VERSION ""

NS_ :

BS_:

BU_: Receiver ChassisBus VehicleBus PartyBus

BO_ 12 ID00CUI_status: 8 VehicleBus
 SG_ UI_audioActive : 1|1@1+ (1,0) [0|1] ""  Receiver
 SG_ UI_autopilotTrial : 12|2@1+ (1,0) [0|3] ""  Receiver
 SG_ UI_bluetoothActive : 2|1@1+ (1,0) [0|1] ""  Receiver
 SG_ UI_cameraActive : 41|1@1+ (1,0) [0|1] ""  Receiver
 SG_ UI_cellActive : 3|1@1+ (1,0) [0|1] ""  Receiver
 SG_ UI_cellConnected : 10|1@1+ (1,0) [0|1] ""  Receiver
 SG_ UI_cellNetworkTechnology : 19|4@1+ (1,0) [0|15] ""  Receiver
 SG_ UI_cellReceiverPower : 24|8@1+ (1,-128) [-128|127] "dB"  Receiver
 SG_ UI_cellSignalBars : 42|3@1+ (1,0) [0|7] ""  Receiver
 SG_ UI_cpuTemperature : 56|8@1- (1,40) [-20|100] "C"  Receiver
 SG_ UI_developmentCar : 40|1@1+ (1,0) [0|1] ""  Receiver
 SG_ UI_displayOn : 5|1@1+ (1,0) [0|1] ""  Receiver
 SG_ UI_displayReady : 4|1@1+ (1,0) [0|1] ""  Receiver
 SG_ UI_factoryReset : 14|2@1+ (1,0) [0|3] ""  Receiver
 SG_ UI_falseTouchCounter : 32|8@1+ (1,0) [0|255] "1"  Receiver
 SG_ UI_gpsActive : 16|1@1+ (1,0) [0|1] ""  Receiver
 SG_ UI_pcbTemperature : 48|8@1- (1,40) [-20|100] "C"  Receiver
 SG_ UI_radioActive : 18|1@1+ (1,0) [0|1] ""  Receiver
 SG_ UI_readyForDrive : 9|1@1+ (1,0) [0|1] ""  Receiver
 SG_ UI_screenshotActive : 17|1@1+ (1,0) [0|1] ""  Receiver
 SG_ UI_systemActive : 8|1@1+ (1,0) [0|1] ""  Receiver
 SG_ UI_touchActive : 0|1@1+ (1,0) [0|1] ""  Receiver
 SG_ UI_vpnActive : 11|1@1+ (1,0) [0|1] ""  Receiver
 SG_ UI_wifiActive : 6|1@1+ (1,0) [0|1] ""  Receiver
 SG_ UI_wifiConnected : 7|1@1+ (1,0) [0|1] ""  Receiver

BO_ 851 ID353UI_status: 8 VehicleBus
 SG_ UI_audioActive : 1|1@1+ (1,0) [0|1] ""  Receiver
 SG_ UI_autopilotTrial : 12|2@1+ (1,0) [0|3] ""  Receiver
 SG_ UI_bluetoothActive : 2|1@1+ (1,0) [0|1] ""  Receiver
 SG_ UI_cameraActive : 41|1@1+ (1,0) [0|1] ""  Receiver
 SG_ UI_cellActive : 3|1@1+ (1,0) [0|1] ""  Receiver
 SG_ UI_cellConnected : 10|1@1+ (1,0) [0|1] ""  Receiver
 SG_ UI_cellNetworkTechnology : 19|4@1+ (1,0) [0|15] ""  Receiver
 SG_ UI_cellReceiverPower : 24|8@1+ (1,-128) [-128|127] "dB"  Receiver
 SG_ UI_cellSignalBars : 42|3@1+ (1,0) [0|7] ""  Receiver
 SG_ UI_cpuTemperature : 56|8@1- (1,40) [-20|100] "C"  Receiver
 SG_ UI_developmentCar : 40|1@1+ (1,0) [0|1] ""  Receiver
 SG_ UI_displayOn : 5|1@1+ (1,0) [0|1] ""  Receiver
 SG_ UI_displayReady : 4|1@1+ (1,0) [0|1] ""  Receiver
 SG_ UI_factoryReset : 14|2@1+ (1,0) [0|3] ""  Receiver
 SG_ UI_falseTouchCounter : 32|8@1+ (1,0) [0|255] "1"  Receiver
 SG_ UI_gpsActive : 16|1@1+ (1,0) [0|1] ""  Receiver
 SG_ UI_pcbTemperature : 48|8@1- (1,40) [-20|100] "C"  Receiver
 SG_ UI_radioActive : 18|1@1+ (1,0) [0|1] ""  Receiver
 SG_ UI_readyForDrive : 9|1@1+ (1,0) [0|1] ""  Receiver
 SG_ UI_screenshotActive : 17|1@1+ (1,0) [0|1] ""  Receiver
 SG_ UI_systemActive : 8|1@1+ (1,0) [0|1] ""  Receiver
 SG_ UI_touchActive : 0|1@1+ (1,0) [0|1] ""  Receiver
 SG_ UI_vpnActive : 11|1@1+ (1,0) [0|1] ""  Receiver
 SG_ UI_wifiActive : 6|1@1+ (1,0) [0|1] ""  Receiver
 SG_ UI_wifiConnected : 7|1@1+ (1,0) [0|1] ""  Receiver

BO_ 22 ID016DI_bmsRequest: 1 VehicleBus
 SG_ DI_bmsOpenContactorsRequest : 4|1@1+ (1,0) [0|1] ""  Receiver
 SG_ DI_bmsRequestInterfaceVersion : 0|4@1+ (1,0) [0|15] ""  Receiver

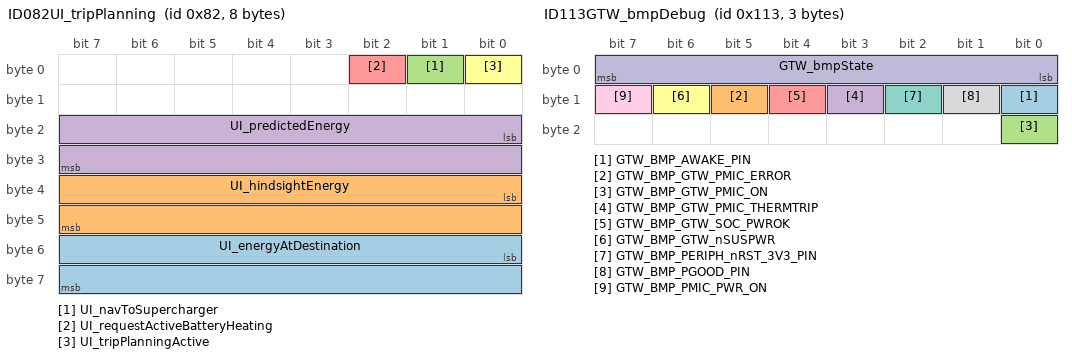
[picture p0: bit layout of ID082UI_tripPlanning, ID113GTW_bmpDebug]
BO_ 130 ID082UI_tripPlanning: 8 VehicleBus
 SG_ UI_energyAtDestination : 48|16@1- (0.01,0) [-327.67|327.67] "kWh"  Receiver
 SG_ UI_hindsightEnergy : 32|16@1- (0.01,0) [-327.67|327.67] "kWh"  Receiver
 SG_ UI_navToSupercharger : 1|1@1+ (1,0) [0|1] ""  Receiver
 SG_ UI_predictedEnergy : 16|16@1- (0.01,0) [-327.67|327.67] "kWh"  Receiver
 SG_ UI_requestActiveBatteryHeating : 2|1@1+ (1,0) [0|1] ""  Receiver
 SG_ UI_tripPlanningActive : 0|1@1+ (1,0) [0|1] ""  Receiver

BO_ 258 ID102VCLEFT_doorStatus: 8 VehicleBus
 SG_ VCLEFT_frontHandlePWM : 16|7@1+ (1,0) [0|100] "%"  Receiver
 SG_ VCLEFT_frontHandlePulled : 10|1@1+ (1,0) [0|1] ""  Receiver
 SG_ VCLEFT_frontHandlePulledPersist : 62|1@1+ (1,0) [0|1] ""  Receiver
 SG_ VCLEFT_frontIntSwitchPressed : 31|1@1+ (1,0) [0|1] ""  Receiver
 SG_ VCLEFT_frontLatchStatus : 0|4@1+ (1,0) [0|8] ""  Receiver
 SG_ VCLEFT_frontLatchSwitch : 8|1@1+ (1,0) [0|1] ""  Receiver
 SG_ VCLEFT_frontRelActuatorSwitch : 12|1@1+ (1,0) [0|1] ""  Receiver
 SG_ VCLEFT_mirrorDipped : 61|1@1+ (1,0) [0|1] ""  Receiver
 SG_ VCLEFT_mirrorFoldState : 52|3@1+ (1,0) [0|4] ""  Receiver
 SG_ VCLEFT_mirrorHeatState : 58|3@1+ (1,0) [0|4] ""  Receiver
 SG_ VCLEFT_mirrorRecallState : 55|3@1+ (1,0) [0|5] ""  Receiver
 SG_ VCLEFT_mirrorState : 49|3@1+ (1,0) [0|4] ""  Receiver
 SG_ VCLEFT_mirrorTiltXPosition : 33|8@1+ (0.02,0) [0|5] "V"  Receiver
 SG_ VCLEFT_mirrorTiltYPosition : 41|8@1+ (0.02,0) [0|5] "V"  Receiver
 SG_ VCLEFT_rearHandlePWM : 24|7@1+ (1,0) [0|100] "%"  Receiver
 SG_ VCLEFT_rearHandlePulled : 11|1@1+ (1,0) [0|1] ""  Receiver
 SG_ VCLEFT_rearIntSwitchPressed : 32|1@1+ (1,0) [0|1] ""  Receiver
 SG_ VCLEFT_rearLatchStatus : 4|4@1+ (1,0) [0|8] ""  Receiver
 SG_ VCLEFT_rearLatchSwitch : 9|1@1+ (1,0) [0|1] ""  Receiver
 SG_ VCLEFT_rearRelActuatorSwitch : 13|1@1+ (1,0) [0|1] ""  Receiver

BO_ 259 ID103VCRIGHT_doorStatus: 8 VehicleBus
 SG_ VCRIGHT_frontHandlePWM : 14|7@1+ (1,0) [0|100] "%"  Receiver
 SG_ VCRIGHT_frontHandlePulled : 10|1@1+ (1,0) [0|1] ""  Receiver
 SG_ VCRIGHT_frontHandlePulledPersist : 30|1@1+ (1,0) [0|1] ""  Receiver
 SG_ VCRIGHT_frontIntSwitchPressed : 31|1@1+ (1,0) [0|1] ""  Receiver
 SG_ VCRIGHT_frontLatchStatus : 0|4@1+ (1,0) [0|8] ""  Receiver
 SG_ VCRIGHT_frontLatchSwitch : 8|1@1+ (1,0) [0|1] ""  Receiver
 SG_ VCRIGHT_frontRelActuatorSwitch : 12|1@1+ (1,0) [0|1] ""  Receiver
 SG_ VCRIGHT_mirrorDipped : 63|1@1+ (1,0) [0|1] ""  Receiver
 SG_ VCRIGHT_mirrorFoldState : 52|3@1+ (1,0) [0|4] ""  Receiver
 SG_ VCRIGHT_mirrorRecallState : 60|3@1+ (1,0) [0|5] ""  Receiver
 SG_ VCRIGHT_mirrorState : 49|3@1+ (1,0) [0|4] ""  Receiver
 SG_ VCRIGHT_mirrorTiltXPosition : 33|8@1+ (0.02,0) [0|5] "V"  Receiver
 SG_ VCRIGHT_mirrorTiltYPosition : 41|8@1+ (0.02,0) [0|5] "V"  Receiver
 SG_ VCRIGHT_rearHandlePWM : 21|7@1+ (1,0) [0|100] "%"  Receiver
 SG_ VCRIGHT_rearHandlePulled : 11|1@1+ (1,0) [0|1] ""  Receiver
 SG_ VCRIGHT_rearIntSwitchPressed : 32|1@1+ (1,0) [0|1] ""  Receiver
 SG_ VCRIGHT_rearLatchStatus : 4|4@1+ (1,0) [0|8] ""  Receiver
 SG_ VCRIGHT_rearLatchSwitch : 9|1@1+ (1,0) [0|1] ""  Receiver
 SG_ VCRIGHT_rearRelActuatorSwitch : 13|1@1+ (1,0) [0|1] ""  Receiver
 SG_ VCRIGHT_reservedForBackCompat : 28|2@1+ (1,0) [0|3] ""  Receiver
 SG_ VCRIGHT_trunkLatchStatus : 56|4@1+ (1,0) [0|8] ""  Receiver

BO_ 275 ID113GTW_bmpDebug: 3 VehicleBus
 SG_ GTW_BMP_AWAKE_PIN : 8|1@1+ (1,0) [0|1] ""  Receiver
 SG_ GTW_BMP_GTW_PMIC_ERROR : 13|1@1+ (1,0) [0|1] ""  Receiver
 SG_ GTW_BMP_GTW_PMIC_ON : 16|1@1+ (1,0) [0|1] ""  Receiver
 SG_ GTW_BMP_GTW_PMIC_THERMTRIP : 11|1@1+ (1,0) [0|1] ""  Receiver
 SG_ GTW_BMP_GTW_SOC_PWROK : 12|1@1+ (1,0) [0|1] ""  Receiver
 SG_ GTW_BMP_GTW_nSUSPWR : 14|1@1+ (1,0) [0|1] ""  Receiver
 SG_ GTW_BMP_PERIPH_nRST_3V3_PIN : 10|1@1+ (1,0) [0|1] ""  Receiver
 SG_ GTW_BMP_PGOOD_PIN : 9|1@1+ (1,0) [0|1] ""  Receiver
 SG_ GTW_BMP_PMIC_PWR_ON : 15|1@1+ (1,0) [0|1] ""  Receiver
 SG_ GTW_bmpState : 7|8@0+ (1,0) [0|255] ""  Receiver

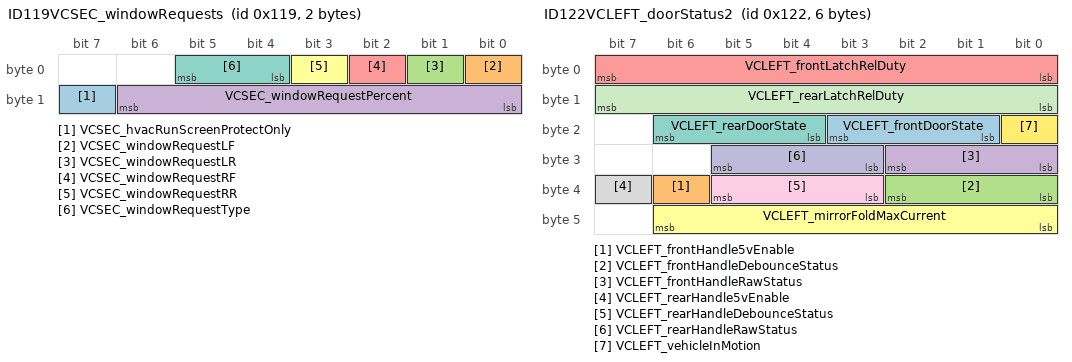
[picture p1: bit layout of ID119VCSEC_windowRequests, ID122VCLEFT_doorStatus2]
BO_ 281 ID119VCSEC_windowRequests: 2 VehicleBus
 SG_ VCSEC_hvacRunScreenProtectOnly : 15|1@1+ (1,0) [0|1] ""  Receiver
 SG_ VCSEC_windowRequestLF : 0|1@1+ (1,0) [0|1] ""  Receiver
 SG_ VCSEC_windowRequestLR : 1|1@1+ (1,0) [0|1] ""  Receiver
 SG_ VCSEC_windowRequestPercent : 8|7@1+ (1,0) [0|127] ""  Receiver
 SG_ VCSEC_windowRequestRF : 2|1@1+ (1,0) [0|1] ""  Receiver
 SG_ VCSEC_windowRequestRR : 3|1@1+ (1,0) [0|1] ""  Receiver
 SG_ VCSEC_windowRequestType : 4|2@1+ (1,0) [0|3] ""  Receiver

BO_ 290 ID122VCLEFT_doorStatus2: 6 VehicleBus
 SG_ VCLEFT_frontDoorState : 17|3@1+ (1,0) [0|4] ""  Receiver
 SG_ VCLEFT_frontHandle5vEnable : 38|1@1+ (1,0) [0|1] ""  Receiver
 SG_ VCLEFT_frontHandleDebounceStatus : 32|3@1+ (1,0) [0|5] ""  Receiver
 SG_ VCLEFT_frontHandleRawStatus : 24|3@1+ (1,0) [0|5] ""  Receiver
 SG_ VCLEFT_frontLatchRelDuty : 0|8@1+ (1,0) [0|255] "%"  Receiver
 SG_ VCLEFT_mirrorFoldMaxCurrent : 40|7@1- (0.046,0) [-2.944|2.898] "A"  Receiver
 SG_ VCLEFT_rearDoorState : 20|3@1+ (1,0) [0|4] ""  Receiver
 SG_ VCLEFT_rearHandle5vEnable : 39|1@1+ (1,0) [0|1] ""  Receiver
 SG_ VCLEFT_rearHandleDebounceStatus : 35|3@1+ (1,0) [0|5] ""  Receiver
 SG_ VCLEFT_rearHandleRawStatus : 27|3@1+ (1,0) [0|5] ""  Receiver
 SG_ VCLEFT_rearLatchRelDuty : 8|8@1+ (1,0) [0|255] "%"  Receiver
 SG_ VCLEFT_vehicleInMotion : 16|1@1+ (1,0) [0|1] ""  Receiver

BO_ 291 ID123UI_alertMatrix1: 8 VehicleBus
 SG_ UI_a001_DriverDoorOpen : 0|1@1+ (1,0) [0|1] ""  Receiver
 SG_ UI_a002_DoorOpen : 1|1@1+ (1,0) [0|1] ""  Receiver
 SG_ UI_a003_TrunkOpen : 2|1@1+ (1,0) [0|1] ""  Receiver
 SG_ UI_a004_FrunkOpen : 3|1@1+ (1,0) [0|1] ""  Receiver
 SG_ UI_a005_HeadlightsOnDoorOpen : 4|1@1+ (1,0) [0|1] ""  Receiver
 SG_ UI_a006_RemoteServiceAlert : 5|1@1+ (1,0) [0|1] ""  Receiver
 SG_ UI_a007_SoftPackConfigMismatch : 6|1@1+ (1,0) [0|1] ""  Receiver
 SG_ UI_a008_TouchScreenError : 7|1@1+ (1,0) [0|1] ""  Receiver
 SG_ UI_a009_SquashfsError : 8|1@1+ (1,0) [0|1] ""  Receiver
 SG_ UI_a010_MapsMissing : 9|1@1+ (1,0) [0|1] ""  Receiver
 SG_ UI_a011_IncorrectMap : 10|1@1+ (1,0) [0|1] ""  Receiver
 SG_ UI_a012_NotOnPrivateProperty : 11|1@1+ (1,0) [0|1] ""  Receiver
 SG_ UI_a013_TPMSHardWarning : 12|1@1+ (1,0) [0|1] ""  Receiver
 SG_ UI_a014_TPMSSoftWarning : 13|1@1+ (1,0) [0|1] ""  Receiver
 SG_ UI_a015_TPMSOverPressureWarning : 14|1@1+ (1,0) [0|1] ""  Receiver
 SG_ UI_a016_TPMSTemperatureWarning : 15|1@1+ (1,0) [0|1] ""  Receiver
 SG_ UI_a017_TPMSSystemFault : 16|1@1+ (1,0) [0|1] ""  Receiver
 SG_ UI_a018_SlipStartOn : 17|1@1+ (1,0) [0|1] ""  Receiver
 SG_ UI_a019_ParkBrakeFault : 18|1@1+ (1,0) [0|1] ""  Receiver
 SG_ UI_a020_SteeringReduced : 19|1@1+ (1,0) [0|1] ""  Receiver
 SG_ UI_a021_RearSeatbeltUnbuckled : 20|1@1+ (1,0) [0|1] ""  Receiver
 SG_ UI_a022_ApeFusesEtc : 21|1@1+ (1,0) [0|1] ""  Receiver
 SG_ UI_a023_CellInternetCheckFailed : 22|1@1+ (1,0) [0|1] ""  Receiver
 SG_ UI_a024_WifiInternetCheckFailed : 23|1@1+ (1,0) [0|1] ""  Receiver
 SG_ UI_a025_WifiOnlineCheckFailed : 24|1@1+ (1,0) [0|1] ""  Receiver
 SG_ UI_a026_ModemResetLoopDetected : 25|1@1+ (1,0) [0|1] ""  Receiver
 SG_ UI_a027_AutoSteerMIA : 26|1@1+ (1,0) [0|1] ""  Receiver
 SG_ UI_a028_FrontTrunkPopupClosed : 27|1@1+ (1,0) [0|1] ""  Receiver
 SG_ UI_a029_ModemMIA : 28|1@1+ (1,0) [0|1] ""  Receiver
 SG_ UI_a030_ModemVMCrash : 29|1@1+ (1,0) [0|1] ""  Receiver
 SG_ UI_a031_BrakeFluidLow : 30|1@1+ (1,0) [0|1] ""  Receiver
 SG_ UI_a032_CellModemRecoveryResets : 31|1@1+ (1,0) [0|1] ""  Receiver
 SG_ UI_a033_ApTrialExpired : 32|1@1+ (1,0) [0|1] ""  Receiver
 SG_ UI_a034_WakeupProblem : 33|1@1+ (1,0) [0|1] ""  Receiver
 SG_ UI_a035_AudioWatchdogKernelError : 34|1@1+ (1,0) [0|1] ""  Receiver
 SG_ UI_a036_AudioWatchdogHfpError : 35|1@1+ (1,0) [0|1] ""  Receiver
 SG_ UI_a037_AudioWatchdogXrunStormEr : 36|1@1+ (1,0) [0|1] ""  Receiver
 SG_ UI_a038_AudioWatchdogA2bI2cLocku : 37|1@1+ (1,0) [0|1] ""  Receiver
 SG_ UI_a039_AudioA2bNeedRediscovery : 38|1@1+ (1,0) [0|1] ""  Receiver
 SG_ UI_a040_HomelinkTransmit : 39|1@1+ (1,0) [0|1] ""  Receiver
 SG_ UI_a041_AudioDmesgXrun : 40|1@1+ (1,0) [0|1] ""  Receiver
 SG_ UI_a042_AudioDmesgRtThrottling : 41|1@1+ (1,0) [0|1] ""  Receiver
 SG_ UI_a043_InvalidMapDataOverride : 42|1@1+ (1,0) [0|1] ""  Receiver
 SG_ UI_a044_AudioDmesgDspException : 43|1@1+ (1,0) [0|1] ""  Receiver
 SG_ UI_a045_ECallNeedsService : 44|1@1+ (1,0) [0|1] ""  Receiver
 SG_ UI_a046_BackupCameraStreamError : 45|1@1+ (1,0) [0|1] ""  Receiver
 SG_ UI_a047_CellRoamingDisallowed : 46|1@1+ (1,0) [0|1] ""  Receiver
 SG_ UI_a048_AudioPremiumAmpCheckFail : 47|1@1+ (1,0) [0|1] ""  Receiver
 SG_ UI_a049_BrakeShiftRequired : 48|1@1+ (1,0) [0|1] ""  Receiver
 SG_ UI_a050_BackupCameraIPUTimeout : 49|1@1+ (1,0) [0|1] ""  Receiver
 SG_ UI_a051_BackupCameraFrameTimeout : 50|1@1+ (1,0) [0|1] ""  Receiver
 SG_ UI_a052_KernelPanicReported : 51|1@1+ (1,0) [0|1] ""  Receiver
 SG_ UI_a053_QtCarExitError : 52|1@1+ (1,0) [0|1] ""  Receiver
 SG_ UI_a054_AudioBoostPowerBad : 53|1@1+ (1,0) [0|1] ""  Receiver
 SG_ UI_a055_ManualECallDisabled : 54|1@1+ (1,0) [0|1] ""  Receiver
 SG_ UI_a056_ManualECallButtonDisconn : 55|1@1+ (1,0) [0|1] ""  Receiver
 SG_ UI_a057_CellAntennaDisconnected : 56|1@1+ (1,0) [0|1] ""  Receiver
 SG_ UI_a058_GPSAntennaDisconnected : 57|1@1+ (1,0) [0|1] ""  Receiver
 SG_ UI_a059_ECallSpeakerDisconnected : 58|1@1+ (1,0) [0|1] ""  Receiver
 SG_ UI_a060_ECallMicDisconnected : 59|1@1+ (1,0) [0|1] ""  Receiver
 SG_ UI_a061_SIMTestFailed : 60|1@1+ (1,0) [0|1] ""  Receiver
 SG_ UI_a062_ENSTestFailed : 61|1@1+ (1,0) [0|1] ""  Receiver
 SG_ UI_a063_CellularTestFailed : 62|1@1+ (1,0) [0|1] ""  Receiver
 SG_ UI_a064_ModemFirmwareTestFailed : 63|1@1+ (1,0) [0|1] ""  Receiver

BO_ 322 ID142VCLEFT_liftgateStatus: 8 VehicleBus
 SG_ VCLEFT_liftgateStatusIndex M : 0|2@1+ (1,0) [0|2] ""  Receiver
 SG_ VCLEFT_liftgateLatchRequest m0 : 61|3@1+ (1,0) [0|4] ""  Receiver
 SG_ VCLEFT_liftgateMvmntNotAllowedCo m0 : 14|3@1+ (1,0) [0|5] ""  Receiver
 SG_ VCLEFT_liftgatePhysicalChimeRequ m0 : 21|3@1+ (1,0) [0|4] ""  Receiver
 SG_ VCLEFT_liftgatePosition m1 : 21|7@1- (1,46) [-5|95] "deg"  Receiver
 SG_ VCLEFT_liftgatePositionCalibrate m0 : 17|1@1+ (1,0) [0|1] ""  Receiver
 SG_ VCLEFT_liftgateRequestSource m0 : 7|3@1+ (1,0) [0|7] ""  Receiver
 SG_ VCLEFT_liftgateSpeed m1 : 28|10@1- (0.1,0) [-30|30] "deg/s"  Receiver
 SG_ VCLEFT_liftgateState m0 : 3|4@1+ (1,0) [0|12] ""  Receiver
 SG_ VCLEFT_liftgateStoppingCondition m0 : 10|4@1+ (1,0) [0|11] ""  Receiver
 SG_ VCLEFT_liftgateStrutCurrent m1 : 11|10@1- (0.1,0) [-30|30] "A"  Receiver
 SG_ VCLEFT_liftgateStrutDutyCycle m1 : 3|8@1- (1,0) [-100|100] "%"  Receiver
 SG_ VCLEFT_liftgateUIChimeRequest m0 : 18|3@1+ (1,0) [0|4] ""  Receiver

BO_ 470 ID1D6DI_limits: 5 VehicleBus
 SG_ DI_limitBaseSpeed : 15|1@1+ (1,0) [0|1] ""  Receiver
 SG_ DI_limitClutch : 28|1@1+ (1,0) [0|1] ""  Receiver
 SG_ DI_limitDcCapTemp : 17|1@1+ (1,0) [0|1] ""  Receiver
 SG_ DI_limitDeltaFluidTemp : 5|1@1+ (1,0) [0|1] ""  Receiver
 SG_ DI_limitDiff : 22|1@1+ (1,0) [0|1] ""  Receiver
 SG_ DI_limitDischargePower : 6|1@1+ (1,0) [0|1] ""  Receiver
 SG_ DI_limitDriveTorque : 10|1@1+ (1,0) [0|1] ""  Receiver
 SG_ DI_limitGracefulPowerOff : 23|1@1+ (1,0) [0|1] ""  Receiver
 SG_ DI_limitIBat : 16|1@1+ (1,0) [0|1] ""  Receiver
 SG_ DI_limitIGBTJunctTemp : 24|1@1+ (1,0) [0|1] ""  Receiver
 SG_ DI_limitInverterTemp : 1|1@1+ (1,0) [0|1] ""  Receiver
 SG_ DI_limitLimpMode : 4|1@1+ (1,0) [0|1] ""  Receiver
 SG_ DI_limitMotorCurrent : 8|1@1+ (1,0) [0|1] ""  Receiver
 SG_ DI_limitMotorSpeed : 20|1@1+ (1,0) [0|1] ""  Receiver
 SG_ DI_limitMotorVoltage : 9|1@1+ (1,0) [0|1] ""  Receiver
 SG_ DI_limitObstacleDetection : 29|1@1+ (1,0) [0|1] ""  Receiver
 SG_ DI_limitOilPumpFluidTemp : 26|1@1+ (1,0) [0|1] ""  Receiver
 SG_ DI_limitPCBTemp : 0|1@1+ (1,0) [0|1] ""  Receiver
 SG_ DI_limitPoleTemp : 3|1@1+ (1,0) [0|1] ""  Receiver
 SG_ DI_limitRegenPower : 7|1@1+ (1,0) [0|1] ""  Receiver
 SG_ DI_limitRegenTorque : 11|1@1+ (1,0) [0|1] ""  Receiver
 SG_ DI_limitRotorTemp : 36|1@1+ (1,0) [0|1] ""  Receiver
 SG_ DI_limitShift : 14|1@1+ (1,0) [0|1] ""  Receiver
 SG_ DI_limitShockTorque : 25|1@1+ (1,0) [0|1] ""  Receiver
 SG_ DI_limitStatorFrequency : 27|1@1+ (1,0) [0|1] ""  Receiver
 SG_ DI_limitStatorTemp : 2|1@1+ (1,0) [0|1] ""  Receiver
 SG_ DI_limitTCDrive : 12|1@1+ (1,0) [0|1] ""  Receiver
 SG_ DI_limitTCRegen : 13|1@1+ (1,0) [0|1] ""  Receiver
 SG_ DI_limitVBatHigh : 19|1@1+ (1,0) [0|1] ""  Receiver
 SG_ DI_limitVBatLow : 18|1@1+ (1,0) [0|1] ""  Receiver
 SG_ DI_limitVehicleSpeed : 21|1@1+ (1,0) [0|1] ""  Receiver
 SG_ DI_limitdcLinkCapTemp : 33|1@1+ (1,0) [0|1] ""  Receiver
 SG_ DI_limithvDcCableTemp : 37|1@1+ (1,0) [0|1] ""  Receiver
 SG_ DI_limitnegDcBusbarTemp : 34|1@1+ (1,0) [0|1] ""  Receiver
 SG_ DI_limitphaseOutBusBarWeldTemp : 31|1@1+ (1,0) [0|1] ""  Receiver
 SG_ DI_limitphaseOutBusbarTemp : 30|1@1+ (1,0) [0|1] ""  Receiver
 SG_ DI_limitphaseOutLugTemp : 32|1@1+ (1,0) [0|1] ""  Receiver
 SG_ DI_limitposDcBusbarTemp : 35|1@1+ (1,0) [0|1] ""  Receiver

BO_ 522 ID20AHVP_contactorState: 6 VehicleBus
 SG_ HVP_dcLinkAllowedToEnergize : 36|1@1+ (1,0) [0|1] ""  Receiver
 SG_ HVP_fcContNegativeAuxOpen : 7|1@1+ (1,0) [0|1] ""  Receiver
 SG_ HVP_fcContNegativeState : 12|3@1+ (1,0) [0|7] ""  Receiver
 SG_ HVP_fcContPositiveAuxOpen : 6|1@1+ (1,0) [0|1] ""  Receiver
 SG_ HVP_fcContPositiveState : 16|3@1+ (1,0) [0|7] ""  Receiver
 SG_ HVP_fcContactorSetState : 19|4@1+ (1,0) [0|9] ""  Receiver
 SG_ HVP_fcCtrsClosingAllowed : 29|1@1+ (1,0) [0|1] ""  Receiver
 SG_ HVP_fcCtrsOpenNowRequested : 27|1@1+ (1,0) [0|1] ""  Receiver
 SG_ HVP_fcCtrsOpenRequested : 28|1@1+ (1,0) [0|1] ""  Receiver
 SG_ HVP_fcCtrsRequestStatus : 24|2@1+ (1,0) [0|2] ""  Receiver
 SG_ HVP_fcCtrsResetRequestRequired : 26|1@1+ (1,0) [0|1] ""  Receiver
 SG_ HVP_fcLinkAllowedToEnergize : 44|2@1+ (1,0) [0|2] ""  Receiver
 SG_ HVP_hvilStatus : 40|4@1+ (1,0) [0|9] ""  Receiver
 SG_ HVP_packContNegativeState : 0|3@1+ (1,0) [0|7] ""  Receiver
 SG_ HVP_packContPositiveState : 3|3@1+ (1,0) [0|7] ""  Receiver
 SG_ HVP_packContactorSetState : 8|4@1+ (1,0) [0|9] ""  Receiver
 SG_ HVP_packCtrsClosingAllowed : 35|1@1+ (1,0) [0|1] ""  Receiver
 SG_ HVP_packCtrsOpenNowRequested : 33|1@1+ (1,0) [0|1] ""  Receiver
 SG_ HVP_packCtrsOpenRequested : 34|1@1+ (1,0) [0|1] ""  Receiver
 SG_ HVP_packCtrsRequestStatus : 30|2@1+ (1,0) [0|2] ""  Receiver
 SG_ HVP_packCtrsResetRequestRequired : 32|1@1+ (1,0) [0|1] ""  Receiver
 SG_ HVP_pyroTestInProgress : 37|1@1+ (1,0) [0|1] ""  Receiver

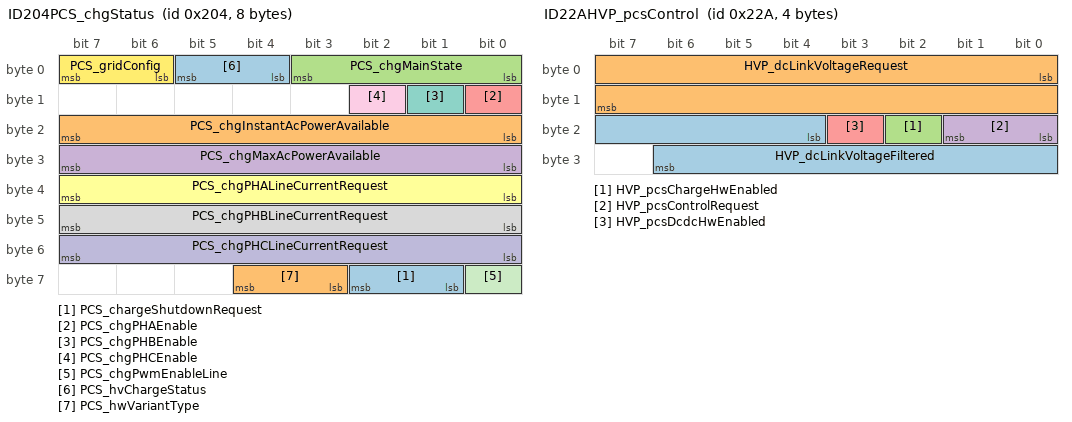
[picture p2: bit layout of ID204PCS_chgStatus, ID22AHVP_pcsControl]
BO_ 516 ID204PCS_chgStatus: 8 VehicleBus
 SG_ PCS_chargeShutdownRequest : 57|2@1+ (1,0) [0|2] ""  Receiver
 SG_ PCS_chgInstantAcPowerAvailable : 16|8@1+ (0.1,0) [0|20] "kW"  Receiver
 SG_ PCS_chgMainState : 0|4@1+ (1,0) [0|9] ""  Receiver
 SG_ PCS_chgMaxAcPowerAvailable : 24|8@1+ (0.1,0) [0|20] "kW"  Receiver
 SG_ PCS_chgPHAEnable : 8|1@1+ (1,0) [0|1] ""  Receiver
 SG_ PCS_chgPHALineCurrentRequest : 32|8@1+ (0.1,0) [0|20] "A"  Receiver
 SG_ PCS_chgPHBEnable : 9|1@1+ (1,0) [0|1] ""  Receiver
 SG_ PCS_chgPHBLineCurrentRequest : 40|8@1+ (0.1,0) [0|20] "A"  Receiver
 SG_ PCS_chgPHCEnable : 10|1@1+ (1,0) [0|1] ""  Receiver
 SG_ PCS_chgPHCLineCurrentRequest : 48|8@1+ (0.1,0) [0|20] "A"  Receiver
 SG_ PCS_chgPwmEnableLine : 56|1@1+ (1,0) [0|1] ""  Receiver
 SG_ PCS_gridConfig : 6|2@1+ (1,0) [0|3] ""  Receiver
 SG_ PCS_hvChargeStatus : 4|2@1+ (1,0) [0|3] ""  Receiver
 SG_ PCS_hwVariantType : 59|2@1+ (1,0) [0|3] ""  Receiver

BO_ 554 ID22AHVP_pcsControl: 4 VehicleBus
 SG_ HVP_dcLinkVoltageFiltered : 20|11@1- (1,0) [-550|550] "V"  Receiver
 SG_ HVP_dcLinkVoltageRequest : 0|16@1- (0.1,0) [-550|550] "V"  Receiver
 SG_ HVP_pcsChargeHwEnabled : 18|1@1+ (1,0) [0|1] ""  Receiver
 SG_ HVP_pcsControlRequest : 16|2@1+ (1,0) [0|3] ""  Receiver
 SG_ HVP_pcsDcdcHwEnabled : 19|1@1+ (1,0) [0|1] ""  Receiver

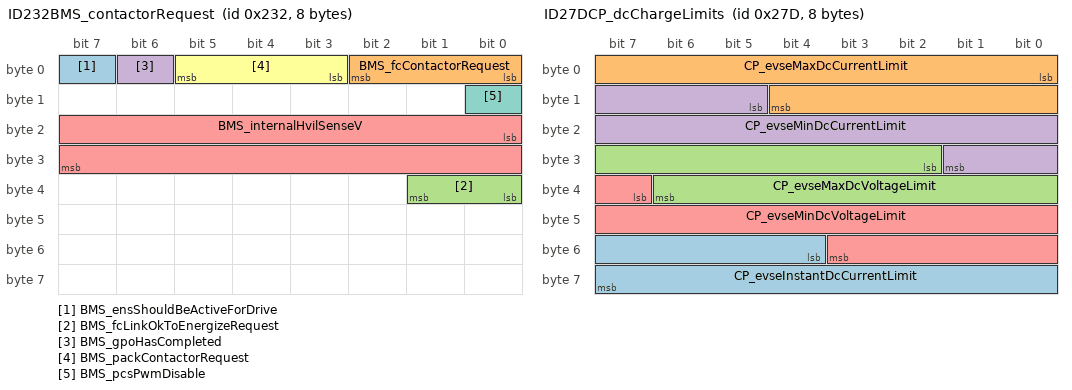
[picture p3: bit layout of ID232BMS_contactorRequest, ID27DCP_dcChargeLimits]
BO_ 562 ID232BMS_contactorRequest: 8 VehicleBus
 SG_ BMS_ensShouldBeActiveForDrive : 7|1@1+ (1,0) [0|1] ""  Receiver
 SG_ BMS_fcContactorRequest : 0|3@1+ (1,0) [0|5] ""  Receiver
 SG_ BMS_fcLinkOkToEnergizeRequest : 32|2@1+ (1,0) [0|2] ""  Receiver
 SG_ BMS_gpoHasCompleted : 6|1@1+ (1,0) [0|1] ""  Receiver
 SG_ BMS_internalHvilSenseV : 16|16@1+ (0.001,0) [0|65.534] "V"  Receiver
 SG_ BMS_packContactorRequest : 3|3@1+ (1,0) [0|5] ""  Receiver
 SG_ BMS_pcsPwmDisable : 8|1@1+ (1,0) [0|1] ""  Receiver

BO_ 627 ID273UI_vehicleControl: 8 VehicleBus
 SG_ UI_accessoryPowerRequest : 0|1@1+ (1,0) [0|1] ""  Receiver
 SG_ UI_alarmEnabled : 20|1@1+ (1,0) [0|1] ""  Receiver
 SG_ UI_ambientLightingEnabled : 40|1@1+ (1,0) [0|1] ""  Receiver
 SG_ UI_autoFoldMirrorsOn : 52|1@1+ (1,0) [0|1] ""  Receiver
 SG_ UI_autoHighBeamEnabled : 41|1@1+ (1,0) [0|1] ""  Receiver
 SG_ UI_childDoorLockOn : 16|1@1+ (1,0) [0|1] ""  Receiver
 SG_ UI_displayBrightnessLevel : 32|8@1+ (0.5,0) [0|127] "%"  Receiver
 SG_ UI_domeLightSwitch : 59|2@1+ (1,0) [0|2] ""  Receiver
 SG_ UI_driveStateRequest : 62|1@1+ (1,0) [0|1] ""  Receiver
 SG_ UI_frontFogSwitch : 3|1@1+ (1,0) [0|1] ""  Receiver
 SG_ UI_frontLeftSeatHeatReq : 42|2@1+ (1,0) [0|3] ""  Receiver
 SG_ UI_frontRightSeatHeatReq : 44|2@1+ (1,0) [0|3] ""  Receiver
 SG_ UI_frunkRequest : 5|1@1+ (1,0) [0|1] ""  Receiver
 SG_ UI_globalUnlockOn : 15|1@1+ (1,0) [0|1] ""  Receiver
 SG_ UI_honkHorn : 61|1@1+ (1,0) [0|1] ""  Receiver
 SG_ UI_intrusionSensorOn : 21|1@1+ (1,0) [0|1] ""  Receiver
 SG_ UI_lockRequest : 17|3@1+ (1,0) [0|7] ""  Receiver
 SG_ UI_mirrorDipOnReverse : 53|1@1+ (1,0) [0|1] ""  Receiver
 SG_ UI_mirrorFoldRequest : 24|2@1+ (1,0) [0|3] ""  Receiver
 SG_ UI_mirrorHeatRequest : 26|1@1+ (1,0) [0|1] ""  Receiver
 SG_ UI_powerOff : 31|1@1+ (1,0) [0|1] ""  Receiver
 SG_ UI_rearCenterSeatHeatReq : 48|2@1+ (1,0) [0|3] ""  Receiver
 SG_ UI_rearFogSwitch : 23|1@1+ (1,0) [0|1] ""  Receiver
 SG_ UI_rearLeftSeatHeatReq : 46|2@1+ (1,0) [0|3] ""  Receiver
 SG_ UI_rearRightSeatHeatReq : 50|2@1+ (1,0) [0|3] ""  Receiver
 SG_ UI_rearWindowLockout : 63|1@1+ (1,0) [0|1] ""  Receiver
 SG_ UI_remoteClosureRequest : 54|2@1+ (1,0) [0|3] ""  Receiver
 SG_ UI_remoteStartRequest : 27|3@1+ (1,0) [0|4] ""  Receiver
 SG_ UI_seeYouHomeLightingOn : 30|1@1+ (1,0) [0|1] ""  Receiver
 SG_ UI_steeringBacklightEnabled : 8|1@1+ (1,0) [0|1] ""  Receiver
 SG_ UI_steeringButtonMode : 9|3@1+ (1,0) [0|5] ""  Receiver
 SG_ UI_stop12vSupport : 22|1@1+ (1,0) [0|1] ""  Receiver
 SG_ UI_summonActive : 4|1@1+ (1,0) [0|1] ""  Receiver
 SG_ UI_unlockOnPark : 14|1@1+ (1,0) [0|1] ""  Receiver
 SG_ UI_walkAwayLock : 13|1@1+ (1,0) [0|1] ""  Receiver
 SG_ UI_walkUpUnlock : 12|1@1+ (1,0) [0|1] ""  Receiver
 SG_ UI_wiperMode : 6|2@1+ (1,0) [0|3] ""  Receiver
 SG_ UI_wiperRequest : 56|3@1+ (1,0) [0|6] ""  Receiver

BO_ 637 ID27DCP_dcChargeLimits: 8 VehicleBus
 SG_ CP_evseInstantDcCurrentLimit : 52|12@1+ (0.146484,0) [0|599.854] "A"  Receiver
 SG_ CP_evseMaxDcCurrentLimit : 0|13@1+ (0.0732422,0) [0|599.927] "A"  Receiver
 SG_ CP_evseMaxDcVoltageLimit : 26|13@1+ (0.0732422,0) [0|599.927] "V"  Receiver
 SG_ CP_evseMinDcCurrentLimit : 13|13@1+ (0.0732422,0) [0|599.927] "A"  Receiver
 SG_ CP_evseMinDcVoltageLimit : 39|13@1+ (0.0732422,0) [0|599.927] "V"  Receiver

BO_ 701 ID2BDCP_dcPowerLimits: 4 VehicleBus
 SG_ CP_evseInstantDcPowerLimit : 0|13@1+ (0.0622559,0) [0|509.938] "kW"  Receiver
 SG_ CP_evseMaxDcPowerLimit : 16|13@1+ (0.0622559,0) [0|509.938] "kW"  Receiver

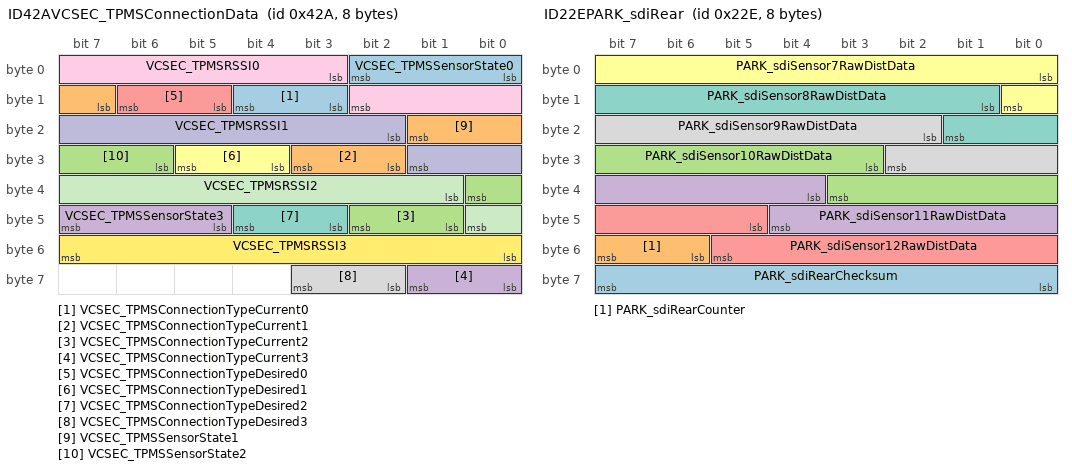
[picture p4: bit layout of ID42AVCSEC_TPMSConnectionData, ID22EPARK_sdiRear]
BO_ 1066 ID42AVCSEC_TPMSConnectionData: 8 VehicleBus
 SG_ VCSEC_TPMSConnectionTypeCurrent0 : 11|2@1+ (1,0) [0|2] ""  Receiver
 SG_ VCSEC_TPMSConnectionTypeCurrent1 : 26|2@1+ (1,0) [0|2] ""  Receiver
 SG_ VCSEC_TPMSConnectionTypeCurrent2 : 41|2@1+ (1,0) [0|2] ""  Receiver
 SG_ VCSEC_TPMSConnectionTypeCurrent3 : 56|2@1+ (1,0) [0|2] ""  Receiver
 SG_ VCSEC_TPMSConnectionTypeDesired0 : 13|2@1+ (1,0) [0|2] ""  Receiver
 SG_ VCSEC_TPMSConnectionTypeDesired1 : 28|2@1+ (1,0) [0|2] ""  Receiver
 SG_ VCSEC_TPMSConnectionTypeDesired2 : 43|2@1+ (1,0) [0|2] ""  Receiver
 SG_ VCSEC_TPMSConnectionTypeDesired3 : 58|2@1+ (1,0) [0|2] ""  Receiver
 SG_ VCSEC_TPMSRSSI0 : 3|8@1- (1,0) [-127|0] "dBm"  Receiver
 SG_ VCSEC_TPMSRSSI1 : 18|8@1- (1,0) [-127|0] "dBm"  Receiver
 SG_ VCSEC_TPMSRSSI2 : 33|8@1- (1,0) [-127|0] "dBm"  Receiver
 SG_ VCSEC_TPMSRSSI3 : 48|8@1- (1,0) [-127|0] "dBm"  Receiver
 SG_ VCSEC_TPMSSensorState0 : 0|3@1+ (1,0) [0|4] ""  Receiver
 SG_ VCSEC_TPMSSensorState1 : 15|3@1+ (1,0) [0|4] ""  Receiver
 SG_ VCSEC_TPMSSensorState2 : 30|3@1+ (1,0) [0|4] ""  Receiver
 SG_ VCSEC_TPMSSensorState3 : 45|3@1+ (1,0) [0|4] ""  Receiver

BO_ 558 ID22EPARK_sdiRear: 8 VehicleBus
 SG_ PARK_sdiRearChecksum : 56|8@1+ (1,0) [0|255] ""  Receiver
 SG_ PARK_sdiRearCounter : 54|2@1+ (1,0) [0|3] ""  Receiver
 SG_ PARK_sdiSensor10RawDistData : 27|9@1+ (1,0) [0|511] "cm"  Receiver
 SG_ PARK_sdiSensor11RawDistData : 36|9@1+ (1,0) [0|511] "cm"  Receiver
 SG_ PARK_sdiSensor12RawDistData : 45|9@1+ (1,0) [0|511] "cm"  Receiver
 SG_ PARK_sdiSensor7RawDistData : 0|9@1+ (1,0) [0|511] "cm"  Receiver
 SG_ PARK_sdiSensor8RawDistData : 9|9@1+ (1,0) [0|511] "cm"  Receiver
 SG_ PARK_sdiSensor9RawDistData : 18|9@1+ (1,0) [0|511] "cm"  Receiver

BO_ 605 ID25DCP_status: 8 VehicleBus
 SG_ CP_UHF_controlState : 38|4@1+ (1,0) [0|10] ""  Receiver
 SG_ CP_UHF_handleFound : 42|1@1+ (1,0) [0|1] ""  Receiver
 SG_ CP_apsVoltage : 24|8@1+ (0.0715686,0) [0|18.249] "V"  Receiver
 SG_ CP_chargeCablePresent : 3|1@1+ (1,0) [0|1] ""  Receiver
 SG_ CP_chargeCableSecured : 4|1@1+ (1,0) [0|1] ""  Receiver
 SG_ CP_chargeCableState : 14|2@1+ (1,0) [0|2] ""  Receiver
 SG_ CP_chargeDoorOpen : 10|1@1+ (1,0) [0|1] ""  Receiver
 SG_ CP_chargeDoorOpenUI : 51|1@1+ (1,0) [0|1] ""  Receiver
 SG_ CP_coldWeatherMode : 60|1@1+ (1,0) [0|1] ""  Receiver
 SG_ CP_coverClosed : 63|1@1+ (1,0) [0|1] ""  Receiver
 SG_ CP_doorButtonPressed : 32|1@1+ (1,0) [0|1] ""  Receiver
 SG_ CP_doorControlState : 11|3@1+ (1,0) [0|6] ""  Receiver
 SG_ CP_doorOpenRequested : 43|1@1+ (1,0) [0|1] ""  Receiver
 SG_ CP_faultLineSensed : 44|1@1+ (1,0) [0|1] ""  Receiver
 SG_ CP_hvInletExposed : 61|1@1+ (1,0) [0|1] ""  Receiver
 SG_ CP_inductiveDoorState : 45|3@1+ (1,0) [0|7] ""  Receiver
 SG_ CP_inductiveSensorState : 48|3@1+ (1,0) [0|7] ""  Receiver
 SG_ CP_insertEnableLine : 2|1@1+ (1,0) [0|1] ""  Receiver
 SG_ CP_latch2ControlState : 19|3@1+ (1,0) [0|5] ""  Receiver
 SG_ CP_latch2State : 8|2@1+ (1,0) [0|3] ""  Receiver
 SG_ CP_latchControlState : 16|3@1+ (1,0) [0|5] ""  Receiver
 SG_ CP_latchEngaged : 62|1@1+ (1,0) [0|1] ""  Receiver
 SG_ CP_latchState : 5|2@1+ (1,0) [0|3] ""  Receiver
 SG_ CP_ledColor : 33|4@1+ (1,0) [0|10] ""  Receiver
 SG_ CP_numAlertsSet : 53|7@1+ (1,0) [0|127] ""  Receiver
 SG_ CP_permanentPowerRequest : 7|1@1+ (1,0) [0|1] ""  Receiver
 SG_ CP_swcanRelayClosed : 37|1@1+ (1,0) [0|1] ""  Receiver
 SG_ CP_type : 0|2@1+ (1,0) [0|3] ""  Receiver
 SG_ CP_vehicleUnlockRequest : 52|1@1+ (1,0) [0|1] ""  Receiver

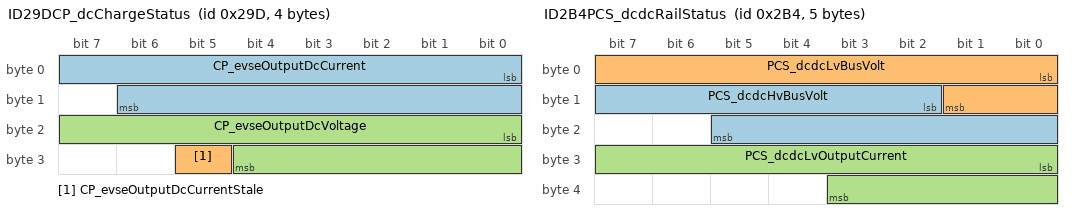
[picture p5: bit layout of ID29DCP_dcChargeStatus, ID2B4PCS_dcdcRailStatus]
BO_ 669 ID29DCP_dcChargeStatus: 4 VehicleBus
 SG_ CP_evseOutputDcCurrent : 0|15@1- (0.0732467,0) [-1200|1200] "A"  Receiver
 SG_ CP_evseOutputDcCurrentStale : 29|1@1+ (1,0) [0|1] ""  Receiver
 SG_ CP_evseOutputDcVoltage : 16|13@1+ (0.0732422,0) [0|599.927] "V"  Receiver

BO_ 692 ID2B4PCS_dcdcRailStatus: 5 VehicleBus
 SG_ PCS_dcdcHvBusVolt : 10|12@1+ (0.146484,0) [0|599.854] "V"  Receiver
 SG_ PCS_dcdcLvBusVolt : 0|10@1+ (0.0390625,0) [0|39.9609] "V"  Receiver
 SG_ PCS_dcdcLvOutputCurrent : 24|12@1+ (0.1,0) [0|400] "A"  Receiver

BO_ 777 ID309DAS_object: 8 VehicleBus
 SG_ DAS_objectId M : 0|3@1+ (1,0) [0|5] ""  Receiver
 SG_ DAS_cutinVehDx m3 : 8|8@1+ (0.5,0) [0|127] "m"  Receiver
 SG_ DAS_cutinVehDy m3 : 20|7@1+ (0.35,-22.05) [-22.05|22.4] "m"  Receiver
 SG_ DAS_cutinVehHeading m5 : 56|8@1+ (0.0245437,-3.14159) [-3.14159|3.09251] "rad"  Receiver
 SG_ DAS_cutinVehId m3 : 27|7@1+ (1,0) [0|127] ""  Receiver
 SG_ DAS_cutinVehRelevantForControl m3 : 7|1@1+ (1,0) [0|1] ""  Receiver
 SG_ DAS_cutinVehType m3 : 3|3@1+ (1,0) [0|5] ""  Receiver
 SG_ DAS_cutinVehVxRel m3 : 16|4@1+ (4,-30) [-30|26] "m/s"  Receiver
 SG_ DAS_leadVeh2Dx m0 : 39|8@1+ (0.5,0) [0|127] "m"  Receiver
 SG_ DAS_leadVeh2Dy m0 : 51|7@1+ (0.35,-22.05) [-22.05|22.4] "m"  Receiver
 SG_ DAS_leadVeh2Heading m5 : 16|8@1+ (0.0245437,-3.14159) [-3.14159|3.09251] "rad"  Receiver
 SG_ DAS_leadVeh2Id m0 : 58|6@1+ (1,0) [0|63] ""  Receiver
 SG_ DAS_leadVeh2RelevantForControl m0 : 38|1@1+ (1,0) [0|1] ""  Receiver
 SG_ DAS_leadVeh2Type m0 : 34|3@1+ (1,0) [0|5] ""  Receiver
 SG_ DAS_leadVeh2VxRel m0 : 47|4@1+ (4,-30) [-30|26] "m/s"  Receiver
 SG_ DAS_leadVehDx m0 : 8|8@1+ (0.5,0) [0|127] "m"  Receiver
 SG_ DAS_leadVehDy m0 : 20|7@1+ (0.35,-22.05) [-22.05|22.4] "m"  Receiver
 SG_ DAS_leadVehHeading m5 : 8|8@1+ (0.0245437,-3.14159) [-3.14159|3.09251] "rad"  Receiver
 SG_ DAS_leadVehId m0 : 27|7@1+ (1,0) [0|127] ""  Receiver
 SG_ DAS_leadVehRelevantForControl m0 : 7|1@1+ (1,0) [0|1] ""  Receiver
 SG_ DAS_leadVehType m0 : 3|3@1+ (1,0) [0|6] ""  Receiver
 SG_ DAS_leadVehVxRel m0 : 16|4@1+ (4,-30) [-30|26] "m/s"  Receiver
 SG_ DAS_leftVeh2Dx m1 : 39|8@1+ (0.5,0) [0|127] "m"  Receiver
 SG_ DAS_leftVeh2Dy m1 : 51|7@1+ (0.35,-22.05) [-22.05|22.4] "m"  Receiver
 SG_ DAS_leftVeh2Heading m5 : 32|8@1+ (0.0245437,-3.14159) [-3.14159|3.09251] "rad"  Receiver
 SG_ DAS_leftVeh2Id m1 : 58|6@1+ (1,0) [0|63] ""  Receiver
 SG_ DAS_leftVeh2RelevantForControl m1 : 38|1@1+ (1,0) [0|1] ""  Receiver
 SG_ DAS_leftVeh2Type m1 : 34|3@1+ (1,0) [0|5] ""  Receiver
 SG_ DAS_leftVeh2VxRel m1 : 47|4@1+ (4,-30) [-30|26] "m/s"  Receiver
 SG_ DAS_leftVehDx m1 : 8|8@1+ (0.5,0) [0|127] "m"  Receiver
 SG_ DAS_leftVehDy m1 : 20|7@1+ (0.35,-22.05) [-22.05|22.4] "m"  Receiver
 SG_ DAS_leftVehHeading m5 : 24|8@1+ (0.0245437,-3.14159) [-3.14159|3.09251] "rad"  Receiver
 SG_ DAS_leftVehId m1 : 27|7@1+ (1,0) [0|127] ""  Receiver
 SG_ DAS_leftVehRelevantForControl m1 : 7|1@1+ (1,0) [0|1] ""  Receiver
 SG_ DAS_leftVehType m1 : 3|3@1+ (1,0) [0|5] ""  Receiver
 SG_ DAS_leftVehVxRel m1 : 16|4@1+ (4,-30) [-30|26] "m/s"  Receiver
 SG_ DAS_rightVeh2Dx m2 : 39|8@1+ (0.5,0) [0|127] "m"  Receiver
 SG_ DAS_rightVeh2Dy m2 : 51|7@1+ (0.35,-22.05) [-22.05|22.4] "m"  Receiver
 SG_ DAS_rightVeh2Heading m5 : 48|8@1+ (0.0245437,-3.14159) [-3.14159|3.09251] "rad"  Receiver
 SG_ DAS_rightVeh2Id m2 : 58|6@1+ (1,0) [0|63] ""  Receiver
 SG_ DAS_rightVeh2RelevantForControl m2 : 38|1@1+ (1,0) [0|1] ""  Receiver
 SG_ DAS_rightVeh2Type m2 : 34|3@1+ (1,0) [0|5] ""  Receiver
 SG_ DAS_rightVeh2VxRel m2 : 47|4@1+ (4,-30) [-30|26] "m/s"  Receiver
 SG_ DAS_rightVehDx m2 : 8|8@1+ (0.5,0) [0|127] "m"  Receiver
 SG_ DAS_rightVehDy m2 : 20|7@1+ (0.35,-22.05) [-22.05|22.4] "m"  Receiver
 SG_ DAS_rightVehHeading m5 : 40|8@1+ (0.0245437,-3.14159) [-3.14159|3.09251] "rad"  Receiver
 SG_ DAS_rightVehId m2 : 27|7@1+ (1,0) [0|127] ""  Receiver
 SG_ DAS_rightVehRelevantForControl m2 : 7|1@1+ (1,0) [0|1] ""  Receiver
 SG_ DAS_rightVehType m2 : 3|3@1+ (1,0) [0|5] ""  Receiver
 SG_ DAS_rightVehVxRel m2 : 16|4@1+ (4,-30) [-30|26] "m/s"  Receiver
 SG_ DAS_roadSignArrow m4 : 27|3@1+ (1,0) [0|4] ""  Receiver
 SG_ DAS_roadSignColor m4 : 3|3@1+ (1,0) [0|4] ""  Receiver
 SG_ DAS_roadSignControlActive m4 : 24|1@1+ (1,0) [0|1] ""  Receiver
 SG_ DAS_roadSignId m4 : 6|8@1+ (1,0) [0|255] ""  Receiver
 SG_ DAS_roadSignOrientation m4 : 30|2@1+ (1,0) [0|2] ""  Receiver
 SG_ DAS_roadSignSource m4 : 25|2@1+ (1,0) [0|2] ""  Receiver
 SG_ DAS_roadSignStopLineDist m4 : 14|10@1+ (0.2,-20) [-20|184.4] "m"  Receiver

BO_ 929 ID3A1VCFRONT_vehicleStatus: 8 VehicleBus
 SG_ VCFRONT_12vStatusForDrive : 14|2@1+ (1,0) [0|2] ""  Receiver
 SG_ VCFRONT_2RowCenterUnbuckled : 38|2@1+ (1,0) [0|2] ""  Receiver
 SG_ VCFRONT_2RowLeftUnbuckled : 36|2@1+ (1,0) [0|2] ""  Receiver
 SG_ VCFRONT_2RowRightUnbuckled : 40|2@1+ (1,0) [0|2] ""  Receiver
 SG_ VCFRONT_APGlassHeaterState : 2|3@1+ (1,0) [0|4] ""  Receiver
 SG_ VCFRONT_accPlusAvailable : 9|1@1+ (1,0) [0|1] ""  Receiver
 SG_ VCFRONT_batterySupportRequest : 27|1@1+ (1,0) [0|1] ""  Receiver
 SG_ VCFRONT_bmsHvChargeEnable : 0|1@1+ (1,0) [0|1] ""  Receiver
 SG_ VCFRONT_diPowerOnState : 10|3@1+ (1,0) [0|4] ""  Receiver
 SG_ VCFRONT_driverBuckleStatus : 30|1@1+ (1,0) [0|1] ""  Receiver
 SG_ VCFRONT_driverDoorStatus : 31|1@1+ (1,0) [0|1] ""  Receiver
 SG_ VCFRONT_driverIsLeaving : 28|1@1+ (1,0) [0|1] ""  Receiver
 SG_ VCFRONT_driverIsLeavingAnySpeed : 13|1@1+ (1,0) [0|1] ""  Receiver
 SG_ VCFRONT_driverPresent : 7|1@1+ (1,0) [0|1] ""  Receiver
 SG_ VCFRONT_driverUnbuckled : 32|2@1+ (1,0) [0|2] ""  Receiver
 SG_ VCFRONT_ota12VSupportRequest : 29|1@1+ (1,0) [0|1] ""  Receiver
 SG_ VCFRONT_passengerPresent : 8|1@1+ (1,0) [0|1] ""  Receiver
 SG_ VCFRONT_passengerUnbuckled : 34|2@1+ (1,0) [0|2] ""  Receiver
 SG_ VCFRONT_pcs12vVoltageTarget : 16|11@1+ (0.01,0) [0|16] "V"  Receiver
 SG_ VCFRONT_pcsEFuseVoltage : 42|10@1+ (0.1,0) [0|102.2] "V"  Receiver
 SG_ VCFRONT_preconditionRequest : 1|1@1+ (1,0) [0|1] ""  Receiver
 SG_ VCFRONT_standbySupplySupported : 6|1@1+ (1,0) [0|1] ""  Receiver
 SG_ VCFRONT_thermalSystemType : 5|1@1+ (1,0) [0|1] ""  Receiver
 SG_ VCFRONT_vehicleStatusChecksum : 56|8@1+ (1,0) [0|255] ""  Receiver
 SG_ VCFRONT_vehicleStatusCounter : 52|4@1+ (1,0) [0|15] ""  Receiver

BO_ 994 ID3E2VCLEFT_lightStatus: 7 VehicleBus
 SG_ VCLEFT_FLMapLightStatus : 6|2@1+ (1,0) [0|3] ""  Receiver
 SG_ VCLEFT_FLMapLightSwitchPressed : 14|1@1+ (1,0) [0|1] ""  Receiver
 SG_ VCLEFT_FRMapLightStatus : 8|2@1+ (1,0) [0|3] ""  Receiver
 SG_ VCLEFT_FRMapLightSwitchPressed : 15|1@1+ (1,0) [0|1] ""  Receiver
 SG_ VCLEFT_RLMapLightStatus : 10|2@1+ (1,0) [0|3] ""  Receiver
 SG_ VCLEFT_RLMapLightSwitchPressed : 16|1@1+ (1,0) [0|1] ""  Receiver
 SG_ VCLEFT_RRMapLightStatus : 12|2@1+ (1,0) [0|3] ""  Receiver
 SG_ VCLEFT_RRMapLightSwitchPressed : 17|1@1+ (1,0) [0|1] ""  Receiver
 SG_ VCLEFT_brakeLightStatus : 0|2@1+ (1,0) [0|3] ""  Receiver
 SG_ VCLEFT_brakeTrailerLightStatus : 22|2@1+ (1,0) [0|3] ""  Receiver
 SG_ VCLEFT_dynamicBrakeLightStatus : 44|2@1+ (1,0) [0|2] ""  Receiver
 SG_ VCLEFT_fogTrailerLightStatus : 26|2@1+ (1,0) [0|3] ""  Receiver
 SG_ VCLEFT_frontRideHeight : 28|8@1- (1,0) [-127|127] "mm"  Receiver
 SG_ VCLEFT_leftTurnTrailerLightStatu : 18|2@1+ (1,0) [0|3] ""  Receiver
 SG_ VCLEFT_rearRideHeight : 36|8@1- (1,0) [-127|127] "mm"  Receiver
 SG_ VCLEFT_reverseTrailerLightStatus : 49|2@1+ (1,0) [0|3] ""  Receiver
 SG_ VCLEFT_rideHeightSensorFault : 48|1@1+ (1,0) [0|1] ""  Receiver
 SG_ VCLEFT_rightTrnTrailerLightStatu : 20|2@1+ (1,0) [0|3] ""  Receiver
 SG_ VCLEFT_tailLightOutageStatus : 51|1@1+ (1,0) [0|1] ""  Receiver
 SG_ VCLEFT_tailLightStatus : 2|2@1+ (1,0) [0|3] ""  Receiver
 SG_ VCLEFT_tailTrailerLightStatus : 24|2@1+ (1,0) [0|3] ""  Receiver
 SG_ VCLEFT_trailerDetected : 46|2@1+ (1,0) [0|3] ""  Receiver
 SG_ VCLEFT_turnSignalStatus : 4|2@1+ (1,0) [0|3] ""  Receiver

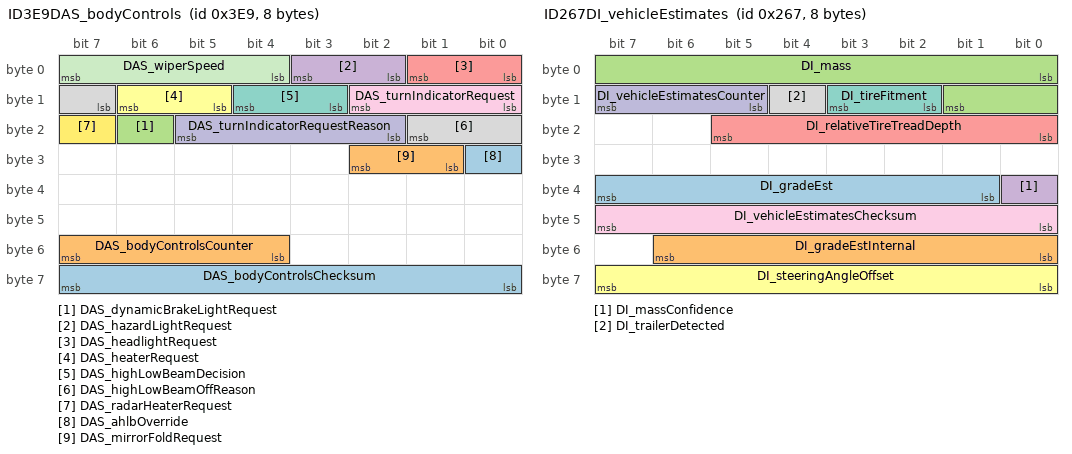
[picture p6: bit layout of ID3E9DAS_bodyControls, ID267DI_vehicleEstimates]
BO_ 1001 ID3E9DAS_bodyControls: 8 VehicleBus
 SG_ DAS_bodyControlsChecksum : 56|8@1+ (1,0) [0|255] ""  Receiver
 SG_ DAS_bodyControlsCounter : 52|4@1+ (1,0) [0|15] ""  Receiver
 SG_ DAS_dynamicBrakeLightRequest : 22|1@1+ (1,0) [0|1] ""  Receiver
 SG_ DAS_hazardLightRequest : 2|2@1+ (1,0) [0|3] ""  Receiver
 SG_ DAS_headlightRequest : 0|2@1+ (1,0) [0|3] ""  Receiver
 SG_ DAS_heaterRequest : 13|2@1+ (1,0) [0|2] ""  Receiver
 SG_ DAS_highLowBeamDecision : 11|2@1+ (1,0) [0|3] ""  Receiver
 SG_ DAS_highLowBeamOffReason : 15|3@1+ (1,0) [0|5] ""  Receiver
 SG_ DAS_turnIndicatorRequest : 8|3@1+ (1,0) [0|4] ""  Receiver
 SG_ DAS_turnIndicatorRequestReason : 18|4@1+ (1,0) [0|12] ""  Receiver
 SG_ DAS_wiperSpeed : 4|4@1+ (1,0) [0|15] ""  Receiver
 SG_ DAS_radarHeaterRequest : 23|1@1+ (1,0) [0|1] ""  Receiver
 SG_ DAS_ahlbOverride : 24|1@1+ (1,0) [0|1] ""  Receiver
 SG_ DAS_mirrorFoldRequest : 25|2@1+ (1,0) [0|0] ""  Receiver

BO_ 1013 ID3F5VCFRONT_lighting: 8 VehicleBus
 SG_ VCFRONT_DRLLeftStatus : 36|2@1+ (1,0) [0|3] ""  Receiver
 SG_ VCFRONT_DRLRightStatus : 38|2@1+ (1,0) [0|3] ""  Receiver
 SG_ VCFRONT_ambientLightingBrightnes : 8|8@1+ (0.5,0) [0|127] "%"  Receiver
 SG_ VCFRONT_approachLightingRequest : 25|1@1+ (1,0) [0|1] ""  Receiver
 SG_ VCFRONT_courtesyLightingRequest : 24|1@1+ (1,0) [0|1] ""  Receiver
 SG_ VCFRONT_fogLeftStatus : 40|2@1+ (1,0) [0|3] ""  Receiver
 SG_ VCFRONT_fogRightStatus : 42|2@1+ (1,0) [0|3] ""  Receiver
 SG_ VCFRONT_hazardLightRequest : 4|4@1+ (1,0) [0|8] ""  Receiver
 SG_ VCFRONT_hazardSwitchBacklight : 27|1@1+ (1,0) [0|1] ""  Receiver
 SG_ VCFRONT_highBeamLeftStatus : 32|2@1+ (1,0) [0|3] ""  Receiver
 SG_ VCFRONT_highBeamRightStatus : 34|2@1+ (1,0) [0|3] ""  Receiver
 SG_ VCFRONT_highBeamSwitchActive : 58|1@1+ (1,0) [0|1] ""  Receiver
 SG_ VCFRONT_indicatorLeftRequest : 0|2@1+ (1,0) [0|2] ""  Receiver
 SG_ VCFRONT_indicatorRightRequest : 2|2@1+ (1,0) [0|2] ""  Receiver
 SG_ VCFRONT_lowBeamLeftStatus : 28|2@1+ (1,0) [0|3] ""  Receiver
 SG_ VCFRONT_lowBeamRightStatus : 30|2@1+ (1,0) [0|3] ""  Receiver
 SG_ VCFRONT_lowBeamsCalibrated : 62|1@1+ (1,0) [0|1] ""  Receiver
 SG_ VCFRONT_lowBeamsOnForDRL : 61|1@1+ (1,0) [0|1] ""  Receiver
 SG_ VCFRONT_parkLeftStatus : 54|2@1+ (1,0) [0|3] ""  Receiver
 SG_ VCFRONT_parkRightStatus : 56|2@1+ (1,0) [0|3] ""  Receiver
 SG_ VCFRONT_seeYouHomeLightingReq : 26|1@1+ (1,0) [0|1] ""  Receiver
 SG_ VCFRONT_sideMarkersStatus : 44|2@1+ (1,0) [0|3] ""  Receiver
 SG_ VCFRONT_sideRepeaterLeftStatus : 46|2@1+ (1,0) [0|3] ""  Receiver
 SG_ VCFRONT_sideRepeaterRightStatus : 48|2@1+ (1,0) [0|3] ""  Receiver
 SG_ VCFRONT_simLatchingStalk : 59|2@1+ (1,0) [0|3] ""  Receiver
 SG_ VCFRONT_switchLightingBrightness : 16|8@1+ (0.5,0) [0|127] "%"  Receiver
 SG_ VCFRONT_turnSignalLeftStatus : 50|2@1+ (1,0) [0|3] ""  Receiver
 SG_ VCFRONT_turnSignalRightStatus : 52|2@1+ (1,0) [0|3] ""  Receiver

BO_ 615 ID267DI_vehicleEstimates: 8 VehicleBus
 SG_ DI_gradeEst : 33|7@1- (1,0) [-40|40] "%"  Receiver
 SG_ DI_gradeEstInternal : 48|7@1- (1,0) [-40|40] "%"  Receiver
 SG_ DI_mass : 0|10@1+ (5,1900) [1900|7010] "kg"  Receiver
 SG_ DI_massConfidence : 32|1@1+ (1,0) [0|1] ""  Receiver
 SG_ DI_relativeTireTreadDepth : 16|6@1- (0.2,0) [-6.2|6.2] "mm"  Receiver
 SG_ DI_steeringAngleOffset : 56|8@1- (0.2,0) [-25.6|25.4] "Deg"  Receiver
 SG_ DI_tireFitment : 10|2@1+ (1,0) [0|3] ""  Receiver
 SG_ DI_trailerDetected : 12|1@1+ (1,0) [0|1] ""  Receiver
 SG_ DI_vehicleEstimatesChecksum : 40|8@1+ (1,0) [0|255] ""  Receiver
 SG_ DI_vehicleEstimatesCounter : 13|3@1+ (1,0) [0|7] ""  Receiver

BO_ 642 ID282VCLEFT_hvacBlowerFeedback: 8 VehicleBus
 SG_ VCLEFT_blowerIndex M : 0|2@1+ (1,0) [0|1] ""  Receiver
 SG_ VCLEFT_hvacBlowerCBCCtrlState m1 : 58|3@1+ (1,0) [0|4] ""  Receiver
 SG_ VCLEFT_hvacBlowerCBCEstState m1 : 54|4@1+ (1,0) [0|14] ""  Receiver
 SG_ VCLEFT_hvacBlowerEnabled m0 : 2|1@1+ (1,0) [0|1] ""  Receiver
 SG_ VCLEFT_hvacBlowerFETTemp m0 : 44|7@1+ (1.5,-40) [-40|149] "C"  Receiver
 SG_ VCLEFT_hvacBlowerFault m0 : 59|1@1+ (1,0) [0|1] ""  Receiver
 SG_ VCLEFT_hvacBlowerIPhase0 m1 : 10|8@1+ (0.2,0) [0|50] "A"  Receiver
 SG_ VCLEFT_hvacBlowerIPhase1 m1 : 18|8@1+ (0.2,0) [0|50] "A"  Receiver
 SG_ VCLEFT_hvacBlowerIPhase2 m1 : 26|8@1+ (0.2,0) [0|50] "A"  Receiver
 SG_ VCLEFT_hvacBlowerITerm m0 : 51|7@1+ (0.05,-1.5) [-1.5|4.5] "Nm"  Receiver
 SG_ VCLEFT_hvacBlowerInitd m0 : 58|1@1+ (1,0) [0|1] ""  Receiver
 SG_ VCLEFT_hvacBlowerLimitFETTemps m0 : 60|1@1+ (1,0) [0|1] ""  Receiver
 SG_ VCLEFT_hvacBlowerOutputDuty m0 : 3|7@1+ (1,0) [0|100] "%"  Receiver
 SG_ VCLEFT_hvacBlowerPowerOn m0 : 61|1@1+ (1,0) [0|1] ""  Receiver
 SG_ VCLEFT_hvacBlowerRPMActual m0 : 20|10@1+ (10,0) [0|10000] "rpm"  Receiver
 SG_ VCLEFT_hvacBlowerRPMTarget m0 : 10|10@1+ (10,0) [0|10000] "rpm"  Receiver
 SG_ VCLEFT_hvacBlowerRs m1 : 2|8@1+ (0.25,0) [0|60] "mOhm"  Receiver
 SG_ VCLEFT_hvacBlowerRsOnlineActive m1 : 61|1@1+ (1,0) [0|1] ""  Receiver
 SG_ VCLEFT_hvacBlowerSpiError m0 : 62|1@1+ (1,0) [0|1] ""  Receiver
 SG_ VCLEFT_hvacBlowerTorque m0 : 34|10@1+ (0.006,-1.5) [-1.5|4.5] "Nm"  Receiver
 SG_ VCLEFT_hvacBlower_IO_CBC_HEAD m1 : 34|4@1+ (1,0) [0|15] ""  Receiver
 SG_ VCLEFT_hvacBlower_IO_CBC_Status m1 : 43|1@1+ (1,0) [0|1] ""  Receiver
 SG_ VCLEFT_hvacBlower_IO_CBC_TAIL m1 : 38|4@1+ (1,0) [0|15] ""  Receiver
 SG_ VCLEFT_hvacBlower_IO_CBC_TAIL_va m1 : 42|1@1+ (1,0) [0|1] ""  Receiver
 SG_ VCLEFT_hvacBlower_IO_CBC_numUart m1 : 46|8@1+ (1,0) [0|255] ""  Receiver

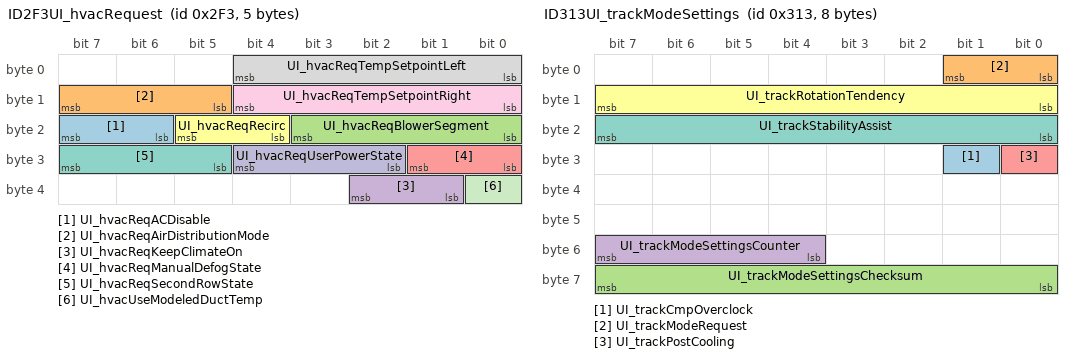
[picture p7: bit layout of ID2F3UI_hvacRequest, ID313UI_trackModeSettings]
BO_ 755 ID2F3UI_hvacRequest: 5 VehicleBus
 SG_ UI_hvacReqACDisable : 22|2@1+ (1,0) [0|2] ""  Receiver
 SG_ UI_hvacReqAirDistributionMode : 13|3@1+ (1,0) [0|7] ""  Receiver
 SG_ UI_hvacReqBlowerSegment : 16|4@1+ (1,0) [0|11] ""  Receiver
 SG_ UI_hvacReqKeepClimateOn : 33|2@1+ (1,0) [0|3] ""  Receiver
 SG_ UI_hvacReqManualDefogState : 24|2@1+ (1,0) [0|2] ""  Receiver
 SG_ UI_hvacReqRecirc : 20|2@1+ (1,0) [0|2] ""  Receiver
 SG_ UI_hvacReqSecondRowState : 29|3@1+ (1,0) [0|4] ""  Receiver
 SG_ UI_hvacReqTempSetpointLeft : 0|5@1+ (0.5,15) [15|28] "C"  Receiver
 SG_ UI_hvacReqTempSetpointRight : 8|5@1+ (0.5,15) [15|28] "C"  Receiver
 SG_ UI_hvacReqUserPowerState : 26|3@1+ (1,0) [0|4] ""  Receiver
 SG_ UI_hvacUseModeledDuctTemp : 32|1@1+ (1,0) [0|1] ""  Receiver

BO_ 787 ID313UI_trackModeSettings: 8 VehicleBus
 SG_ UI_trackCmpOverclock : 25|1@1+ (1,0) [0|1] ""  Receiver
 SG_ UI_trackModeRequest : 0|2@1+ (1,0) [0|2] ""  Receiver
 SG_ UI_trackModeSettingsChecksum : 56|8@1+ (1,0) [0|255] ""  Receiver
 SG_ UI_trackModeSettingsCounter : 52|4@1+ (1,0) [0|15] ""  Receiver
 SG_ UI_trackPostCooling : 24|1@1+ (1,0) [0|1] ""  Receiver
 SG_ UI_trackRotationTendency : 8|8@1+ (0.5,0) [0|100] "%"  Receiver
 SG_ UI_trackStabilityAssist : 16|8@1+ (0.5,0) [0|100] "%"  Receiver

BO_ 821 ID335RearDIinfo: 8 VehicleBus
 SG_ DIR_infoIndex M : 0|8@1+ (1,0) [0|255] ""  Receiver
 SG_ DIR_FPGA_version m16 : 48|8@1+ (1,0) [0|255] ""  Receiver
 SG_ DIR_appGitHash m17 : 8|56@1+ (1,0) [0|7.20576E+016] ""  Receiver
 SG_ DIR_applicationCrc m13 : 32|32@1+ (1,0) [0|4294970000] ""  Receiver
 SG_ DIR_assemblyId m11 : 24|8@1+ (1,0) [0|255] ""  Receiver
 SG_ DIR_bootGitHash m18 : 8|56@1+ (1,0) [0|7.20576E+016] ""  Receiver
 SG_ DIR_bootloaderCrc m20 : 32|32@1+ (1,0) [0|4294970000] ""  Receiver
 SG_ DIR_buildConfigurationId m10 : 16|16@1+ (1,0) [0|65535] ""  Receiver
 SG_ DIR_buildType m10 : 8|3@1+ (1,0) [0|4] ""  Receiver
 SG_ DIR_componentId m10 : 48|16@1+ (1,0) [0|65535] ""  Receiver
 SG_ DIR_hardwareId m10 : 32|8@1+ (1,0) [0|252] ""  Receiver
 SG_ DIR_infoBootLdUdsProtocolVersion m20 : 8|8@1+ (1,0) [0|255] ""  Receiver
 SG_ DIR_oilPumpAppCrc m16 : 16|32@1+ (1,0) [0|4294970000] ""  Receiver
 SG_ DIR_oilPumpBuildType m16 : 8|3@1+ (1,0) [0|4] ""  Receiver
 SG_ DIR_pcbaId m11 : 16|8@1+ (1,0) [0|255] ""  Receiver
 SG_ DIR_platformTyp m19 : 8|8@1+ (1,0) [0|255] ""  Receiver
 SG_ DIR_subUsageId m11 : 48|16@1+ (1,0) [0|65535] ""  Receiver
 SG_ DIR_subcomponentGitHash m31 : 8|56@1+ (1,0) [0|7.20576E+016] ""  Receiver
 SG_ DIR_usageId m11 : 32|16@1+ (1,0) [0|65535] ""  Receiver

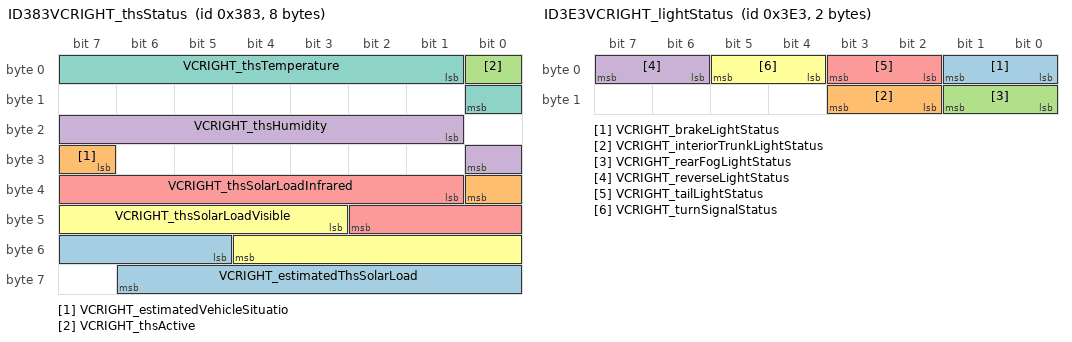
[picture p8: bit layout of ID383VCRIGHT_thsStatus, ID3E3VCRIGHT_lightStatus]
BO_ 899 ID383VCRIGHT_thsStatus: 8 VehicleBus
 SG_ VCRIGHT_estimatedThsSolarLoad : 53|10@1+ (1,0) [0|1022] "W/m2"  Receiver
 SG_ VCRIGHT_estimatedVehicleSituatio : 31|2@1+ (1,0) [0|2] ""  Receiver
 SG_ VCRIGHT_thsActive : 0|1@1+ (1,0) [0|1] ""  Receiver
 SG_ VCRIGHT_thsHumidity : 17|8@1+ (1,0) [0|100] "%"  Receiver
 SG_ VCRIGHT_thsSolarLoadInfrared : 33|10@1+ (1,0) [0|1022] "W/m2"  Receiver
 SG_ VCRIGHT_thsSolarLoadVisible : 43|10@1+ (1,0) [0|1022] "W/m2"  Receiver
 SG_ VCRIGHT_thsTemperature : 1|8@1- (1,-40) [-40|150] "C"  Receiver

BO_ 947 ID3B3UI_vehicleControl2: 4 VehicleBus
 SG_ UI_PINToDriveEnabled : 6|1@1+ (1,0) [0|1] ""  Receiver
 SG_ UI_PINToDrivePassed : 7|1@1+ (1,0) [0|1] ""  Receiver
 SG_ UI_UMCUpdateInhibit : 2|1@1+ (1,0) [0|1] ""  Receiver
 SG_ UI_VCLEFTFeature1 : 15|1@1+ (1,0) [0|1] ""  Receiver
 SG_ UI_VCSECFeature1 : 14|1@1+ (1,0) [0|1] ""  Receiver
 SG_ UI_WCUpdateInhibit : 3|1@1+ (1,0) [0|1] ""  Receiver
 SG_ UI_alarmTriggerRequest : 13|1@1+ (1,0) [0|1] ""  Receiver
 SG_ UI_autoRollWindowsOnLockEnable : 29|1@1+ (1,0) [0|1] ""  Receiver
 SG_ UI_autopilotPowerStateRequest : 25|2@1+ (1,0) [0|2] ""  Receiver
 SG_ UI_batteryPreconditioningRequest : 23|1@1+ (1,0) [0|1] ""  Receiver
 SG_ UI_coastDownMode : 24|1@1+ (1,0) [0|1] ""  Receiver
 SG_ UI_conditionalLoggingEnabledVCSE : 31|1@1+ (1,0) [0|1] ""  Receiver
 SG_ UI_efuseMXResistanceEstArmed : 30|1@1+ (1,0) [0|1] ""  Receiver
 SG_ UI_freeRollModeRequest : 19|1@1+ (1,0) [0|1] ""  Receiver
 SG_ UI_gloveboxRequest : 0|1@1+ (1,0) [0|1] ""  Receiver
 SG_ UI_lightSwitch : 9|3@1+ (1,0) [0|4] ""  Receiver
 SG_ UI_locksPanelActive : 5|1@1+ (1,0) [0|1] ""  Receiver
 SG_ UI_readyToAddKey : 12|1@1+ (1,0) [0|1] ""  Receiver
 SG_ UI_shorted12VCellTestMode : 27|2@1+ (1,0) [0|2] ""  Receiver
 SG_ UI_soundHornOnLock : 4|1@1+ (1,0) [0|1] ""  Receiver
 SG_ UI_summonState : 16|2@1+ (1,0) [0|3] ""  Receiver
 SG_ UI_trunkRequest : 1|1@1+ (1,0) [0|1] ""  Receiver
 SG_ UI_userPresent : 18|1@1+ (1,0) [0|1] ""  Receiver
 SG_ UI_windowRequest : 20|3@1+ (1,0) [0|4] ""  Receiver

BO_ 963 ID3C3VCRIGHT_switchStatus: 7 VehicleBus
 SG_ VCRIGHT_2RowSeatReclineSwitch : 54|1@1+ (1,0) [0|1] ""  Receiver
 SG_ VCRIGHT_btnWindowAutoDownRF : 27|1@1+ (1,0) [0|1] ""  Receiver
 SG_ VCRIGHT_btnWindowAutoDownRR : 31|1@1+ (1,0) [0|1] ""  Receiver
 SG_ VCRIGHT_btnWindowAutoUpRF : 25|1@1+ (1,0) [0|1] ""  Receiver
 SG_ VCRIGHT_btnWindowAutoUpRR : 29|1@1+ (1,0) [0|1] ""  Receiver
 SG_ VCRIGHT_btnWindowDownRF : 26|1@1+ (1,0) [0|1] ""  Receiver
 SG_ VCRIGHT_btnWindowDownRR : 30|1@1+ (1,0) [0|1] ""  Receiver
 SG_ VCRIGHT_btnWindowSwPackAutoDwnLF : 35|1@1+ (1,0) [0|1] ""  Receiver
 SG_ VCRIGHT_btnWindowSwPackAutoDwnLR : 39|1@1+ (1,0) [0|1] ""  Receiver
 SG_ VCRIGHT_btnWindowSwPackAutoDwnRR : 52|1@1+ (1,0) [0|1] ""  Receiver
 SG_ VCRIGHT_btnWindowSwPackAutoUpLF : 33|1@1+ (1,0) [0|1] ""  Receiver
 SG_ VCRIGHT_btnWindowSwPackAutoUpLR : 37|1@1+ (1,0) [0|1] ""  Receiver
 SG_ VCRIGHT_btnWindowSwPackAutoUpRR : 50|1@1+ (1,0) [0|1] ""  Receiver
 SG_ VCRIGHT_btnWindowSwPackDownLF : 34|1@1+ (1,0) [0|1] ""  Receiver
 SG_ VCRIGHT_btnWindowSwPackDownLR : 38|1@1+ (1,0) [0|1] ""  Receiver
 SG_ VCRIGHT_btnWindowSwPackDownRR : 51|1@1+ (1,0) [0|1] ""  Receiver
 SG_ VCRIGHT_btnWindowSwPackUpLF : 32|1@1+ (1,0) [0|1] ""  Receiver
 SG_ VCRIGHT_btnWindowSwPackUpLR : 36|1@1+ (1,0) [0|1] ""  Receiver
 SG_ VCRIGHT_btnWindowSwPackUpRR : 49|1@1+ (1,0) [0|1] ""  Receiver
 SG_ VCRIGHT_btnWindowUpRF : 24|1@1+ (1,0) [0|1] ""  Receiver
 SG_ VCRIGHT_btnWindowUpRR : 28|1@1+ (1,0) [0|1] ""  Receiver
 SG_ VCRIGHT_frontBuckleSwitch : 40|2@1+ (1,0) [0|3] ""  Receiver
 SG_ VCRIGHT_frontOccupancySwitch : 42|2@1+ (1,0) [0|3] ""  Receiver
 SG_ VCRIGHT_frontSeatBackrestBack : 12|2@1+ (1,0) [0|3] ""  Receiver
 SG_ VCRIGHT_frontSeatBackrestForward : 14|2@1+ (1,0) [0|3] ""  Receiver
 SG_ VCRIGHT_frontSeatLiftDown : 8|2@1+ (1,0) [0|3] ""  Receiver
 SG_ VCRIGHT_frontSeatLiftUp : 10|2@1+ (1,0) [0|3] ""  Receiver
 SG_ VCRIGHT_frontSeatLumbarDown : 16|2@1+ (1,0) [0|3] ""  Receiver
 SG_ VCRIGHT_frontSeatLumbarIn : 20|2@1+ (1,0) [0|3] ""  Receiver
 SG_ VCRIGHT_frontSeatLumbarOut : 22|2@1+ (1,0) [0|3] ""  Receiver
 SG_ VCRIGHT_frontSeatLumbarUp : 18|2@1+ (1,0) [0|3] ""  Receiver
 SG_ VCRIGHT_frontSeatTiltDown : 4|2@1+ (1,0) [0|3] ""  Receiver
 SG_ VCRIGHT_frontSeatTiltUp : 6|2@1+ (1,0) [0|3] ""  Receiver
 SG_ VCRIGHT_frontSeatTrackBack : 0|2@1+ (1,0) [0|3] ""  Receiver
 SG_ VCRIGHT_frontSeatTrackForward : 2|2@1+ (1,0) [0|3] ""  Receiver
 SG_ VCRIGHT_liftgateShutfaceSwitchPr : 53|1@1+ (1,0) [0|1] ""  Receiver
 SG_ VCRIGHT_rearCenterBuckleSwitch : 44|2@1+ (1,0) [0|3] ""  Receiver
 SG_ VCRIGHT_rearRightBuckleSwitch : 46|2@1+ (1,0) [0|3] ""  Receiver
 SG_ VCRIGHT_trunkExtReleasePressed : 48|1@1+ (1,0) [0|1] ""  Receiver

BO_ 995 ID3E3VCRIGHT_lightStatus: 2 VehicleBus
 SG_ VCRIGHT_brakeLightStatus : 0|2@1+ (1,0) [0|3] ""  Receiver
 SG_ VCRIGHT_interiorTrunkLightStatus : 10|2@1+ (1,0) [0|3] ""  Receiver
 SG_ VCRIGHT_rearFogLightStatus : 8|2@1+ (1,0) [0|3] ""  Receiver
 SG_ VCRIGHT_reverseLightStatus : 6|2@1+ (1,0) [0|3] ""  Receiver
 SG_ VCRIGHT_tailLightStatus : 2|2@1+ (1,0) [0|3] ""  Receiver
 SG_ VCRIGHT_turnSignalStatus : 4|2@1+ (1,0) [0|3] ""  Receiver

BO_ 1622 ID656FrontDIinfo: 8 VehicleBus
 SG_ DIF_infoIndex M : 0|8@1+ (1,0) [0|255] ""  Receiver
 SG_ DIF_FPGA_version m16 : 48|8@1+ (1,0) [0|255] ""  Receiver
 SG_ DIF_appGitHash m17 : 8|56@1+ (1,0) [0|7.20576E+016] ""  Receiver
 SG_ DIF_applicationCrc m13 : 32|32@1+ (1,0) [0|4294970000] ""  Receiver
 SG_ DIF_assemblyId m11 : 24|8@1+ (1,0) [0|255] ""  Receiver
 SG_ DIF_bootGitHash m18 : 8|56@1+ (1,0) [0|7.20576E+016] ""  Receiver
 SG_ DIF_bootloaderCrc m20 : 32|32@1+ (1,0) [0|4294970000] ""  Receiver
 SG_ DIF_buildConfigurationId m10 : 16|16@1+ (1,0) [0|65535] ""  Receiver
 SG_ DIF_buildType m10 : 8|3@1+ (1,0) [0|4] ""  Receiver
 SG_ DIF_componentId m10 : 48|16@1+ (1,0) [0|65535] ""  Receiver
 SG_ DIF_hardwareId m10 : 32|8@1+ (1,0) [0|252] ""  Receiver
 SG_ DIF_infoBootLdUdsProtocolVersion m20 : 8|8@1+ (1,0) [0|255] ""  Receiver
 SG_ DIF_oilPumpAppCrc m16 : 16|32@1+ (1,0) [0|4294970000] ""  Receiver
 SG_ DIF_oilPumpBuildType m16 : 8|3@1+ (1,0) [0|4] ""  Receiver
 SG_ DIF_pcbaId m11 : 16|8@1+ (1,0) [0|255] ""  Receiver
 SG_ DIF_platformTyp m19 : 8|8@1+ (1,0) [0|255] ""  Receiver
 SG_ DIF_subUsageId m11 : 48|16@1+ (1,0) [0|65535] ""  Receiver
 SG_ DIF_subcomponentGitHash m31 : 8|56@1+ (1,0) [0|7.20576E+016] ""  Receiver
 SG_ DIF_usageId m11 : 32|16@1+ (1,0) [0|65535] ""  Receiver

BO_ 768 ID300BMS_info: 8 VehicleBus
 SG_ BMS_infoIndex M : 0|8@1+ (1,0) [0|255] ""  Receiver
 SG_ BMS_appCrc m13 : 32|32@1+ (1,0) [0|4294970000] ""  Receiver
 SG_ BMS_appGitHash m17 : 8|56@1+ (1,0) [0|7.20576E+016] ""  Receiver
 SG_ BMS_assemblyId m11 : 24|8@1+ (1,0) [0|255] ""  Receiver
 SG_ BMS_bootCrc m20 : 32|32@1+ (1,0) [0|4294970000] ""  Receiver
 SG_ BMS_bootGitHash m18 : 8|56@1+ (1,0) [0|7.20576E+016] ""  Receiver
 SG_ BMS_bootUdsProtoVersion m20 : 8|8@1+ (1,0) [0|255] ""  Receiver
 SG_ BMS_buildConfigId m10 : 16|16@1+ (1,0) [0|65535] ""  Receiver
 SG_ BMS_buildType m10 : 8|3@1+ (1,0) [0|4] ""  Receiver
 SG_ BMS_componentId m10 : 48|16@1+ (1,0) [0|65535] ""  Receiver
 SG_ BMS_hardwareId m10 : 32|16@1+ (1,0) [0|65535] ""  Receiver
 SG_ BMS_pcbaId m11 : 16|8@1+ (1,0) [0|255] ""  Receiver
 SG_ BMS_platformType m13 : 8|8@1+ (1,0) [0|255] ""  Receiver
 SG_ BMS_subUsageId m11 : 48|16@1+ (1,0) [0|65535] ""  Receiver
 SG_ BMS_usageId m11 : 32|16@1+ (1,0) [0|65535] ""  Receiver

BO_ 530 ID212BMS_status: 8 VehicleBus
 SG_ BMS_activeHeatingWorthwhile : 5|1@1+ (1,0) [0|1] ""  Receiver
 SG_ BMS_chargeRequest : 29|1@1+ (1,0) [0|1] ""  Receiver
 SG_ BMS_chargeRetryCount : 51|3@1+ (1,0) [0|7] ""  Receiver
 SG_ BMS_chgPowerAvailable : 40|11@1+ (0.125,0) [0|255.75] "kW"  Receiver
 SG_ BMS_contactorState : 8|3@1+ (1,0) [0|6] ""  Receiver
 SG_ BMS_cpMiaOnHvs : 6|1@1+ (1,0) [0|1] ""  Receiver
 SG_ BMS_diLimpRequest : 36|1@1+ (1,0) [0|1] ""  Receiver
 SG_ BMS_ecuLogUploadRequest : 14|2@1+ (1,0) [0|3] ""  Receiver
 SG_ BMS_hvState : 16|3@1+ (1,0) [0|6] ""  Receiver
 SG_ BMS_hvacPowerRequest : 0|1@1+ (1,0) [0|1] ""  Receiver
 SG_ BMS_isolationResistance : 19|10@1+ (10,0) [0|10000] "kOhm"  Receiver
 SG_ BMS_keepWarmRequest : 30|1@1+ (1,0) [0|1] ""  Receiver
 SG_ BMS_notEnoughPowerForDrive : 1|1@1+ (1,0) [0|1] ""  Receiver
 SG_ BMS_notEnoughPowerForSupport : 2|1@1+ (1,0) [0|1] ""  Receiver
 SG_ BMS_okToShipByAir : 37|1@1+ (1,0) [0|1] ""  Receiver
 SG_ BMS_okToShipByLand : 38|1@1+ (1,0) [0|1] ""  Receiver
 SG_ BMS_pcsPwmEnabled : 7|1@1+ (1,0) [0|1] ""  Receiver
 SG_ BMS_preconditionAllowed : 3|1@1+ (1,0) [0|1] ""  Receiver
 SG_ BMS_smStateRequest : 56|4@1+ (1,0) [0|9] ""  Receiver
 SG_ BMS_state : 32|4@1+ (1,0) [0|10] ""  Receiver
 SG_ BMS_uiChargeStatus : 11|3@1+ (1,0) [0|5] ""  Receiver
 SG_ BMS_updateAllowed : 4|1@1+ (1,0) [0|1] ""  Receiver

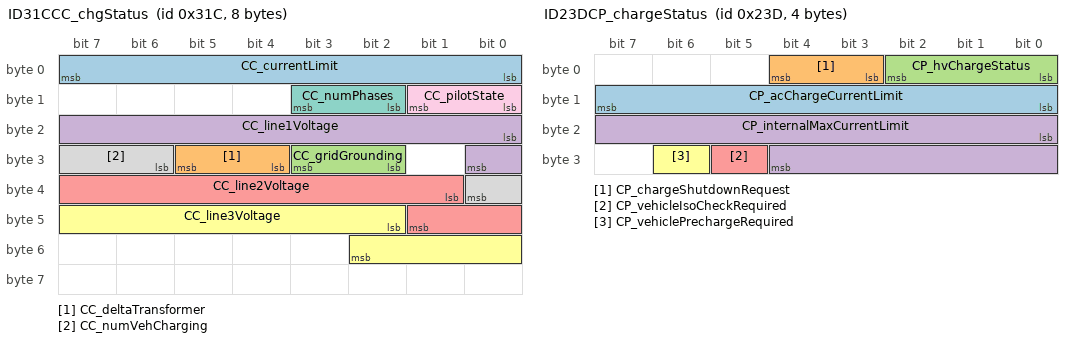
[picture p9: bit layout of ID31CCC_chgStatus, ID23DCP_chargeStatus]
BO_ 796 ID31CCC_chgStatus: 8 VehicleBus
 SG_ CC_currentLimit : 0|8@1+ (0.5,0) [0|127.5] "A"  Receiver
 SG_ CC_deltaTransformer : 28|2@1+ (1,0) [0|3] ""  Receiver
 SG_ CC_gridGrounding : 26|2@1+ (1,0) [0|2] ""  Receiver
 SG_ CC_line1Voltage : 16|9@1+ (1,0) [0|511] "V"  Receiver
 SG_ CC_line2Voltage : 33|9@1+ (1,0) [0|511] "V"  Receiver
 SG_ CC_line3Voltage : 42|9@1+ (1,0) [0|511] "V"  Receiver
 SG_ CC_numPhases : 10|2@1+ (1,0) [0|3] ""  Receiver
 SG_ CC_numVehCharging : 30|3@1+ (1,0) [0|7] ""  Receiver
 SG_ CC_pilotState : 8|2@1+ (1,0) [0|3] ""  Receiver

BO_ 573 ID23DCP_chargeStatus: 4 VehicleBus
 SG_ CP_acChargeCurrentLimit : 8|8@1+ (0.5,0) [0|127.5] "A"  Receiver
 SG_ CP_chargeShutdownRequest : 3|2@1+ (1,0) [0|2] ""  Receiver
 SG_ CP_hvChargeStatus : 0|3@1+ (1,0) [0|6] ""  Receiver
 SG_ CP_internalMaxCurrentLimit : 16|13@1+ (0.146502,0) [0|1200] "A"  Receiver
 SG_ CP_vehicleIsoCheckRequired : 29|1@1+ (1,0) [0|1] ""  Receiver
 SG_ CP_vehiclePrechargeRequired : 30|1@1+ (1,0) [0|1] ""  Receiver

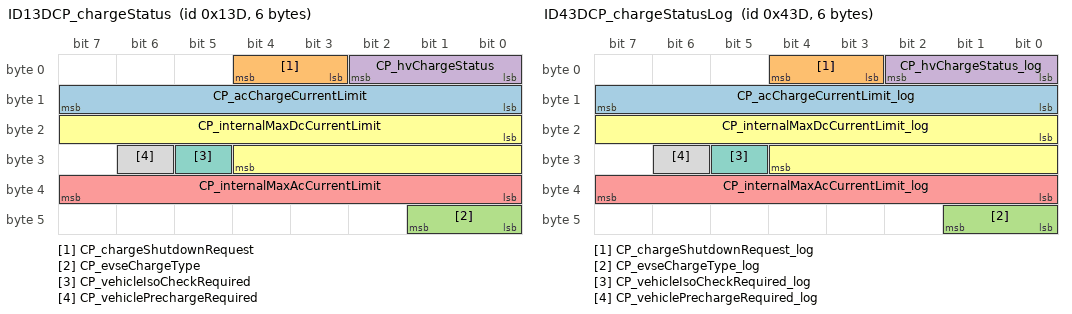
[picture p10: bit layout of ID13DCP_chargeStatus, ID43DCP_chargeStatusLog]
BO_ 317 ID13DCP_chargeStatus: 6 VehicleBus
 SG_ CP_acChargeCurrentLimit : 8|8@1+ (0.5,0) [0|127.5] "A"  Receiver
 SG_ CP_chargeShutdownRequest : 3|2@1+ (1,0) [0|2] ""  Receiver
 SG_ CP_evseChargeType : 40|2@1+ (1,0) [0|2] ""  Receiver
 SG_ CP_hvChargeStatus : 0|3@1+ (1,0) [0|6] ""  Receiver
 SG_ CP_internalMaxAcCurrentLimit : 32|8@1+ (0.5,0) [0|127.5] "A"  Receiver
 SG_ CP_internalMaxDcCurrentLimit : 16|13@1+ (0.146502,0) [0|1200] "A"  Receiver
 SG_ CP_vehicleIsoCheckRequired : 29|1@1+ (1,0) [0|1] ""  Receiver
 SG_ CP_vehiclePrechargeRequired : 30|1@1+ (1,0) [0|1] ""  Receiver

BO_ 1085 ID43DCP_chargeStatusLog: 6 VehicleBus
 SG_ CP_acChargeCurrentLimit_log : 8|8@1+ (0.5,0) [0|127.5] "A"  Receiver
 SG_ CP_chargeShutdownRequest_log : 3|2@1+ (1,0) [0|2] ""  Receiver
 SG_ CP_evseChargeType_log : 40|2@1+ (1,0) [0|2] ""  Receiver
 SG_ CP_hvChargeStatus_log : 0|3@1+ (1,0) [0|6] ""  Receiver
 SG_ CP_internalMaxAcCurrentLimit_log : 32|8@1+ (0.5,0) [0|127.5] "A"  Receiver
 SG_ CP_internalMaxDcCurrentLimit_log : 16|13@1+ (0.146502,0) [0|1200] "A"  Receiver
 SG_ CP_vehicleIsoCheckRequired_log : 29|1@1+ (1,0) [0|1] ""  Receiver
 SG_ CP_vehiclePrechargeRequired_log : 30|1@1+ (1,0) [0|1] ""  Receiver

BO_ 541 ID21DCP_evseStatus: 8 VehicleBus
 SG_ CP_acChargeState : 53|3@1+ (1,0) [0|6] ""  Receiver
 SG_ CP_acNumRetries : 40|2@1+ (1,0) [0|3] ""  Receiver
 SG_ CP_cableCurrentLimit : 24|7@1+ (1,0) [0|127] "A"  Receiver
 SG_ CP_cableType : 16|3@1+ (1,0) [0|4] ""  Receiver
 SG_ CP_digitalCommsAttempts : 32|2@1+ (1,0) [0|3] ""  Receiver
 SG_ CP_digitalCommsEstablished : 37|1@1+ (1,0) [0|1] ""  Receiver
 SG_ CP_evseAccept : 0|1@1+ (1,0) [0|1] ""  Receiver
 SG_ CP_evseChargeType_UI : 38|2@1+ (1,0) [0|2] ""  Receiver
 SG_ CP_evseRequest : 1|1@1+ (1,0) [0|1] ""  Receiver
 SG_ CP_gbState : 42|4@1+ (1,0) [0|15] ""  Receiver
 SG_ CP_gbdcChargeAttempts : 51|2@1+ (1,0) [0|3] ""  Receiver
 SG_ CP_gbdcFailureReason : 49|2@1+ (1,0) [0|3] ""  Receiver
 SG_ CP_gbdcStopChargeReason : 46|3@1+ (1,0) [0|7] ""  Receiver
 SG_ CP_iecComboState : 60|4@1+ (1,0) [0|12] ""  Receiver
 SG_ CP_pilot : 4|3@1+ (1,0) [0|7] ""  Receiver
 SG_ CP_pilotCurrent : 8|8@1+ (0.5,0) [0|127.5] "A"  Receiver
 SG_ CP_proximity : 2|2@1+ (1,0) [0|3] ""  Receiver
 SG_ CP_teslaDcState : 56|4@1+ (1,0) [0|10] ""  Receiver
 SG_ CP_teslaSwcanState : 34|3@1+ (1,0) [0|6] ""  Receiver

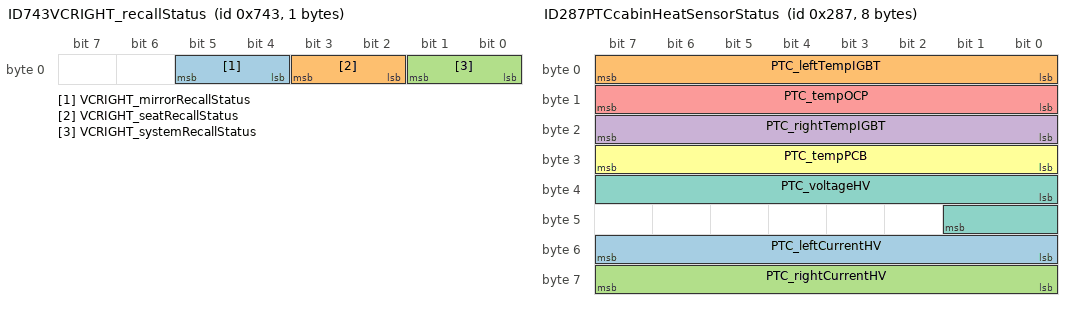
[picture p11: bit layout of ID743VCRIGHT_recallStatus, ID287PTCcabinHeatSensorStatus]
BO_ 1859 ID743VCRIGHT_recallStatus: 1 VehicleBus
 SG_ VCRIGHT_mirrorRecallStatus : 4|2@1+ (1,0) [0|3] ""  Receiver
 SG_ VCRIGHT_seatRecallStatus : 2|2@1+ (1,0) [0|3] ""  Receiver
 SG_ VCRIGHT_systemRecallStatus : 0|2@1+ (1,0) [0|3] ""  Receiver

BO_ 1885 ID75DCP_sensorData: 8 VehicleBus
 SG_ CP_sensorDataSelect M : 0|4@1+ (1,0) [0|12] ""  Receiver
 SG_ CP_UHF_chipState m6 : 4|3@1+ (1,0) [0|7] ""  Receiver
 SG_ CP_UHF_fifoData m6 : 32|8@1+ (1,0) [0|255] ""  Receiver
 SG_ CP_UHF_rssi m6 : 8|8@1+ (1,0) [0|255] ""  Receiver
 SG_ CP_UHF_rxNumBytes m6 : 24|8@1+ (1,0) [0|255] ""  Receiver
 SG_ CP_UHF_rxOverflow m6 : 16|1@1+ (1,0) [0|1] ""  Receiver
 SG_ CP_UHF_selfTestRssi m6 : 40|8@1+ (1,0) [0|255] ""  Receiver
 SG_ CP_backCover2Counts m5 : 32|16@1+ (0.0015259,0) [0|100] "%"  Receiver
 SG_ CP_backCoverCounts m5 : 16|16@1+ (0.0015259,0) [0|100] "%"  Receiver
 SG_ CP_boardTemperature m1 : 32|8@1+ (1.29412,-50) [-50|280] "C"  Receiver
 SG_ CP_doorCountsDebounced m0 : 24|16@1+ (0.0015259,0) [0|100] "%"  Receiver
 SG_ CP_doorCountsFiltered m0 : 8|16@1+ (0.0015259,0) [0|100] "%"  Receiver
 SG_ CP_doorI m2 : 16|12@1+ (0.0025,0) [0|10.2375] "A"  Receiver
 SG_ CP_doorLastRequestMaxI m2 : 28|12@1+ (0.0025,0) [0|10.2375] "A"  Receiver
 SG_ CP_doorPot m2 : 4|12@1+ (0.025,0) [0|100] "%"  Receiver
 SG_ CP_faultLineV m5 : 4|12@1+ (0.00114,0) [0|4.65524] "V"  Receiver
 SG_ CP_inductiveSensor_raw m4 : 4|28@1+ (1,0) [0|268435000] ""  Receiver
 SG_ CP_inlet1HarnessIdState m12 : 4|2@1+ (1,0) [0|2] ""  Receiver
 SG_ CP_inlet1HarnessIdValue m12 : 8|3@1+ (1,0) [0|7] ""  Receiver
 SG_ CP_inlet1HarnessV m12 : 16|14@1+ (0.001,0) [0|13.3] "V"  Receiver
 SG_ CP_inlet2HarnessIdState m12 : 30|2@1+ (1,0) [0|2] ""  Receiver
 SG_ CP_inlet2HarnessIdValue m12 : 32|3@1+ (1,0) [0|7] ""  Receiver
 SG_ CP_inlet2HarnessV m12 : 40|14@1+ (0.001,0) [0|13.3] "V"  Receiver
 SG_ CP_latch2I m3 : 16|12@1+ (0.0025,0) [0|10.2375] "A"  Receiver
 SG_ CP_latchI m3 : 4|12@1+ (0.0025,0) [0|10.2375] "A"  Receiver
 SG_ CP_pilotHighValue m9 : 40|12@1- (0.01,0) [-20.48|20.47] "V"  Receiver
 SG_ CP_pilotHighValue_intervalMax10s m10 : 28|12@1- (0.01,0) [-20.48|20.47] "V"  Receiver
 SG_ CP_pilotHighValue_intervalMin10s m10 : 40|12@1- (0.01,0) [-20.48|20.47] "V"  Receiver
 SG_ CP_pilotLowValue m9 : 28|12@1- (0.01,0) [-20.48|20.47] "V"  Receiver
 SG_ CP_pilotLowValue_intervalMax10s m10 : 4|12@1- (0.01,0) [-20.48|20.47] "V"  Receiver
 SG_ CP_pilotLowValue_intervalMin10s m10 : 16|12@1- (0.01,0) [-20.48|20.47] "V"  Receiver
 SG_ CP_pilotPeriod m9 : 16|12@1+ (1,0) [0|4095] ""  Receiver
 SG_ CP_pilotPulseWidth m9 : 4|12@1+ (1,0) [0|4095] ""  Receiver
 SG_ CP_pinTemperature1 m1 : 8|8@1+ (0.803922,-55) [-55|149.99] "C"  Receiver
 SG_ CP_pinTemperature2 m1 : 16|8@1+ (0.803922,-55) [-55|149.99] "C"  Receiver
 SG_ CP_pinTemperature3 m1 : 24|8@1+ (0.803922,-55) [-55|149.99] "C"  Receiver
 SG_ CP_proxConn1Sense m8 : 56|1@1+ (1,0) [0|1] ""  Receiver
 SG_ CP_proxEn m8 : 57|1@1+ (1,0) [0|1] ""  Receiver
 SG_ CP_proximityV m8 : 8|16@1+ (0.0001,0) [0|6.5535] "V"  Receiver
 SG_ CP_proximityV_GBCC1 m11 : 8|14@1+ (0.001,0) [0|13.3] "V"  Receiver
 SG_ CP_proximityV_GBCC2 m11 : 24|14@1+ (0.001,0) [0|13.3] "V"  Receiver
 SG_ CP_proximityV_intervalMax10s m8 : 40|16@1+ (0.0001,0) [0|6.5535] "V"  Receiver
 SG_ CP_proximityV_intervalMin10s m8 : 24|16@1+ (0.0001,0) [0|6.5535] "V"  Receiver
 SG_ CP_refVoltage m7 : 8|8@1+ (0.00705882,0) [0|1.8] "V"  Receiver

BO_ 647 ID287PTCcabinHeatSensorStatus: 8 VehicleBus
 SG_ PTC_leftCurrentHV : 48|8@1+ (0.2,0) [0|50] "A"  Receiver
 SG_ PTC_leftTempIGBT : 0|8@1+ (1,-40) [-40|200] "C"  Receiver
 SG_ PTC_rightCurrentHV : 56|8@1+ (0.2,0) [0|50] "A"  Receiver
 SG_ PTC_rightTempIGBT : 16|8@1+ (1,-40) [-40|200] "C"  Receiver
 SG_ PTC_tempOCP : 8|8@1+ (1,-40) [-40|200] "C"  Receiver
 SG_ PTC_tempPCB : 24|8@1+ (1,-40) [-40|200] "C"  Receiver
 SG_ PTC_voltageHV : 32|10@1+ (0.5,0) [0|511.5] "V"  Receiver

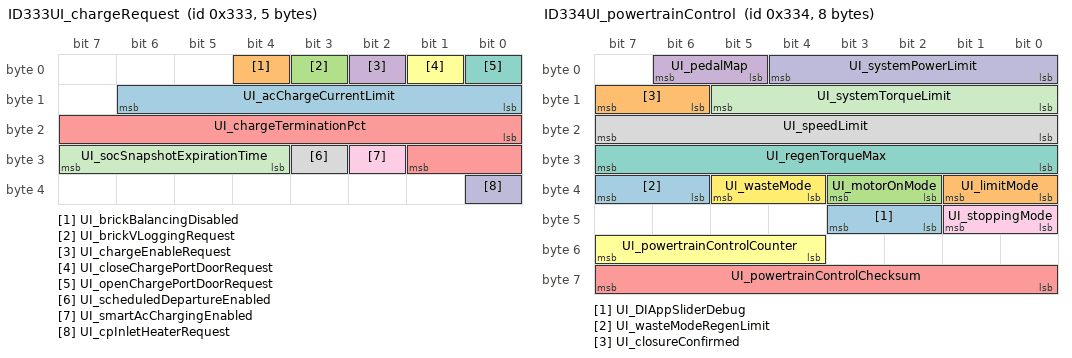
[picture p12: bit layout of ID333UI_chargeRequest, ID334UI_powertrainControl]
BO_ 819 ID333UI_chargeRequest: 5 VehicleBus
 SG_ UI_acChargeCurrentLimit : 8|7@1+ (1,0) [0|127] "A"  Receiver
 SG_ UI_brickBalancingDisabled : 4|1@1+ (1,0) [0|1] ""  Receiver
 SG_ UI_brickVLoggingRequest : 3|1@1+ (1,0) [0|1] ""  Receiver
 SG_ UI_chargeEnableRequest : 2|1@1+ (1,0) [0|1] ""  Receiver
 SG_ UI_chargeTerminationPct : 16|10@1+ (0.1,0) [25|100] "%"  Receiver
 SG_ UI_closeChargePortDoorRequest : 1|1@1+ (1,0) [0|1] ""  Receiver
 SG_ UI_openChargePortDoorRequest : 0|1@1+ (1,0) [0|1] ""  Receiver
 SG_ UI_scheduledDepartureEnabled : 27|1@1+ (1,0) [0|1] ""  Receiver
 SG_ UI_smartAcChargingEnabled : 26|1@1+ (1,0) [0|1] ""  Receiver
 SG_ UI_cpInletHeaterRequest : 32|1@1+ (1,0) [0|0] ""  Receiver
 SG_ UI_socSnapshotExpirationTime : 28|4@1+ (1,2) [0|0] "weeks"  Receiver

BO_ 820 ID334UI_powertrainControl: 8 VehicleBus
 SG_ UI_DIAppSliderDebug : 42|2@1+ (1,0) [0|3] ""  Receiver
 SG_ UI_limitMode : 32|2@1+ (1,0) [0|3] ""  Receiver
 SG_ UI_motorOnMode : 34|2@1+ (1,0) [0|2] ""  Receiver
 SG_ UI_pedalMap : 5|2@1+ (1,0) [0|2] ""  Receiver
 SG_ UI_powertrainControlChecksum : 56|8@1+ (1,0) [0|255] ""  Receiver
 SG_ UI_powertrainControlCounter : 52|4@1+ (1,0) [0|15] ""  Receiver
 SG_ UI_regenTorqueMax : 24|8@1+ (0.5,0) [0|100] "%"  Receiver
 SG_ UI_speedLimit : 16|8@1+ (1,50) [50|285] "kph"  Receiver
 SG_ UI_stoppingMode : 40|2@1+ (1,0) [0|2] ""  Receiver
 SG_ UI_systemPowerLimit : 0|5@1+ (20,20) [20|640] "kW"  Receiver
 SG_ UI_systemTorqueLimit : 8|6@1+ (100,4000) [4000|10300] "Nm"  Receiver
 SG_ UI_wasteMode : 36|2@1+ (1,0) [0|2] ""  Receiver
 SG_ UI_wasteModeRegenLimit : 38|2@1+ (1,0) [0|3] ""  Receiver
 SG_ UI_closureConfirmed : 14|2@1+ (1,0) [0|2] ""  Receiver

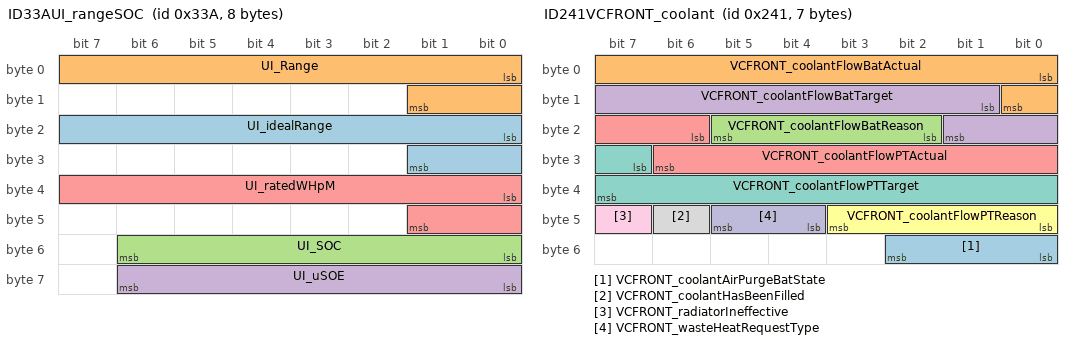
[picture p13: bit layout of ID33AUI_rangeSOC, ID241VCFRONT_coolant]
BO_ 826 ID33AUI_rangeSOC: 8 VehicleBus
 SG_ UI_idealRange : 16|10@1+ (1,0) [0|1023] "mi"  Receiver
 SG_ UI_Range : 0|10@1+ (1,0) [0|1023] "mi"  Receiver
 SG_ UI_SOC : 48|7@1+ (1,0) [0|127] "%"  Receiver
 SG_ UI_uSOE : 56|7@1+ (1,0) [0|127] "%"  Receiver
 SG_ UI_ratedWHpM : 32|10@1+ (1,0) [0|1023] "WHpM"  Receiver

BO_ 577 ID241VCFRONT_coolant: 7 VehicleBus
 SG_ VCFRONT_coolantAirPurgeBatState : 48|3@1+ (1,0) [0|4] ""  Receiver
 SG_ VCFRONT_coolantFlowBatActual : 0|9@1+ (0.1,0) [0|40] "LPM"  Receiver
 SG_ VCFRONT_coolantFlowBatReason : 18|4@1+ (1,0) [0|14] ""  Receiver
 SG_ VCFRONT_coolantFlowBatTarget : 9|9@1+ (0.1,0) [0|40] "LPM"  Receiver
 SG_ VCFRONT_coolantFlowPTActual : 22|9@1+ (0.1,0) [0|40] "LPM"  Receiver
 SG_ VCFRONT_coolantFlowPTReason : 40|4@1+ (1,0) [0|14] ""  Receiver
 SG_ VCFRONT_coolantFlowPTTarget : 31|9@1+ (0.1,0) [0|40] "LPM"  Receiver
 SG_ VCFRONT_coolantHasBeenFilled : 46|1@1+ (1,0) [0|1] ""  Receiver
 SG_ VCFRONT_radiatorIneffective : 47|1@1+ (1,0) [0|1] ""  Receiver
 SG_ VCFRONT_wasteHeatRequestType : 44|2@1+ (1,0) [0|2] ""  Receiver

BO_ 955 ID3BBUI_power: 2 VehicleBus
 SG_ UI_powerExpected : 0|8@1+ (1,0) [0|100] "kW"  Receiver
 SG_ UI_powerIdeal : 8|8@1+ (1,0) [0|100] "kW"  Receiver

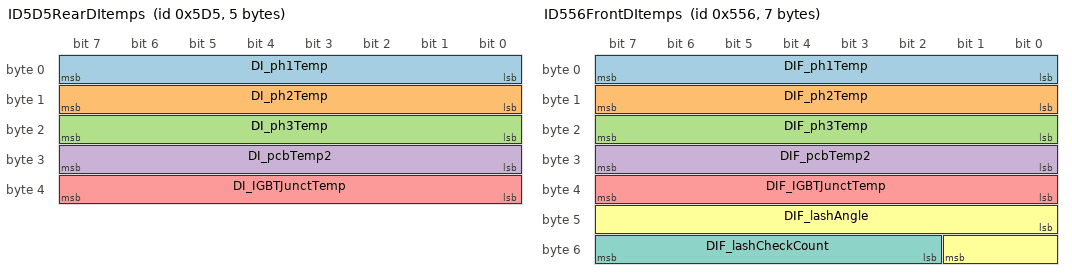
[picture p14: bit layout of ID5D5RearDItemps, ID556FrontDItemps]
BO_ 1493 ID5D5RearDItemps: 5 VehicleBus
 SG_ DI_ph1Temp : 0|8@1+ (1,-40) [-40|120] "C"  Receiver
 SG_ DI_ph2Temp : 8|8@1+ (1,-40) [-40|120] "C"  Receiver
 SG_ DI_ph3Temp : 16|8@1+ (1,-40) [-40|120] "C"  Receiver
 SG_ DI_pcbTemp2 : 24|8@1+ (1,-40) [-40|150] "C"  Receiver
 SG_ DI_IGBTJunctTemp : 32|8@1+ (1,-40) [-40|200] "C"  Receiver

BO_ 1366 ID556FrontDItemps: 7 VehicleBus
 SG_ DIF_ph1Temp : 0|8@1+ (1,-40) [-40|120] "C"  Receiver
 SG_ DIF_ph2Temp : 8|8@1+ (1,-40) [-40|120] "C"  Receiver
 SG_ DIF_ph3Temp : 16|8@1+ (1,-40) [-40|120] "C"  Receiver
 SG_ DIF_pcbTemp2 : 24|8@1+ (1,-40) [-40|150] "C"  Receiver
 SG_ DIF_IGBTJunctTemp : 32|8@1+ (1,-40) [-40|200] "C"  Receiver
 SG_ DIF_lashAngle : 40|10@1+ (0.06,0) [0|60] "Deg"  Receiver
 SG_ DIF_lashCheckCount : 50|6@1+ (1,0) [0|63] ""  Receiver

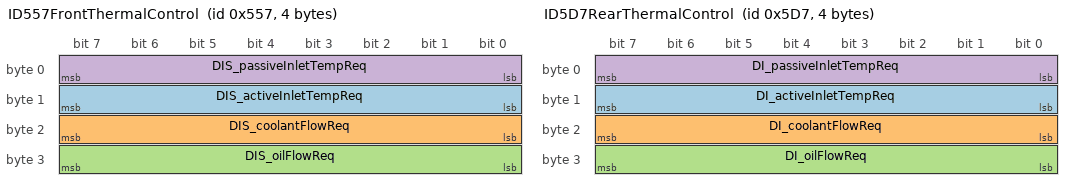
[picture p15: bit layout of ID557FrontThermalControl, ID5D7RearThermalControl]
BO_ 1367 ID557FrontThermalControl: 4 VehicleBus
 SG_ DIS_activeInletTempReq : 8|8@1+ (1,-40) [-40|120] "C"  Receiver
 SG_ DIS_coolantFlowReq : 16|8@1+ (0.2,0) [0|50] "LPM"  Receiver
 SG_ DIS_oilFlowReq : 24|8@1+ (0.06,0) [0|15] "LPM"  Receiver
 SG_ DIS_passiveInletTempReq : 0|8@1+ (1,-40) [-40|120] "C"  Receiver

BO_ 1495 ID5D7RearThermalControl: 4 VehicleBus
 SG_ DI_activeInletTempReq : 8|8@1+ (1,-40) [-40|120] "C"  Receiver
 SG_ DI_coolantFlowReq : 16|8@1+ (0.2,0) [0|50] "LPM"  Receiver
 SG_ DI_oilFlowReq : 24|8@1+ (0.06,0) [0|15] "LPM"  Receiver
 SG_ DI_passiveInletTempReq : 0|8@1+ (1,-40) [-40|120] "C"  Receiver

BO_ 2005 ID7D5DIR_debug: 8 VehicleBus
 SG_ DIR_debugSelector M : 0|8@1+ (1,0) [0|255] ""  Receiver
 SG_ DIR_brakeSwitchNC m42 : 63|1@1+ (1,0) [0|1] ""  Receiver
 SG_ DIR_brakeSwitchNO m42 : 62|1@1+ (1,0) [0|1] ""  Receiver
 SG_ DIR_busbarTemp m64 : 16|8@1+ (1,-40) [-40|215] "C"  Receiver
 SG_ DIR_controlStack m67 : 40|8@1+ (0.4,0) [0|100] "%"  Receiver
 SG_ DIR_cpu100HzAvg m66 : 32|8@1+ (0.4,0) [0|102] "%"  Receiver
 SG_ DIR_cpu100HzMin m66 : 24|8@1+ (0.4,0) [0|102] "%"  Receiver
 SG_ DIR_cpu10HzAvg m66 : 16|8@1+ (0.4,0) [0|102] "%"  Receiver
 SG_ DIR_cpu10HzMin m66 : 8|8@1+ (0.4,0) [0|102] "%"  Receiver
 SG_ DIR_cpu10msMin m66 : 40|8@1+ (0.4,0) [0|102] "%"  Receiver
 SG_ DIR_cpu1HzAvg m128 : 24|8@1+ (0.4,0) [0|102] "%"  Receiver
 SG_ DIR_cpu1HzMin m128 : 16|8@1+ (0.4,0) [0|102] "%"  Receiver
 SG_ DIR_cpu1kHzAvg m67 : 16|8@1+ (0.4,0) [0|102] "%"  Receiver
 SG_ DIR_cpu1kHzMin m67 : 8|8@1+ (0.4,0) [0|102] "%"  Receiver
 SG_ DIR_cpu20kHzAvg m67 : 32|8@1+ (0.4,0) [0|102] "%"  Receiver
 SG_ DIR_cpu20kHzMin m67 : 24|8@1+ (0.4,0) [0|102] "%"  Receiver
 SG_ DIR_cpuIDWord0 m131 : 16|16@1+ (1,0) [0|65535] ""  Receiver
 SG_ DIR_cpuIDWord1 m132 : 16|16@1+ (1,0) [0|65535] ""  Receiver
 SG_ DIR_cpuIDWord2 m132 : 32|16@1+ (1,0) [0|65535] ""  Receiver
 SG_ DIR_cpuIDWord3 m132 : 48|16@1+ (1,0) [0|65535] ""  Receiver
 SG_ DIR_crc m131 : 32|32@1+ (1,0) [0|4294970000] ""  Receiver
 SG_ DIR_currentLimit m41 : 32|16@1+ (0.1,0) [0|6553.5] "A"  Receiver
 SG_ DIR_dcCableCurrentEst m37 : 16|16@1- (0.1,0) [-3276.8|3276.7] "A"  Receiver
 SG_ DIR_dcCableHeat m47 : 32|16@1+ (0.001,0) [0|65.535] "kA2s"  Receiver
 SG_ DIR_dcCapTemp m64 : 8|8@1+ (1,-40) [-40|215] "C"  Receiver
 SG_ DIR_dcLinkCapTemp m70 : 32|8@1+ (1,-40) [-40|215] "C"  Receiver
 SG_ DIR_decodeHardwareStack m68 : 24|8@1+ (0.4,0) [0|100] "%"  Receiver
 SG_ DIR_driveUnitOdometer m69 : 32|32@1+ (10,0) [0|42949700000] "rev"  Receiver
 SG_ DIR_eepromStack m68 : 32|8@1+ (0.4,0) [0|100] "%"  Receiver
 SG_ DIR_fluxState m42 : 16|4@1+ (1,0) [0|10] ""  Receiver
 SG_ DIR_gainScale m37 : 8|8@1+ (0.01,0) [0|2.55] "scale"  Receiver
 SG_ DIR_gateDriveState m50 : 10|3@1+ (1,0) [0|4] ""  Receiver
 SG_ DIR_gateDriveSupplyState m50 : 8|2@1+ (1,0) [0|3] ""  Receiver
 SG_ DIR_hvDcCableTemp m70 : 40|8@1+ (1,-40) [-40|215] "C"  Receiver
 SG_ DIR_hwFaultCount m69 : 8|4@1+ (1,0) [0|15] ""  Receiver
 SG_ DIR_idleStack m68 : 16|8@1+ (0.4,0) [0|100] "%"  Receiver
 SG_ DIR_immobilizerStack m68 : 56|8@1+ (0.4,0) [0|100] "%"  Receiver
 SG_ DIR_internalAngleFilt m37 : 48|16@1+ (0.0003,0) [0|8] "rad"  Receiver
 SG_ DIR_llrScale m42 : 32|8@1+ (0.015,0) [0|3.825] "scale"  Receiver
 SG_ DIR_llsScale m42 : 24|8@1+ (0.004,0) [0|1.02] "scale"  Receiver
 SG_ DIR_lmScale m36 : 8|8@1+ (0.004,0) [0|1.02] "scale"  Receiver
 SG_ DIR_loadAngle m42 : 40|16@1- (0.0003,0) [-4|4] "rad"  Receiver
 SG_ DIR_loadAngleMargin m37 : 32|16@1- (0.0003,0) [-4|4] "rad"  Receiver
 SG_ DIR_magnetTempEst m47 : 48|8@1+ (1,-40) [-40|180] "C"  Receiver
 SG_ DIR_module10HzStack m66 : 48|8@1+ (0.4,0) [0|100] "%"  Receiver
 SG_ DIR_motorIA m32 : 16|16@1+ (0.1,0) [0|6553.5] "A"  Receiver
 SG_ DIR_motorIAavg m38 : 32|16@1- (0.1,0) [-3276.8|3276.7] "A"  Receiver
 SG_ DIR_motorIB m32 : 32|16@1+ (0.1,0) [0|6553.5] "A"  Receiver
 SG_ DIR_motorIBavg m38 : 48|16@1- (0.1,0) [-3276.8|3276.7] "A"  Receiver
 SG_ DIR_motorIC m32 : 48|16@1+ (0.1,0) [0|6553.5] "A"  Receiver
 SG_ DIR_motorType m128 : 8|6@1+ (1,0) [0|32] ""  Receiver
 SG_ DIR_motorV m34 : 48|16@1+ (2E-005,0) [0|1.3107] "mindex"  Receiver
 SG_ DIR_negDcBusbarTemp m70 : 48|8@1+ (1,-40) [-40|215] "C"  Receiver
 SG_ DIR_offsetA m32 : 8|8@1- (0.1,0) [-12.8|12.7] "A"  Receiver
 SG_ DIR_offsetB m33 : 8|8@1- (0.1,0) [-12.8|12.7] "A"  Receiver
 SG_ DIR_oilPumpMotorSpeed m46 : 8|8@1+ (40,0) [0|10200] "RPM"  Receiver
 SG_ DIR_oilPumpPhaseVoltage m46 : 16|8@1+ (0.1,0) [0|25.4] "V"  Receiver
 SG_ DIR_oilPumpPressureEstimateMax m46 : 24|8@1+ (2,0) [0|500] "kPa"  Receiver
 SG_ DIR_oilPumpPressureExpectedMin m46 : 32|8@1+ (2,0) [0|500] "kPa"  Receiver
 SG_ DIR_pcsTemp m64 : 24|8@1+ (1,-40) [-40|215] "C"  Receiver
 SG_ DIR_peakFlux m36 : 48|16@1+ (0.0001,0) [0|6.5535] "Wb"  Receiver
 SG_ DIR_peakIQref m38 : 16|16@1+ (0.1,0) [0|6553.5] "A"  Receiver
 SG_ DIR_phaseOutBusbarTemp m70 : 8|8@1+ (1,-40) [-40|215] "C"  Receiver
 SG_ DIR_phaseOutBusbarWeldTemp m70 : 16|8@1+ (1,-40) [-40|215] "C"  Receiver
 SG_ DIR_phaseOutLugTemp m70 : 24|8@1+ (1,-40) [-40|215] "C"  Receiver
 SG_ DIR_posDcBusbarTemp m70 : 56|8@1+ (1,-40) [-40|215] "C"  Receiver
 SG_ DIR_powerStageSafeState m50 : 13|2@1+ (1,0) [0|3] ""  Receiver
 SG_ DIR_pwmState m63 : 48|2@1+ (1,0) [0|3] ""  Receiver
 SG_ DIR_pwrSatChargeCurrent m42 : 8|8@1+ (0.4,0) [0|102] "%"  Receiver
 SG_ DIR_pwrSatDischargeCurrent m40 : 8|8@1+ (0.4,0) [0|102] "%"  Receiver
 SG_ DIR_pwrSatMaxBusVoltage m39 : 48|8@1+ (0.4,0) [0|102] "%"  Receiver
 SG_ DIR_pwrSatMaxDischargePower m39 : 16|8@1+ (0.4,0) [0|102] "%"  Receiver
 SG_ DIR_pwrSatMaxRegenPower m39 : 24|8@1+ (0.4,0) [0|102] "%"  Receiver
 SG_ DIR_pwrSatMinBusVoltage m39 : 56|8@1+ (0.4,0) [0|102] "%"  Receiver
 SG_ DIR_resolverClaMIA m48 : 43|1@1+ (1,0) [0|1] ""  Receiver
 SG_ DIR_resolverCommonGain m48 : 32|8@1+ (0.025,0) [0|5] "1"  Receiver
 SG_ DIR_resolverCosFiltered m52 : 32|8@1- (0.01,0) [-1|1] "1"  Receiver
 SG_ DIR_resolverCosRmsSquared m52 : 16|8@1+ (0.005,0) [0|1] "1"  Receiver
 SG_ DIR_resolverErrorRmsSquared m52 : 48|8@1+ (0.005,0) [0|1] "1"  Receiver
 SG_ DIR_resolverNoCarrier m48 : 41|1@1+ (1,0) [0|1] ""  Receiver
 SG_ DIR_resolverNoPhaseLock m48 : 42|1@1+ (1,0) [0|1] ""  Receiver
 SG_ DIR_resolverOffsetCos m48 : 8|8@1+ (0.015,0) [0|3.3] "V"  Receiver
 SG_ DIR_resolverOffsetSin m48 : 16|8@1+ (0.015,0) [0|3.3] "V"  Receiver
 SG_ DIR_resolverPhaseOffset m48 : 24|8@1+ (0.1,7.5) [7.5|32.5] "us"  Receiver
 SG_ DIR_resolverReady m48 : 40|1@1+ (1,0) [0|1] ""  Receiver
 SG_ DIR_resolverSinFiltered m52 : 40|8@1- (0.01,0) [-1|1] "1"  Receiver
 SG_ DIR_resolverSinRmsSquared m52 : 24|8@1+ (0.005,0) [0|1] "1"  Receiver
 SG_ DIR_rotorFlux m47 : 16|16@1+ (0.0001,0) [0|6.5535] "Wb"  Receiver
 SG_ DIR_rotorMaxMagnetTemp m72 : 16|8@1+ (1,-40) [-40|215] "C"  Receiver
 SG_ DIR_rotorOffsetEst m43 : 8|12@1- (0.01,0) [-20|20] "deg"  Receiver
 SG_ DIR_rotorOffsetLearningState m63 : 8|4@1+ (1,0) [0|9] ""  Receiver
 SG_ DIR_rotorOffsetMean m43 : 20|12@1- (0.01,0) [-20|20] "deg"  Receiver
 SG_ DIR_rsScale m34 : 8|8@1+ (0.01,0) [0|2.55] "scale"  Receiver
 SG_ DIR_soptMaxCurrentMagSqrd m49 : 40|16@1+ (100,0) [0|6553500] "A2"  Receiver
 SG_ DIR_soptTimeToOff m49 : 24|11@1+ (0.05,0) [0|100] "ms"  Receiver
 SG_ DIR_soptTimeToTrip m49 : 8|8@1+ (0.05,0) [0|10] "ms"  Receiver
 SG_ DIR_soptTripDelay m49 : 16|8@1+ (0.05,0) [0|10] "ms"  Receiver
 SG_ DIR_ssmState m38 : 8|4@1+ (1,0) [0|8] ""  Receiver
 SG_ DIR_statorEndWindingTemp m72 : 8|8@1+ (1,-40) [-40|215] "C"  Receiver
 SG_ DIR_statorFluxFdb m35 : 32|16@1+ (0.0001,0) [0|6.5535] "Wb"  Receiver
 SG_ DIR_statorFluxRef m35 : 16|16@1+ (0.0001,0) [0|6.5535] "Wb"  Receiver
 SG_ DIR_statorIDfdb m33 : 32|16@1- (0.1,0) [-3276.8|3276.7] "A"  Receiver
 SG_ DIR_statorIDref m33 : 16|16@1- (0.1,0) [-3276.8|3276.7] "A"  Receiver
 SG_ DIR_statorIQfdb m34 : 32|16@1- (0.1,0) [-3276.8|3276.7] "A"  Receiver
 SG_ DIR_statorIQref m34 : 16|16@1- (0.1,0) [-3276.8|3276.7] "A"  Receiver
 SG_ DIR_statorTemp1 m64 : 32|8@1+ (1,-40) [-40|215] "C"  Receiver
 SG_ DIR_statorTemp2 m64 : 40|8@1+ (1,-40) [-40|215] "C"  Receiver
 SG_ DIR_statorVD m36 : 32|16@1- (4E-005,0) [-1.31072|1.31068] "mindex"  Receiver
 SG_ DIR_statorVDFiltered m63 : 16|16@1- (4E-005,0) [-1.31072|1.31068] "mindex"  Receiver
 SG_ DIR_statorVQ m36 : 16|16@1- (4E-005,0) [-1.31072|1.31068] "mindex"  Receiver
 SG_ DIR_statorVQFiltered m63 : 32|16@1- (4E-005,0) [-1.31072|1.31068] "mindex"  Receiver
 SG_ DIR_sysHeatPowerOptimal m50 : 16|8@1+ (0.08,0) [0|20] "kW"  Receiver
 SG_ DIR_systemStack m68 : 8|8@1+ (0.4,0) [0|100] "%"  Receiver
 SG_ DIR_systemTorqueCommand m35 : 48|16@1- (0.035,0) [-1146.88|1146.85] "Nm"  Receiver
 SG_ DIR_tcMaxRequest m40 : 16|8@1+ (5,0) [0|1275] "Nm"  Receiver
 SG_ DIR_tcMinRequest m40 : 24|8@1+ (5,0) [0|1275] "Nm"  Receiver
 SG_ DIR_torquePerAmp m33 : 48|16@1+ (0.0001,0) [0|6.5535] "Nm/A"  Receiver
 SG_ DIR_tqSatMotorCurrent m39 : 40|8@1+ (0.4,0) [0|102] "%"  Receiver
 SG_ DIR_tqSatMotorVoltage m39 : 32|8@1+ (0.4,0) [0|102] "%"  Receiver
 SG_ DIR_tqSatThermal m39 : 8|8@1+ (0.4,0) [0|102] "%"  Receiver
 SG_ DIR_tqSatUiDriveTorque m40 : 32|8@1+ (0.4,0) [0|102] "%"  Receiver
 SG_ DIR_tqSatUiRegenTorque m40 : 40|8@1+ (0.4,0) [0|102] "%"  Receiver
 SG_ DIR_tqScaleDifferential m35 : 8|8@1+ (0.4,0) [0|102] "%"  Receiver
 SG_ DIR_tqScaleMaxMotorSpeed m40 : 48|8@1+ (0.4,0) [0|102] "%"  Receiver
 SG_ DIR_tqScaleShift m40 : 56|8@1+ (0.4,0) [0|102] "%"  Receiver
 SG_ DIR_udsStack m68 : 40|8@1+ (0.4,0) [0|100] "%"  Receiver
 SG_ DIR_usmState m38 : 12|3@1+ (1,0) [0|7] ""  Receiver
 SG_ DIR_veMassInvRaw m41 : 8|12@1+ (1E-007,0.0001) [0.0001|0.0005] "1/kg"  Receiver
 SG_ DIR_veResForce m41 : 20|12@1- (0.0005,0) [-1.024|1.0235] "G"  Receiver
 SG_ DIR_wasteCurrentLimit m41 : 48|16@1+ (0.1,0) [0|6553.5] "A"  Receiver
 SG_ DIR_xcpStack m68 : 48|8@1+ (0.4,0) [0|100] "%"  Receiver

BO_ 1879 ID757DIF_debug: 8 VehicleBus
 SG_ DIF_debugSelector M : 0|8@1+ (1,0) [0|255] ""  Receiver
 SG_ DIF_brakeSwitchNC m42 : 63|1@1+ (1,0) [0|1] ""  Receiver
 SG_ DIF_brakeSwitchNO m42 : 62|1@1+ (1,0) [0|1] ""  Receiver
 SG_ DIF_busbarTemp m64 : 16|8@1+ (1,-40) [-40|215] "C"  Receiver
 SG_ DIF_controlStack m67 : 40|8@1+ (0.4,0) [0|100] "%"  Receiver
 SG_ DIF_cpu100HzAvg m66 : 32|8@1+ (0.4,0) [0|102] "%"  Receiver
 SG_ DIF_cpu100HzMin m66 : 24|8@1+ (0.4,0) [0|102] "%"  Receiver
 SG_ DIF_cpu10HzAvg m66 : 16|8@1+ (0.4,0) [0|102] "%"  Receiver
 SG_ DIF_cpu10HzMin m66 : 8|8@1+ (0.4,0) [0|102] "%"  Receiver
 SG_ DIF_cpu10msMin m66 : 40|8@1+ (0.4,0) [0|102] "%"  Receiver
 SG_ DIF_cpu1HzAvg m128 : 24|8@1+ (0.4,0) [0|102] "%"  Receiver
 SG_ DIF_cpu1HzMin m128 : 16|8@1+ (0.4,0) [0|102] "%"  Receiver
 SG_ DIF_cpu1kHzAvg m67 : 16|8@1+ (0.4,0) [0|102] "%"  Receiver
 SG_ DIF_cpu1kHzMin m67 : 8|8@1+ (0.4,0) [0|102] "%"  Receiver
 SG_ DIF_cpu20kHzAvg m67 : 32|8@1+ (0.4,0) [0|102] "%"  Receiver
 SG_ DIF_cpu20kHzMin m67 : 24|8@1+ (0.4,0) [0|102] "%"  Receiver
 SG_ DIF_cpuIDWord0 m131 : 16|16@1+ (1,0) [0|65535] ""  Receiver
 SG_ DIF_cpuIDWord1 m132 : 16|16@1+ (1,0) [0|65535] ""  Receiver
 SG_ DIF_cpuIDWord2 m132 : 32|16@1+ (1,0) [0|65535] ""  Receiver
 SG_ DIF_cpuIDWord3 m132 : 48|16@1+ (1,0) [0|65535] ""  Receiver
 SG_ DIF_crc m131 : 32|32@1+ (1,0) [0|4294970000] ""  Receiver
 SG_ DIF_currentLimit m41 : 32|16@1+ (0.1,0) [0|6553.5] "A"  Receiver
 SG_ DIF_dcCableCurrentEst m37 : 16|16@1- (0.1,0) [-3276.8|3276.7] "A"  Receiver
 SG_ DIF_dcCableHeat m47 : 32|16@1+ (0.001,0) [0|65.535] "kA2s"  Receiver
 SG_ DIF_dcCapTemp m64 : 8|8@1+ (1,-40) [-40|215] "C"  Receiver
 SG_ DIF_dcLinkCapTemp m70 : 32|8@1+ (1,-40) [-40|215] "C"  Receiver
 SG_ DIF_decodeHardwareStack m68 : 24|8@1+ (0.4,0) [0|100] "%"  Receiver
 SG_ DIF_driveUnitOdometer m69 : 32|32@1+ (10,0) [0|42949700000] "rev"  Receiver
 SG_ DIF_eepromStack m68 : 32|8@1+ (0.4,0) [0|100] "%"  Receiver
 SG_ DIF_fluxState m42 : 16|4@1+ (1,0) [0|10] ""  Receiver
 SG_ DIF_gainScale m37 : 8|8@1+ (0.01,0) [0|2.55] "scale"  Receiver
 SG_ DIF_gateDriveState m50 : 10|3@1+ (1,0) [0|4] ""  Receiver
 SG_ DIF_gateDriveSupplyState m50 : 8|2@1+ (1,0) [0|3] ""  Receiver
 SG_ DIF_hvDcCableTemp m70 : 40|8@1+ (1,-40) [-40|215] "C"  Receiver
 SG_ DIF_hwFaultCount m69 : 8|4@1+ (1,0) [0|15] ""  Receiver
 SG_ DIF_idleStack m68 : 16|8@1+ (0.4,0) [0|100] "%"  Receiver
 SG_ DIF_immobilizerStack m68 : 56|8@1+ (0.4,0) [0|100] "%"  Receiver
 SG_ DIF_internalAngleFilt m37 : 48|16@1+ (0.0003,0) [0|8] "rad"  Receiver
 SG_ DIF_llrScale m42 : 32|8@1+ (0.015,0) [0|3.825] "scale"  Receiver
 SG_ DIF_llsScale m42 : 24|8@1+ (0.004,0) [0|1.02] "scale"  Receiver
 SG_ DIF_lmScale m36 : 8|8@1+ (0.004,0) [0|1.02] "scale"  Receiver
 SG_ DIF_loadAngle m42 : 40|16@1- (0.0003,0) [-4|4] "rad"  Receiver
 SG_ DIF_loadAngleMargin m37 : 32|16@1- (0.0003,0) [-4|4] "rad"  Receiver
 SG_ DIF_magnetTempEst m47 : 48|8@1+ (1,-40) [-40|180] "C"  Receiver
 SG_ DIF_module10HzStack m66 : 48|8@1+ (0.4,0) [0|100] "%"  Receiver
 SG_ DIF_motorIA m32 : 16|16@1+ (0.1,0) [0|6553.5] "A"  Receiver
 SG_ DIF_motorIAavg m38 : 32|16@1- (0.1,0) [-3276.8|3276.7] "A"  Receiver
 SG_ DIF_motorIB m32 : 32|16@1+ (0.1,0) [0|6553.5] "A"  Receiver
 SG_ DIF_motorIBavg m38 : 48|16@1- (0.1,0) [-3276.8|3276.7] "A"  Receiver
 SG_ DIF_motorIC m32 : 48|16@1+ (0.1,0) [0|6553.5] "A"  Receiver
 SG_ DIF_motorType m128 : 8|6@1+ (1,0) [0|32] ""  Receiver
 SG_ DIF_motorV m34 : 48|16@1+ (2E-005,0) [0|1.3107] "mindex"  Receiver
 SG_ DIF_negDcBusbarTemp m70 : 48|8@1+ (1,-40) [-40|215] "C"  Receiver
 SG_ DIF_offsetA m32 : 8|8@1- (0.1,0) [-12.8|12.7] "A"  Receiver
 SG_ DIF_offsetB m33 : 8|8@1- (0.1,0) [-12.8|12.7] "A"  Receiver
 SG_ DIF_oilPumpMotorSpeed m46 : 8|8@1+ (40,0) [0|10200] "RPM"  Receiver
 SG_ DIF_oilPumpPhaseVoltage m46 : 16|8@1+ (0.1,0) [0|25.4] "V"  Receiver
 SG_ DIF_oilPumpPressureEstimateMax m46 : 24|8@1+ (2,0) [0|500] "kPa"  Receiver
 SG_ DIF_oilPumpPressureExpectedMin m46 : 32|8@1+ (2,0) [0|500] "kPa"  Receiver
 SG_ DIF_pcsTemp m64 : 24|8@1+ (1,-40) [-40|215] "C"  Receiver
 SG_ DIF_peakFlux m36 : 48|16@1+ (0.0001,0) [0|6.5535] "Wb"  Receiver
 SG_ DIF_peakIQref m38 : 16|16@1+ (0.1,0) [0|6553.5] "A"  Receiver
 SG_ DIF_phaseOutBusbarTemp m70 : 8|8@1+ (1,-40) [-40|215] "C"  Receiver
 SG_ DIF_phaseOutBusbarWeldTemp m70 : 16|8@1+ (1,-40) [-40|215] "C"  Receiver
 SG_ DIF_phaseOutLugTemp m70 : 24|8@1+ (1,-40) [-40|215] "C"  Receiver
 SG_ DIF_posDcBusbarTemp m70 : 56|8@1+ (1,-40) [-40|215] "C"  Receiver
 SG_ DIF_powerStageSafeState m50 : 13|2@1+ (1,0) [0|3] ""  Receiver
 SG_ DIF_pwmState m63 : 48|2@1+ (1,0) [0|3] ""  Receiver
 SG_ DIF_pwrSatChargeCurrent m42 : 8|8@1+ (0.4,0) [0|102] "%"  Receiver
 SG_ DIF_pwrSatDischargeCurrent m40 : 8|8@1+ (0.4,0) [0|102] "%"  Receiver
 SG_ DIF_pwrSatMaxBusVoltage m39 : 48|8@1+ (0.4,0) [0|102] "%"  Receiver
 SG_ DIF_pwrSatMaxDischargePower m39 : 16|8@1+ (0.4,0) [0|102] "%"  Receiver
 SG_ DIF_pwrSatMaxRegenPower m39 : 24|8@1+ (0.4,0) [0|102] "%"  Receiver
 SG_ DIF_pwrSatMinBusVoltage m39 : 56|8@1+ (0.4,0) [0|102] "%"  Receiver
 SG_ DIF_resolverClaMIA m48 : 43|1@1+ (1,0) [0|1] ""  Receiver
 SG_ DIF_resolverCommonGain m48 : 32|8@1+ (0.025,0) [0|5] "1"  Receiver
 SG_ DIF_resolverCosFiltered m52 : 32|8@1- (0.01,0) [-1|1] "1"  Receiver
 SG_ DIF_resolverCosRmsSquared m52 : 16|8@1+ (0.005,0) [0|1] "1"  Receiver
 SG_ DIF_resolverErrorRmsSquared m52 : 48|8@1+ (0.005,0) [0|1] "1"  Receiver
 SG_ DIF_resolverNoCarrier m48 : 41|1@1+ (1,0) [0|1] ""  Receiver
 SG_ DIF_resolverNoPhaseLock m48 : 42|1@1+ (1,0) [0|1] ""  Receiver
 SG_ DIF_resolverOffsetCos m48 : 8|8@1+ (0.015,0) [0|3.3] "V"  Receiver
 SG_ DIF_resolverOffsetSin m48 : 16|8@1+ (0.015,0) [0|3.3] "V"  Receiver
 SG_ DIF_resolverPhaseOffset m48 : 24|8@1+ (0.1,7.5) [7.5|32.5] "us"  Receiver
 SG_ DIF_resolverReady m48 : 40|1@1+ (1,0) [0|1] ""  Receiver
 SG_ DIF_resolverSinFiltered m52 : 40|8@1- (0.01,0) [-1|1] "1"  Receiver
 SG_ DIF_resolverSinRmsSquared m52 : 24|8@1+ (0.005,0) [0|1] "1"  Receiver
 SG_ DIF_rotorFlux m47 : 16|16@1+ (0.0001,0) [0|6.5535] "Wb"  Receiver
 SG_ DIF_rotorMaxMagnetTemp m72 : 16|8@1+ (1,-40) [-40|215] "C"  Receiver
 SG_ DIF_rotorOffsetEst m43 : 8|12@1- (0.01,0) [-20|20] "deg"  Receiver
 SG_ DIF_rotorOffsetLearningState m63 : 8|4@1+ (1,0) [0|9] ""  Receiver
 SG_ DIF_rotorOffsetMean m43 : 20|12@1- (0.01,0) [-20|20] "deg"  Receiver
 SG_ DIF_rsScale m34 : 8|8@1+ (0.01,0) [0|2.55] "scale"  Receiver
 SG_ DIF_soptMaxCurrentMagSqrd m49 : 40|16@1+ (100,0) [0|6553500] "A2"  Receiver
 SG_ DIF_soptTimeToOff m49 : 24|11@1+ (0.05,0) [0|100] "ms"  Receiver
 SG_ DIF_soptTimeToTrip m49 : 8|8@1+ (0.05,0) [0|10] "ms"  Receiver
 SG_ DIF_soptTripDelay m49 : 16|8@1+ (0.05,0) [0|10] "ms"  Receiver
 SG_ DIF_ssmState m38 : 8|4@1+ (1,0) [0|8] ""  Receiver
 SG_ DIF_statorEndWindingTemp m72 : 8|8@1+ (1,-40) [-40|215] "C"  Receiver
 SG_ DIF_statorFluxFdb m35 : 32|16@1+ (0.0001,0) [0|6.5535] "Wb"  Receiver
 SG_ DIF_statorFluxRef m35 : 16|16@1+ (0.0001,0) [0|6.5535] "Wb"  Receiver
 SG_ DIF_statorIDfdb m33 : 32|16@1- (0.1,0) [-3276.8|3276.7] "A"  Receiver
 SG_ DIF_statorIDref m33 : 16|16@1- (0.1,0) [-3276.8|3276.7] "A"  Receiver
 SG_ DIF_statorIQfdb m34 : 32|16@1- (0.1,0) [-3276.8|3276.7] "A"  Receiver
 SG_ DIF_statorIQref m34 : 16|16@1- (0.1,0) [-3276.8|3276.7] "A"  Receiver
 SG_ DIF_statorTemp1 m64 : 32|8@1+ (1,-40) [-40|215] "C"  Receiver
 SG_ DIF_statorTemp2 m64 : 40|8@1+ (1,-40) [-40|215] "C"  Receiver
 SG_ DIF_statorVD m36 : 32|16@1- (4E-005,0) [-1.31072|1.31068] "mindex"  Receiver
 SG_ DIF_statorVDFiltered m63 : 16|16@1- (4E-005,0) [-1.31072|1.31068] "mindex"  Receiver
 SG_ DIF_statorVQ m36 : 16|16@1- (4E-005,0) [-1.31072|1.31068] "mindex"  Receiver
 SG_ DIF_statorVQFiltered m63 : 32|16@1- (4E-005,0) [-1.31072|1.31068] "mindex"  Receiver
 SG_ DIF_sysHeatPowerOptimal m50 : 16|8@1+ (0.08,0) [0|20] "kW"  Receiver
 SG_ DIF_systemStack m68 : 8|8@1+ (0.4,0) [0|100] "%"  Receiver
 SG_ DIF_systemTorqueCommand m35 : 48|16@1- (0.035,0) [-1146.88|1146.85] "Nm"  Receiver
 SG_ DIF_tcMaxRequest m40 : 16|8@1+ (5,0) [0|1275] "Nm"  Receiver
 SG_ DIF_tcMinRequest m40 : 24|8@1+ (5,0) [0|1275] "Nm"  Receiver
 SG_ DIF_torquePerAmp m33 : 48|16@1+ (0.0001,0) [0|6.5535] "Nm/A"  Receiver
 SG_ DIF_tqSatMotorCurrent m39 : 40|8@1+ (0.4,0) [0|102] "%"  Receiver
 SG_ DIF_tqSatMotorVoltage m39 : 32|8@1+ (0.4,0) [0|102] "%"  Receiver
 SG_ DIF_tqSatThermal m39 : 8|8@1+ (0.4,0) [0|102] "%"  Receiver
 SG_ DIF_tqSatUiDriveTorque m40 : 32|8@1+ (0.4,0) [0|102] "%"  Receiver
 SG_ DIF_tqSatUiRegenTorque m40 : 40|8@1+ (0.4,0) [0|102] "%"  Receiver
 SG_ DIF_tqScaleDifferential m35 : 8|8@1+ (0.4,0) [0|102] "%"  Receiver
 SG_ DIF_tqScaleMaxMotorSpeed m40 : 48|8@1+ (0.4,0) [0|102] "%"  Receiver
 SG_ DIF_tqScaleShift m40 : 56|8@1+ (0.4,0) [0|102] "%"  Receiver
 SG_ DIF_udsStack m68 : 40|8@1+ (0.4,0) [0|100] "%"  Receiver
 SG_ DIF_usmState m38 : 12|3@1+ (1,0) [0|7] ""  Receiver
 SG_ DIF_veMassInvRaw m41 : 8|12@1+ (1E-007,0.0001) [0.0001|0.0005] "1/kg"  Receiver
 SG_ DIF_veResForce m41 : 20|12@1- (0.0005,0) [-1.024|1.0235] "G"  Receiver
 SG_ DIF_wasteCurrentLimit m41 : 48|16@1+ (0.1,0) [0|6553.5] "A"  Receiver
 SG_ DIF_xcpStack m68 : 48|8@1+ (0.4,0) [0|100] "%"  Receiver

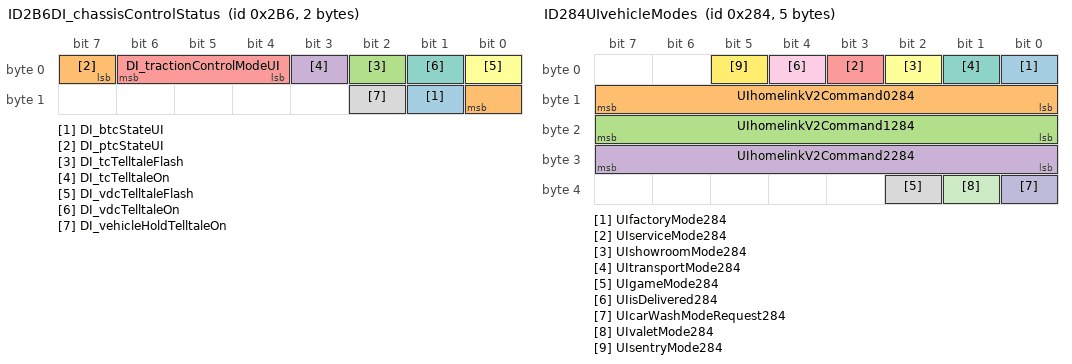
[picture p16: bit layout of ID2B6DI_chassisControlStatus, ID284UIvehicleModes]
BO_ 694 ID2B6DI_chassisControlStatus: 2 VehicleBus
 SG_ DI_btcStateUI : 9|1@1+ (1,0) [0|1] ""  Receiver
 SG_ DI_ptcStateUI : 7|2@1+ (1,0) [0|3] ""  Receiver
 SG_ DI_tcTelltaleFlash : 2|1@1+ (1,0) [0|1] ""  Receiver
 SG_ DI_tcTelltaleOn : 3|1@1+ (1,0) [0|1] ""  Receiver
 SG_ DI_tractionControlModeUI : 4|3@1+ (1,0) [0|6] ""  Receiver
 SG_ DI_vdcTelltaleFlash : 0|1@1+ (1,0) [0|1] ""  Receiver
 SG_ DI_vdcTelltaleOn : 1|1@1+ (1,0) [0|1] ""  Receiver
 SG_ DI_vehicleHoldTelltaleOn : 10|1@1+ (1,0) [0|1] ""  Receiver

BO_ 644 ID284UIvehicleModes: 5 VehicleBus
 SG_ UIfactoryMode284 : 0|1@1+ (1,0) [0|0] ""  Receiver
 SG_ UIhomelinkV2Command0284 : 8|8@1+ (1,0) [0|0] ""  Receiver
 SG_ UIhomelinkV2Command1284 : 16|8@1+ (1,0) [0|0] ""  Receiver
 SG_ UIhomelinkV2Command2284 : 24|8@1+ (1,0) [0|0] ""  Receiver
 SG_ UIserviceMode284 : 3|1@1+ (1,0) [0|0] ""  Receiver
 SG_ UIshowroomMode284 : 2|1@1+ (1,0) [0|0] ""  Receiver
 SG_ UItransportMode284 : 1|1@1+ (1,0) [0|0] ""  Receiver
 SG_ UIgameMode284 : 34|1@1+ (1,0) [0|0] ""  Receiver
 SG_ UIisDelivered284 : 4|1@1+ (1,0) [0|0] ""  Receiver
 SG_ UIcarWashModeRequest284 : 32|1@1+ (1,0) [0|0] ""  Receiver
 SG_ UIvaletMode284 : 33|1@1+ (1,0) [0|0] ""  Receiver
 SG_ UIsentryMode284 : 5|1@1+ (1,0) [0|0] ""  Receiver

BO_ 545 ID221VCFRONT_LVPowerState: 8 VehicleBus
 SG_ VCFRONT_LVPowerStateIndex M : 0|5@1+ (1,0) [0|1] ""  Receiver
 SG_ VCFRONT_CMPDLVState m1 : 18|2@1+ (1,0) [0|3] ""  Receiver
 SG_ VCFRONT_amplifierLVRequest m0 : 28|2@1+ (1,0) [0|3] ""  Receiver
 SG_ VCFRONT_cpLVRequest m1 : 8|2@1+ (1,0) [0|3] ""  Receiver
 SG_ VCFRONT_das1HighCurrentLVState m0 : 30|2@1+ (1,0) [0|3] ""  Receiver
 SG_ VCFRONT_das2HighCurrentLVState m0 : 32|2@1+ (1,0) [0|3] ""  Receiver
 SG_ VCFRONT_difLVState m0 : 36|2@1+ (1,0) [0|3] ""  Receiver
 SG_ VCFRONT_dirLVRequest m0 : 34|2@1+ (1,0) [0|3] ""  Receiver
 SG_ VCFRONT_epasLVState m1 : 10|2@1+ (1,0) [0|3] ""  Receiver
 SG_ VCFRONT_espLVState m0 : 10|2@1+ (1,0) [0|3] ""  Receiver
 SG_ VCFRONT_hvacCompLVState m0 : 14|2@1+ (1,0) [0|3] ""  Receiver
 SG_ VCFRONT_hvcLVRequest m1 : 12|2@1+ (1,0) [0|3] ""  Receiver
 SG_ VCFRONT_iBoosterLVState m0 : 24|2@1+ (1,0) [0|3] ""  Receiver
 SG_ VCFRONT_ocsLVRequest m0 : 42|2@1+ (1,0) [0|3] ""  Receiver
 SG_ VCFRONT_oilPumpFrontLVState m0 : 38|2@1+ (1,0) [0|3] ""  Receiver
 SG_ VCFRONT_oilPumpRearLVRequest m0 : 40|2@1+ (1,0) [0|3] ""  Receiver
 SG_ VCFRONT_parkLVState m0 : 8|2@1+ (1,0) [0|3] ""  Receiver
 SG_ VCFRONT_pcsLVState m1 : 16|2@1+ (1,0) [0|3] ""  Receiver
 SG_ VCFRONT_ptcLVRequest m0 : 16|2@1+ (1,0) [0|3] ""  Receiver
 SG_ VCFRONT_radcLVState m0 : 12|2@1+ (1,0) [0|3] ""  Receiver
 SG_ VCFRONT_rcmLVRequest m0 : 22|2@1+ (1,0) [0|3] ""  Receiver
 SG_ VCFRONT_sccmLVRequest m0 : 18|2@1+ (1,0) [0|3] ""  Receiver
 SG_ VCFRONT_tasLVState m1 : 14|2@1+ (1,0) [0|3] ""  Receiver
 SG_ VCFRONT_tpmsLVRequest m0 : 20|2@1+ (1,0) [0|3] ""  Receiver
 SG_ VCFRONT_tunerLVRequest m0 : 26|2@1+ (1,0) [0|3] ""  Receiver
 SG_ VCFRONT_uiHiCurrentLVState m0 : 48|2@1+ (1,0) [0|3] ""  Receiver
 SG_ VCFRONT_vcleftHiCurrentLVState m0 : 44|2@1+ (1,0) [0|3] ""  Receiver
 SG_ VCFRONT_vcrightHiCurrentLVState m0 : 46|2@1+ (1,0) [0|3] ""  Receiver

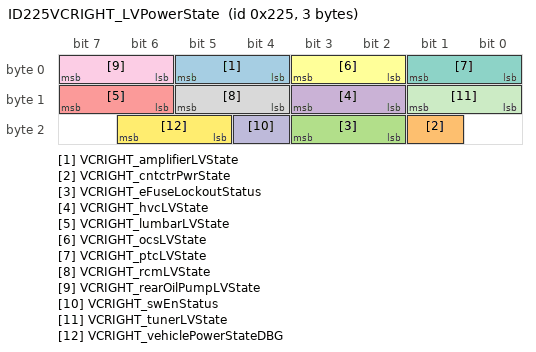
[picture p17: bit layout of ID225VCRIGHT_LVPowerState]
BO_ 549 ID225VCRIGHT_LVPowerState: 3 VehicleBus
 SG_ VCRIGHT_amplifierLVState : 4|2@1+ (1,0) [0|3] ""  Receiver
 SG_ VCRIGHT_cntctrPwrState : 17|1@1+ (1,0) [0|1] ""  Receiver
 SG_ VCRIGHT_eFuseLockoutStatus : 18|2@1+ (1,0) [0|2] ""  Receiver
 SG_ VCRIGHT_hvcLVState : 10|2@1+ (1,0) [0|3] ""  Receiver
 SG_ VCRIGHT_lumbarLVState : 14|2@1+ (1,0) [0|3] ""  Receiver
 SG_ VCRIGHT_ocsLVState : 2|2@1+ (1,0) [0|3] ""  Receiver
 SG_ VCRIGHT_ptcLVState : 0|2@1+ (1,0) [0|3] ""  Receiver
 SG_ VCRIGHT_rcmLVState : 12|2@1+ (1,0) [0|3] ""  Receiver
 SG_ VCRIGHT_rearOilPumpLVState : 6|2@1+ (1,0) [0|3] ""  Receiver
 SG_ VCRIGHT_swEnStatus : 20|1@1+ (1,0) [0|1] ""  Receiver
 SG_ VCRIGHT_tunerLVState : 8|2@1+ (1,0) [0|3] ""  Receiver
 SG_ VCRIGHT_vehiclePowerStateDBG : 21|2@1+ (1,0) [0|3] ""  Receiver

BO_ 753 ID2F1VCFRONT_eFuseDebugStatus: 8 VehicleBus
 SG_ VCFRONT_eFuseDebugStatusIndex M : 0|5@1+ (1,0) [0|18] ""  Receiver
 SG_ VCFRONT_ChargePumpVoltage m16 : 24|16@1+ (0.00544368,0) [0|356.751] "V"  Receiver
 SG_ VCFRONT_EPAS3PCurrent m4 : 47|16@1+ (0.1,0) [0|6553.5] "A"  Receiver
 SG_ VCFRONT_EPAS3PFault m4 : 10|1@1+ (1,0) [0|1] ""  Receiver
 SG_ VCFRONT_EPAS3PSelfTestResult m4 : 11|4@1+ (1,0) [0|11] ""  Receiver
 SG_ VCFRONT_EPAS3PState m4 : 8|2@1+ (1,0) [0|2] ""  Receiver
 SG_ VCFRONT_EPAS3PTemp m4 : 15|11@1+ (0.125,-40) [-40|150] "C"  Receiver
 SG_ VCFRONT_EPAS3PVoltage m4 : 31|16@1+ (0.1,0) [0|6553.5] "V"  Receiver
 SG_ VCFRONT_EPAS3SCurrent m5 : 47|16@1+ (0.1,0) [0|6553.5] "A"  Receiver
 SG_ VCFRONT_EPAS3SFault m5 : 10|1@1+ (1,0) [0|1] ""  Receiver
 SG_ VCFRONT_EPAS3SSelfTestResult m5 : 11|4@1+ (1,0) [0|11] ""  Receiver
 SG_ VCFRONT_EPAS3SState m5 : 8|2@1+ (1,0) [0|2] ""  Receiver
 SG_ VCFRONT_EPAS3STemp m5 : 15|11@1+ (0.125,-40) [-40|150] "C"  Receiver
 SG_ VCFRONT_EPAS3SVoltage m5 : 31|16@1+ (0.1,0) [0|6553.5] "V"  Receiver
 SG_ VCFRONT_ESPMotorCurrent m6 : 47|16@1+ (0.1,0) [0|6553.5] "A"  Receiver
 SG_ VCFRONT_ESPMotorFault m6 : 10|1@1+ (1,0) [0|1] ""  Receiver
 SG_ VCFRONT_ESPMotorSelfTestResult m6 : 11|4@1+ (1,0) [0|11] ""  Receiver
 SG_ VCFRONT_ESPMotorState m6 : 8|2@1+ (1,0) [0|2] ""  Receiver
 SG_ VCFRONT_ESPMotorTemp m6 : 15|11@1+ (0.125,-40) [-40|150] "C"  Receiver
 SG_ VCFRONT_ESPMotorVoltage m6 : 31|16@1+ (0.1,0) [0|6553.5] "V"  Receiver
 SG_ VCFRONT_ESPValveCurrent m7 : 44|16@1+ (0.1,0) [0|6553.5] "A"  Receiver
 SG_ VCFRONT_ESPValveFault m7 : 10|1@1+ (1,0) [0|1] ""  Receiver
 SG_ VCFRONT_ESPValveState m7 : 8|2@1+ (1,0) [0|2] ""  Receiver
 SG_ VCFRONT_ESPValveTemp m7 : 12|11@1+ (0.125,-40) [-40|150] "C"  Receiver
 SG_ VCFRONT_ESPValveVoltage m7 : 28|16@1+ (0.1,0) [0|6553.5] "V"  Receiver
 SG_ VCFRONT_IBSUnfilteredTemperature m17 : 40|16@1- (0.01,0) [-327.68|327.67] "C"  Receiver
 SG_ VCFRONT_PCSCurrent m2 : 47|16@1- (0.1,0) [-3276.8|3276.7] "A"  Receiver
 SG_ VCFRONT_PCSFault m2 : 10|1@1+ (1,0) [0|1] ""  Receiver
 SG_ VCFRONT_PCSState m2 : 8|2@1+ (1,0) [0|2] ""  Receiver
 SG_ VCFRONT_PCSTemp m2 : 15|11@1+ (0.125,-40) [-40|150] "C"  Receiver
 SG_ VCFRONT_PCSVoltage m2 : 31|16@1+ (0.1,0) [0|6553.5] "V"  Receiver
 SG_ VCFRONT_autopilot1Current m8 : 43|16@1+ (0.1,0) [0|6553.5] "A"  Receiver
 SG_ VCFRONT_autopilot1Fault m8 : 10|1@1+ (1,0) [0|1] ""  Receiver
 SG_ VCFRONT_autopilot1State m8 : 8|2@1+ (1,0) [0|2] ""  Receiver
 SG_ VCFRONT_autopilot1Temp m8 : 11|11@1+ (0.125,-40) [-40|150] "C"  Receiver
 SG_ VCFRONT_autopilot1Voltage m8 : 27|16@1+ (0.1,0) [0|6553.5] "V"  Receiver
 SG_ VCFRONT_autopilot2Current m9 : 43|16@1+ (0.1,0) [0|6553.5] "A"  Receiver
 SG_ VCFRONT_autopilot2Fault m9 : 10|1@1+ (1,0) [0|1] ""  Receiver
 SG_ VCFRONT_autopilot2State m9 : 8|2@1+ (1,0) [0|2] ""  Receiver
 SG_ VCFRONT_autopilot2Temp m9 : 11|11@1+ (0.125,-40) [-40|150] "C"  Receiver
 SG_ VCFRONT_autopilot2Voltage m9 : 27|16@1+ (0.1,0) [0|6553.5] "V"  Receiver
 SG_ VCFRONT_chargedIBSAmpHours m17 : 8|16@1+ (1,0) [0|65535] "Ah"  Receiver
 SG_ VCFRONT_dischargedIBSAmpHours m17 : 24|16@1+ (1,0) [0|65535] "Ah"  Receiver
 SG_ VCFRONT_eFuseLockoutVoltage m16 : 8|12@1+ (0.00544368,0) [0|22.2919] "V"  Receiver
 SG_ VCFRONT_headlampLeftCurrent m12 : 10|10@1+ (0.1,0) [0|102.3] "A"  Receiver
 SG_ VCFRONT_headlampLeftFault m12 : 9|1@1+ (1,0) [0|1] ""  Receiver
 SG_ VCFRONT_headlampLeftState m12 : 8|1@1+ (1,0) [0|1] ""  Receiver
 SG_ VCFRONT_headlampLeftTemperature m12 : 48|8@1- (1,-40) [-40|150] "C"  Receiver
 SG_ VCFRONT_headlampLeftVoltage m12 : 20|8@1+ (0.1,0) [0|25.4] "V"  Receiver
 SG_ VCFRONT_headlampRightCurrent m12 : 30|10@1+ (0.1,0) [0|102.3] "A"  Receiver
 SG_ VCFRONT_headlampRightFault m12 : 29|1@1+ (1,0) [0|1] ""  Receiver
 SG_ VCFRONT_headlampRightState m12 : 28|1@1+ (1,0) [0|1] ""  Receiver
 SG_ VCFRONT_headlampRightTemperature m12 : 56|8@1- (1,-40) [-40|150] "C"  Receiver
 SG_ VCFRONT_headlampRightVoltage m12 : 40|8@1+ (0.1,0) [0|25.4] "V"  Receiver
 SG_ VCFRONT_iBoosterCurrent m3 : 47|16@1+ (0.1,0) [0|6553.5] "A"  Receiver
 SG_ VCFRONT_iBoosterFault m3 : 10|1@1+ (1,0) [0|1] ""  Receiver
 SG_ VCFRONT_iBoosterSelfTestResult m3 : 11|4@1+ (1,0) [0|11] ""  Receiver
 SG_ VCFRONT_iBoosterState m3 : 8|2@1+ (1,0) [0|2] ""  Receiver
 SG_ VCFRONT_iBoosterTemp m3 : 15|11@1+ (0.125,-40) [-40|150] "C"  Receiver
 SG_ VCFRONT_iBoosterVoltage m3 : 31|16@1+ (0.1,0) [0|6553.5] "V"  Receiver
 SG_ VCFRONT_leftControllerCurrent m1 : 47|16@1+ (0.1,0) [0|6553.5] "A"  Receiver
 SG_ VCFRONT_leftControllerFault m1 : 10|1@1+ (1,0) [0|1] ""  Receiver
 SG_ VCFRONT_leftControllerState m1 : 8|2@1+ (1,0) [0|2] ""  Receiver
 SG_ VCFRONT_leftControllerTemp m1 : 15|11@1+ (0.125,-40) [-40|150] "C"  Receiver
 SG_ VCFRONT_leftControllerVoltage m1 : 31|16@1+ (0.1,0) [0|6553.5] "V"  Receiver
 SG_ VCFRONT_pcsSelfTestResult m2 : 11|4@1+ (1,0) [0|11] ""  Receiver
 SG_ VCFRONT_pump1AndFanCurrent m14 : 6|16@1+ (0.1,0) [0|6553.5] "A"  Receiver
 SG_ VCFRONT_pump1AndFanState m14 : 5|1@1+ (1,0) [0|1] ""  Receiver
 SG_ VCFRONT_pump1AndFanVoltage m14 : 22|12@1+ (0.1,0) [0|409.5] "V"  Receiver
 SG_ VCFRONT_pump2AndAirCompCurrent m14 : 35|16@1+ (0.1,0) [0|6553.5] "A"  Receiver
 SG_ VCFRONT_pump2AndAirCompState m14 : 34|1@1+ (1,0) [0|1] ""  Receiver
 SG_ VCFRONT_pump2AndAirCompVoltage m14 : 51|12@1+ (0.1,0) [0|409.5] "V"  Receiver
 SG_ VCFRONT_railA_12v m15 : 8|12@1+ (0.00544368,0) [0|22.2919] "V"  Receiver
 SG_ VCFRONT_railA_5v m15 : 32|12@1+ (0.00544368,0) [0|22.2919] "V"  Receiver
 SG_ VCFRONT_railB_12v m15 : 20|12@1+ (0.00544368,0) [0|22.2919] "V"  Receiver
 SG_ VCFRONT_railB_5v m15 : 44|12@1+ (0.00544368,0) [0|22.2919] "V"  Receiver
 SG_ VCFRONT_rightControllerCurrent m0 : 47|16@1+ (0.1,0) [0|6553.5] "A"  Receiver
 SG_ VCFRONT_rightControllerFault m0 : 10|1@1+ (1,0) [0|1] ""  Receiver
 SG_ VCFRONT_rightControllerState m0 : 8|2@1+ (1,0) [0|2] ""  Receiver
 SG_ VCFRONT_rightControllerTemp m0 : 15|11@1+ (0.125,-40) [-40|150] "C"  Receiver
 SG_ VCFRONT_rightControllerVoltage m0 : 31|16@1+ (0.1,0) [0|6553.5] "V"  Receiver
 SG_ VCFRONT_sleepBypassCurrent m10 : 26|16@1+ (0.1,0) [0|6553.5] "A"  Receiver
 SG_ VCFRONT_sleepBypassFault m10 : 9|1@1+ (1,0) [0|1] ""  Receiver
 SG_ VCFRONT_sleepBypassState m10 : 8|1@1+ (1,0) [0|1] ""  Receiver
 SG_ VCFRONT_sleepBypassVoltage m10 : 10|16@1+ (0.1,0) [0|6553.5] "V"  Receiver
 SG_ VCFRONT_uiAudioCurrent m11 : 8|16@1+ (0.1,0) [0|6553.5] "A"  Receiver
 SG_ VCFRONT_uiAudioFault m11 : 6|1@1+ (1,0) [0|1] ""  Receiver
 SG_ VCFRONT_uiAudioState m11 : 5|1@1+ (1,0) [0|1] ""  Receiver
 SG_ VCFRONT_uiCurrent m11 : 32|16@1+ (0.1,0) [0|6553.5] "A"  Receiver
 SG_ VCFRONT_uiFault m11 : 25|1@1+ (1,0) [0|1] ""  Receiver
 SG_ VCFRONT_uiState m11 : 24|1@1+ (1,0) [0|1] ""  Receiver
 SG_ VCFRONT_vbatFusedHighCurrent m13 : 46|16@1+ (0.1,0) [0|6553.5] "A"  Receiver
 SG_ VCFRONT_vbatFusedHighFault m13 : 9|1@1+ (1,0) [0|1] ""  Receiver
 SG_ VCFRONT_vbatFusedHighState m13 : 8|1@1+ (1,0) [0|1] ""  Receiver
 SG_ VCFRONT_vbatFusedHighTemp m13 : 14|11@1+ (0.125,-40) [-40|150] "C"  Receiver
 SG_ VCFRONT_vbatFusedHighVoltage m13 : 30|16@1+ (0.1,0) [0|6553.5] "V"  Receiver
 SG_ VCFRONT_vbatFusedSelfTestResult m13 : 10|4@1+ (1,0) [0|11] ""  Receiver
 SG_ VCFRONT_vcleftSelfTestResult m1 : 11|4@1+ (1,0) [0|11] ""  Receiver
 SG_ VCFRONT_vcrightSelfTestResult m0 : 11|4@1+ (1,0) [0|11] ""  Receiver

CM_ SG_ 130 UI_tripPlanningActive "Navigation Active";
CM_ SG_ 692 PCS_dcdcHvBusVolt "DCDC HV Voltage";
CM_ SG_ 692 PCS_dcdcLvBusVolt "DCDC 12v Voltage";
CM_ SG_ 692 PCS_dcdcLvOutputCurrent "DCDC 12v Output Current";
CM_ SG_ 615 DI_gradeEst "Estimated Grade";
CM_ SG_ 615 DI_mass "Estimated Mass";
CM_ SG_ 642 VCLEFT_hvacBlowerRPMActual "HVAC Blower Speed";
CM_ SG_ 647 PTC_leftCurrentHV "Heater Left Current";
CM_ SG_ 647 PTC_rightCurrentHV "Heater Right Current";
CM_ SG_ 647 PTC_voltageHV "Heater Voltage";
CM_ SG_ 819 UI_acChargeCurrentLimit "UI Charge Current Limit";
CM_ SG_ 826 UI_Range "Range";
CM_ SG_ 826 UI_SOC "State of Charge UI";
CM_ SG_ 826 UI_uSOE "UI fine SOC";
CM_ SG_ 826 UI_ratedWHpM "WHM Rating";
CM_ SG_ 577 VCFRONT_coolantFlowBatActual "Battery Coolant Flow";
CM_ SG_ 577 VCFRONT_coolantFlowPTActual "Powertrain Coolant Flow";
CM_ BO_ 1367 "swapped with 5D7 in old firmware";
CM_ BO_ 1495 "swapped with 557 in old firmware";
CM_ BO_ 2005 "swapped with 757 in old firmware";
CM_ BO_ 1879 "swapped with 7D5 in old firmware";
BA_DEF_ BO_  "GenMsgSendType" ENUM  "Cyclic","SendType1","SendType2","SendType3","SendType4","SendType5","SendType6","SendType7","SendType8","SendType9";
BA_DEF_ BO_  "GenMsgCycleTime" INT 0 0;
BA_DEF_  "BusType" STRING ;
BA_DEF_ SG_  "GenSigEnvVarType" ENUM  "Cyclic","SendType1","SendType2","SendType3","SendType4","SendType5","SendType6","SendType7","SendType8","SendType9","No","Yes","No","Yes","No","Yes","No","Yes","int","float","undef";
BA_DEF_  "Modified" STRING ;
BA_DEF_ BO_  "SystemMessageLongSymbol" STRING ;
BA_DEF_DEF_  "GenMsgSendType" "";
BA_DEF_DEF_  "GenMsgCycleTime" 0;
BA_DEF_DEF_  "BusType" "";
BA_DEF_DEF_  "GenSigEnvVarType" "";
BA_DEF_DEF_  "Modified" "JW2021Aug29";
BA_DEF_DEF_  "SystemMessageLongSymbol" "";
BA_ "BusType" "CAN";
BA_ "GenMsgCycleTime" BO_ 530 100;
BA_ "GenMsgSendType" BO_ 530 0;
BA_ "GenMsgCycleTime" BO_ 819 500;
BA_ "GenMsgCycleTime" BO_ 577 100;
VAL_ 12 UI_autopilotTrial 3 "ACTIVE" 0 "NONE" 1 "START" 2 "STOP" ;
VAL_ 12 UI_cellNetworkTechnology 9 "CELL_NETWORK_CDMA" 2 "CELL_NETWORK_EDGE" 1 "CELL_NETWORK_GPRS" 8 "CELL_NETWORK_GSM" 4 "CELL_NETWORK_HSDPA" 6 "CELL_NETWORK_HSPA" 5 "CELL_NETWORK_HSUPA" 7 "CELL_NETWORK_LTE" 0 "CELL_NETWORK_NONE" 15 "CELL_NETWORK_SNA" 3 "CELL_NETWORK_UMTS" 10 "CELL_NETWORK_WCDMA" ;
VAL_ 12 UI_cellSignalBars 5 "FIVE" 4 "FOUR" 1 "ONE" 7 "SNA" 3 "THREE" 2 "TWO" 0 "ZERO" ;
VAL_ 12 UI_factoryReset 3 "CUSTOMER" 1 "DEVELOPER" 2 "DIAGNOSTIC" 0 "NONE_SNA" ;
VAL_ 130 UI_energyAtDestination 32768 "SNA" 32767 "TRIP_TOO_LONG" ;
VAL_ 130 UI_hindsightEnergy 32768 "SNA" 32767 "TRIP_TOO_LONG" ;
VAL_ 130 UI_predictedEnergy 32768 "SNA" 32767 "TRIP_TOO_LONG" ;
VAL_ 258 VCLEFT_frontLatchStatus 5 "LATCH_AJAR" 2 "LATCH_CLOSED" 3 "LATCH_CLOSING" 7 "LATCH_DEFAULT" 8 "LATCH_FAULT" 1 "LATCH_OPENED" 4 "LATCH_OPENING" 0 "LATCH_SNA" 6 "LATCH_TIMEOUT" ;
VAL_ 258 VCLEFT_mirrorFoldState 1 "MIRROR_FOLD_STATE_FOLDED" 3 "MIRROR_FOLD_STATE_FOLDING" 2 "MIRROR_FOLD_STATE_UNFOLDED" 4 "MIRROR_FOLD_STATE_UNFOLDING" 0 "MIRROR_FOLD_STATE_UNKNOWN" ;
VAL_ 258 VCLEFT_mirrorHeatState 4 "HEATER_STATE_FAULT" 2 "HEATER_STATE_OFF" 3 "HEATER_STATE_OFF_UNAVAILABLE" 1 "HEATER_STATE_ON" 0 "HEATER_STATE_SNA" ;
VAL_ 258 VCLEFT_mirrorRecallState 0 "MIRROR_RECALL_STATE_INIT" 1 "MIRROR_RECALL_STATE_RECALLING_AXIS_1" 2 "MIRROR_RECALL_STATE_RECALLING_AXIS_2" 3 "MIRROR_RECALL_STATE_RECALLING_COMPLETE" 4 "MIRROR_RECALL_STATE_RECALLING_FAILED" 5 "MIRROR_RECALL_STATE_RECALLING_STOPPED" ;
VAL_ 258 VCLEFT_mirrorState 3 "MIRROR_STATE_FOLD_UNFOLD" 0 "MIRROR_STATE_IDLE" 4 "MIRROR_STATE_RECALL" 1 "MIRROR_STATE_TILT_X" 2 "MIRROR_STATE_TILT_Y" ;
VAL_ 258 VCLEFT_rearLatchStatus 5 "LATCH_AJAR" 2 "LATCH_CLOSED" 3 "LATCH_CLOSING" 7 "LATCH_DEFAULT" 8 "LATCH_FAULT" 1 "LATCH_OPENED" 4 "LATCH_OPENING" 0 "LATCH_SNA" 6 "LATCH_TIMEOUT" ;
VAL_ 259 VCRIGHT_frontLatchStatus 5 "LATCH_AJAR" 2 "LATCH_CLOSED" 3 "LATCH_CLOSING" 7 "LATCH_DEFAULT" 8 "LATCH_FAULT" 1 "LATCH_OPENED" 4 "LATCH_OPENING" 0 "LATCH_SNA" 6 "LATCH_TIMEOUT" ;
VAL_ 259 VCRIGHT_mirrorFoldState 1 "MIRROR_FOLD_STATE_FOLDED" 3 "MIRROR_FOLD_STATE_FOLDING" 2 "MIRROR_FOLD_STATE_UNFOLDED" 4 "MIRROR_FOLD_STATE_UNFOLDING" 0 "MIRROR_FOLD_STATE_UNKNOWN" ;
VAL_ 259 VCRIGHT_mirrorRecallState 0 "MIRROR_RECALL_STATE_INIT" 1 "MIRROR_RECALL_STATE_RECALLING_AXIS_1" 2 "MIRROR_RECALL_STATE_RECALLING_AXIS_2" 3 "MIRROR_RECALL_STATE_RECALLING_COMPLETE" 4 "MIRROR_RECALL_STATE_RECALLING_FAILED" 5 "MIRROR_RECALL_STATE_RECALLING_STOPPED" ;
VAL_ 259 VCRIGHT_mirrorState 3 "MIRROR_STATE_FOLD_UNFOLD" 0 "MIRROR_STATE_IDLE" 4 "MIRROR_STATE_RECALL" 1 "MIRROR_STATE_TILT_X" 2 "MIRROR_STATE_TILT_Y" ;
VAL_ 259 VCRIGHT_rearLatchStatus 5 "LATCH_AJAR" 2 "LATCH_CLOSED" 3 "LATCH_CLOSING" 7 "LATCH_DEFAULT" 8 "LATCH_FAULT" 1 "LATCH_OPENED" 4 "LATCH_OPENING" 0 "LATCH_SNA" 6 "LATCH_TIMEOUT" ;
VAL_ 259 VCRIGHT_trunkLatchStatus 5 "LATCH_AJAR" 2 "LATCH_CLOSED" 3 "LATCH_CLOSING" 7 "LATCH_DEFAULT" 8 "LATCH_FAULT" 1 "LATCH_OPENED" 4 "LATCH_OPENING" 0 "LATCH_SNA" 6 "LATCH_TIMEOUT" ;
VAL_ 275 GTW_bmpState 2 "BMP_STATE_ASLEEP" 3 "BMP_STATE_MIA" 0 "BMP_STATE_OFF" 1 "BMP_STATE_ON" 5 "BMP_STATE_POWER_CYCLE" 4 "BMP_STATE_RESET" 255 "DUMMY" ;
VAL_ 281 VCSEC_windowRequestPercent 127 "SNA" ;
VAL_ 281 VCSEC_windowRequestType 3 "WINDOW_REQUEST_GOTO_CLOSED" 2 "WINDOW_REQUEST_GOTO_CRACKED" 1 "WINDOW_REQUEST_GOTO_PERCENT" 0 "WINDOW_REQUEST_IDLE" ;
VAL_ 290 VCLEFT_frontDoorState 1 "DOOR_STATE_CLOSED" 4 "DOOR_STATE_OPEN_OR_AJAR" 3 "DOOR_STATE_RELEASING_LATCH" 0 "DOOR_STATE_UNKNOWN" 2 "DOOR_STATE_WAIT_FOR_SHORT_DROP" ;
VAL_ 290 VCLEFT_frontHandleDebounceStatus 3 "EXTERIOR_HANDLE_STATUS_ACTIVE" 4 "EXTERIOR_HANDLE_STATUS_DISCONNECTED" 5 "EXTERIOR_HANDLE_STATUS_FAULT" 1 "EXTERIOR_HANDLE_STATUS_INDETERMINATE" 2 "EXTERIOR_HANDLE_STATUS_NOT_ACTIVE" 0 "EXTERIOR_HANDLE_STATUS_SNA" ;
VAL_ 290 VCLEFT_frontHandleRawStatus 3 "EXTERIOR_HANDLE_STATUS_ACTIVE" 4 "EXTERIOR_HANDLE_STATUS_DISCONNECTED" 5 "EXTERIOR_HANDLE_STATUS_FAULT" 1 "EXTERIOR_HANDLE_STATUS_INDETERMINATE" 2 "EXTERIOR_HANDLE_STATUS_NOT_ACTIVE" 0 "EXTERIOR_HANDLE_STATUS_SNA" ;
VAL_ 290 VCLEFT_rearDoorState 1 "DOOR_STATE_CLOSED" 4 "DOOR_STATE_OPEN_OR_AJAR" 3 "DOOR_STATE_RELEASING_LATCH" 0 "DOOR_STATE_UNKNOWN" 2 "DOOR_STATE_WAIT_FOR_SHORT_DROP" ;
VAL_ 290 VCLEFT_rearHandleDebounceStatus 3 "EXTERIOR_HANDLE_STATUS_ACTIVE" 4 "EXTERIOR_HANDLE_STATUS_DISCONNECTED" 5 "EXTERIOR_HANDLE_STATUS_FAULT" 1 "EXTERIOR_HANDLE_STATUS_INDETERMINATE" 2 "EXTERIOR_HANDLE_STATUS_NOT_ACTIVE" 0 "EXTERIOR_HANDLE_STATUS_SNA" ;
VAL_ 290 VCLEFT_rearHandleRawStatus 3 "EXTERIOR_HANDLE_STATUS_ACTIVE" 4 "EXTERIOR_HANDLE_STATUS_DISCONNECTED" 5 "EXTERIOR_HANDLE_STATUS_FAULT" 1 "EXTERIOR_HANDLE_STATUS_INDETERMINATE" 2 "EXTERIOR_HANDLE_STATUS_NOT_ACTIVE" 0 "EXTERIOR_HANDLE_STATUS_SNA" ;
VAL_ 322 VCLEFT_liftgateStatusIndex 0 "LIFTGATE_STATUS_INDEX_0" 1 "LIFTGATE_STATUS_INDEX_1" 2 "LIFTGATE_STATUS_INDEX_INVALID" ;
VAL_ 322 VCLEFT_liftgateLatchRequest 1 "LATCH_REQUEST_CINCH" 3 "LATCH_REQUEST_FORCE_RELEASE" 0 "LATCH_REQUEST_NONE" 2 "LATCH_REQUEST_RELEASE" 4 "LATCH_REQUEST_RESET" ;
VAL_ 322 VCLEFT_liftgateMvmntNotAllowedCo 4 "PLG_MVMT_NOT_ALLOWED_EXTERIOR_PRESS_AT_MAX_OPEN" 5 "PLG_MVMT_NOT_ALLOWED_LOCKED" 1 "PLG_MVMT_NOT_ALLOWED_LOW_12V" 0 "PLG_MVMT_NOT_ALLOWED_NONE" 3 "PLG_MVMT_NOT_ALLOWED_UNCALIBRATED" 2 "PLG_MVMT_NOT_ALLOWED_VEHICLE_AT_SPEED" ;
VAL_ 322 VCLEFT_liftgatePhysicalChimeRequ 0 "LIFTGATE_CHIME_REQUEST_NONE" 4 "LIFTGATE_CHIME_REQUEST_ONE_LONG" 1 "LIFTGATE_CHIME_REQUEST_ONE_SHORT" 3 "LIFTGATE_CHIME_REQUEST_THREE_SHORT" 2 "LIFTGATE_CHIME_REQUEST_TWO_SHORT" ;
VAL_ 322 VCLEFT_liftgateRequestSource 5 "PLG_REQUEST_SOURCE_CLOSE_ALL" 2 "PLG_REQUEST_SOURCE_EXTERIOR" 4 "PLG_REQUEST_SOURCE_KEY_TRUNK_BUTTON" 6 "PLG_REQUEST_SOURCE_MCU_CLOSE" 1 "PLG_REQUEST_SOURCE_MCU_SWITCH" 0 "PLG_REQUEST_SOURCE_NONE" 3 "PLG_REQUEST_SOURCE_SHUTFACE" 7 "PLG_REQUEST_SOURCE_UDS" ;
VAL_ 322 VCLEFT_liftgateState 2 "PLG_STATE_BACKOFF" 5 "PLG_STATE_CLOSED" 4 "PLG_STATE_CLOSING" 11 "PLG_STATE_END_OF_TRAVEL" 0 "PLG_STATE_INIT" 7 "PLG_STATE_LATCH_CLOSING" 12 "PLG_STATE_LATCH_ENTRY" 10 "PLG_STATE_LATCH_EXIT" 6 "PLG_STATE_LATCH_OPENING" 8 "PLG_STATE_NOT_INSTALLED" 1 "PLG_STATE_OFF" 3 "PLG_STATE_OPENING" 9 "PLG_STATE_UNKNOWN" ;
VAL_ 322 VCLEFT_liftgateStoppingCondition 11 "PLG_STOPPING_CONDITION_COUNT" 10 "PLG_STOPPING_CONDITION_LATCH_FAULT" 3 "PLG_STOPPING_CONDITION_LOW_12V" 0 "PLG_STOPPING_CONDITION_NONE" 6 "PLG_STOPPING_CONDITION_OBSTACLE_CURRENT" 2 "PLG_STOPPING_CONDITION_OBSTACLE_STALL" 7 "PLG_STOPPING_CONDITION_OBSTACLE_TRAJ_POS" 8 "PLG_STOPPING_CONDITION_OBSTACLE_TRAJ_VEL" 1 "PLG_STOPPING_CONDITION_PINCH" 4 "PLG_STOPPING_CONDITION_STATE_TIMEOUT" 9 "PLG_STOPPING_CONDITION_UNCALIBRATED" 5 "PLG_STOPPING_CONDITION_VEHICLE_AT_SPEED" ;
VAL_ 322 VCLEFT_liftgateUIChimeRequest 0 "LIFTGATE_CHIME_REQUEST_NONE" 4 "LIFTGATE_CHIME_REQUEST_ONE_LONG" 1 "LIFTGATE_CHIME_REQUEST_ONE_SHORT" 3 "LIFTGATE_CHIME_REQUEST_THREE_SHORT" 2 "LIFTGATE_CHIME_REQUEST_TWO_SHORT" ;
VAL_ 522 HVP_fcContNegativeState 3 "CONTACTOR_STATE_BLOCKED" 6 "CONTACTOR_STATE_ECONOMIZED" 1 "CONTACTOR_STATE_OPEN" 5 "CONTACTOR_STATE_OPENING" 2 "CONTACTOR_STATE_PRECHARGE" 4 "CONTACTOR_STATE_PULLED_IN" 0 "CONTACTOR_STATE_SNA" 7 "CONTACTOR_STATE_WELDED" ;
VAL_ 522 HVP_fcContPositiveState 3 "CONTACTOR_STATE_BLOCKED" 6 "CONTACTOR_STATE_ECONOMIZED" 1 "CONTACTOR_STATE_OPEN" 5 "CONTACTOR_STATE_OPENING" 2 "CONTACTOR_STATE_PRECHARGE" 4 "CONTACTOR_STATE_PULLED_IN" 0 "CONTACTOR_STATE_SNA" 7 "CONTACTOR_STATE_WELDED" ;
VAL_ 522 HVP_fcContactorSetState 3 "CONTACTOR_SET_STATE_BLOCKED" 5 "CONTACTOR_SET_STATE_CLOSED" 2 "CONTACTOR_SET_STATE_CLOSING" 9 "CONTACTOR_SET_STATE_NEGATIVE_CLOSED" 1 "CONTACTOR_SET_STATE_OPEN" 4 "CONTACTOR_SET_STATE_OPENING" 6 "CONTACTOR_SET_STATE_PARTIAL_WELD" 8 "CONTACTOR_SET_STATE_POSITIVE_CLOSED" 0 "CONTACTOR_SET_STATE_SNA" 7 "CONTACTOR_SET_STATE_WELDED" ;
VAL_ 522 HVP_fcCtrsRequestStatus 1 "REQUEST_ACTIVE" 2 "REQUEST_COMPLETED" 0 "REQUEST_NOT_ACTIVE" ;
VAL_ 522 HVP_fcLinkAllowedToEnergize 1 "FC_LINK_ENERGY_AC" 2 "FC_LINK_ENERGY_DC" 0 "FC_LINK_ENERGY_NONE" ;
VAL_ 522 HVP_hvilStatus 2 "CURRENT_SOURCE_FAULT" 3 "INTERNAL_OPEN_FAULT" 8 "NO_12V_SUPPLY" 5 "PENTHOUSE_LID_OPEN_FAULT" 1 "STATUS_OK" 0 "UNKNOWN" 6 "UNKNOWN_LOCATION_OPEN_FAULT" 7 "VEHICLE_NODE_FAULT" 4 "VEHICLE_OPEN_FAULT" 9 "VEHICLE_OR_PENTHOUSE_LID_OPEN_FAULT" ;
VAL_ 522 HVP_packContNegativeState 3 "CONTACTOR_STATE_BLOCKED" 6 "CONTACTOR_STATE_ECONOMIZED" 1 "CONTACTOR_STATE_OPEN" 5 "CONTACTOR_STATE_OPENING" 2 "CONTACTOR_STATE_PRECHARGE" 4 "CONTACTOR_STATE_PULLED_IN" 0 "CONTACTOR_STATE_SNA" 7 "CONTACTOR_STATE_WELDED" ;
VAL_ 522 HVP_packContPositiveState 3 "CONTACTOR_STATE_BLOCKED" 6 "CONTACTOR_STATE_ECONOMIZED" 1 "CONTACTOR_STATE_OPEN" 5 "CONTACTOR_STATE_OPENING" 2 "CONTACTOR_STATE_PRECHARGE" 4 "CONTACTOR_STATE_PULLED_IN" 0 "CONTACTOR_STATE_SNA" 7 "CONTACTOR_STATE_WELDED" ;
VAL_ 522 HVP_packContactorSetState 3 "CONTACTOR_SET_STATE_BLOCKED" 5 "CONTACTOR_SET_STATE_CLOSED" 2 "CONTACTOR_SET_STATE_CLOSING" 9 "CONTACTOR_SET_STATE_NEGATIVE_CLOSED" 1 "CONTACTOR_SET_STATE_OPEN" 4 "CONTACTOR_SET_STATE_OPENING" 6 "CONTACTOR_SET_STATE_PARTIAL_WELD" 8 "CONTACTOR_SET_STATE_POSITIVE_CLOSED" 0 "CONTACTOR_SET_STATE_SNA" 7 "CONTACTOR_SET_STATE_WELDED" ;
VAL_ 522 HVP_packCtrsRequestStatus 1 "REQUEST_ACTIVE" 2 "REQUEST_COMPLETED" 0 "REQUEST_NOT_ACTIVE" ;
VAL_ 516 PCS_chargeShutdownRequest 2 "EMERGENCY_SHUTDOWN_REQUESTED" 1 "GRACEFUL_SHUTDOWN_REQUESTED" 0 "NO_SHUTDOWN_REQUESTED" ;
VAL_ 516 PCS_chgMainState 9 "PCS_CHG_STATE_CLEAR_FAULTS" 6 "PCS_CHG_STATE_ENABLE" 8 "PCS_CHG_STATE_FAULTED" 1 "PCS_CHG_STATE_IDLE" 0 "PCS_CHG_STATE_INIT" 4 "PCS_CHG_STATE_QUALIFY_LINE_CONFIG" 7 "PCS_CHG_STATE_SHUTDOWN" 2 "PCS_CHG_STATE_STARTUP" 5 "PCS_CHG_STATE_SYSTEM_CONFIG" 3 "PCS_CHG_STATE_WAIT_FOR_LINE_VOLTAGE" ;
VAL_ 516 PCS_gridConfig 1 "GRID_CONFIG_SINGLE_PHASE" 0 "GRID_CONFIG_SNA" 2 "GRID_CONFIG_THREE_PHASE" 3 "GRID_CONFIG_THREE_PHASE_DELTA" ;
VAL_ 516 PCS_hvChargeStatus 1 "PCS_CHARGE_BLOCKED" 2 "PCS_CHARGE_ENABLED" 3 "PCS_CHARGE_FAULTED" 0 "PCS_CHARGE_STANDBY" ;
VAL_ 516 PCS_hwVariantType 1 "PCS_32A_SINGLE_PHASE_VARIANT" 0 "PCS_48A_SINGLE_PHASE_VARIANT" 3 "PCS_HW_VARIANT_TYPE_SNA" 2 "PCS_THREE_PHASES_VARIANT" ;
VAL_ 554 HVP_dcLinkVoltageFiltered 550 "SNA" ;
VAL_ 554 HVP_pcsControlRequest 3 "DISCHARGE" 2 "PRECHARGE" 0 "SHUTDOWN" 1 "SUPPORT" ;
VAL_ 562 BMS_fcContactorRequest 1 "SET_REQUEST_CLOSE" 4 "SET_REQUEST_CLOSE_NEGATIVE_ONLY" 5 "SET_REQUEST_CLOSE_POSITIVE_ONLY" 2 "SET_REQUEST_OPEN" 3 "SET_REQUEST_OPEN_IMMEDIATELY" 0 "SET_REQUEST_SNA" ;
VAL_ 562 BMS_fcLinkOkToEnergizeRequest 1 "FC_LINK_ENERGY_AC" 2 "FC_LINK_ENERGY_DC" 0 "FC_LINK_ENERGY_NONE" ;
VAL_ 562 BMS_internalHvilSenseV 65535 "SNA" ;
VAL_ 562 BMS_packContactorRequest 1 "SET_REQUEST_CLOSE" 4 "SET_REQUEST_CLOSE_NEGATIVE_ONLY" 5 "SET_REQUEST_CLOSE_POSITIVE_ONLY" 2 "SET_REQUEST_OPEN" 3 "SET_REQUEST_OPEN_IMMEDIATELY" 0 "SET_REQUEST_SNA" ;
VAL_ 627 UI_displayBrightnessLevel 255 "SNA" ;
VAL_ 627 UI_domeLightSwitch 2 "DOME_LIGHT_SWITCH_AUTO" 0 "DOME_LIGHT_SWITCH_OFF" 1 "DOME_LIGHT_SWITCH_ON" ;
VAL_ 627 UI_driveStateRequest 0 "DRIVE_STATE_REQ_IDLE" 1 "DRIVE_STATE_REQ_START" ;
VAL_ 627 UI_frontLeftSeatHeatReq 1 "HEATER_REQUEST_LEVEL1" 2 "HEATER_REQUEST_LEVEL2" 3 "HEATER_REQUEST_LEVEL3" 0 "HEATER_REQUEST_OFF" ;
VAL_ 627 UI_frontRightSeatHeatReq 1 "HEATER_REQUEST_LEVEL1" 2 "HEATER_REQUEST_LEVEL2" 3 "HEATER_REQUEST_LEVEL3" 0 "HEATER_REQUEST_OFF" ;
VAL_ 627 UI_lockRequest 0 "UI_LOCK_REQUEST_IDLE" 1 "UI_LOCK_REQUEST_LOCK" 4 "UI_LOCK_REQUEST_REMOTE_LOCK" 3 "UI_LOCK_REQUEST_REMOTE_UNLOCK" 7 "UI_LOCK_REQUEST_SNA" 2 "UI_LOCK_REQUEST_UNLOCK" ;
VAL_ 627 UI_mirrorFoldRequest 0 "MIRROR_FOLD_REQUEST_IDLE" 2 "MIRROR_FOLD_REQUEST_PRESENT" 1 "MIRROR_FOLD_REQUEST_RETRACT" 3 "MIRROR_FOLD_REQUEST_SNA" ;
VAL_ 627 UI_rearCenterSeatHeatReq 1 "HEATER_REQUEST_LEVEL1" 2 "HEATER_REQUEST_LEVEL2" 3 "HEATER_REQUEST_LEVEL3" 0 "HEATER_REQUEST_OFF" ;
VAL_ 627 UI_rearLeftSeatHeatReq 1 "HEATER_REQUEST_LEVEL1" 2 "HEATER_REQUEST_LEVEL2" 3 "HEATER_REQUEST_LEVEL3" 0 "HEATER_REQUEST_OFF" ;
VAL_ 627 UI_rearRightSeatHeatReq 1 "HEATER_REQUEST_LEVEL1" 2 "HEATER_REQUEST_LEVEL2" 3 "HEATER_REQUEST_LEVEL3" 0 "HEATER_REQUEST_OFF" ;
VAL_ 627 UI_remoteClosureRequest 2 "UI_REMOTE_CLOSURE_REQUEST_FRONT_TRUNK_MOVE" 0 "UI_REMOTE_CLOSURE_REQUEST_IDLE" 1 "UI_REMOTE_CLOSURE_REQUEST_REAR_TRUNK_MOVE" 3 "UI_REMOTE_CLOSURE_REQUEST_SNA" ;
VAL_ 627 UI_remoteStartRequest 0 "UI_REMOTE_START_REQUEST_IDLE" 4 "UI_REMOTE_START_REQUEST_SNA" 1 "UI_REMOTE_START_REQUEST_START" ;
VAL_ 627 UI_steeringBacklightEnabled 0 "STEERING_BACKLIGHT_DISABLED" 1 "STEERING_BACKLIGHT_ENABLED" ;
VAL_ 627 UI_steeringButtonMode 4 "STEERING_BUTTON_MODE_HEADLIGHT_LEFT" 5 "STEERING_BUTTON_MODE_HEADLIGHT_RIGHT" 2 "STEERING_BUTTON_MODE_MIRROR_LEFT" 3 "STEERING_BUTTON_MODE_MIRROR_RIGHT" 0 "STEERING_BUTTON_MODE_OFF" 1 "STEERING_BUTTON_MODE_STEERING_COLUMN_ADJ" ;
VAL_ 627 UI_wiperMode 2 "WIPER_MODE_NORMAL" 3 "WIPER_MODE_PARK" 1 "WIPER_MODE_SERVICE" 0 "WIPER_MODE_SNA" ;
VAL_ 627 UI_wiperRequest 2 "WIPER_REQUEST_AUTO" 6 "WIPER_REQUEST_FAST_CONTINUOUS" 4 "WIPER_REQUEST_FAST_INTERMITTENT" 1 "WIPER_REQUEST_OFF" 5 "WIPER_REQUEST_SLOW_CONTINUOUS" 3 "WIPER_REQUEST_SLOW_INTERMITTENT" 0 "WIPER_REQUEST_SNA" ;
VAL_ 1066 VCSEC_TPMSConnectionTypeCurrent0 0 "CONNECTIONTYPE_FAST" 1 "CONNECTIONTYPE_SLOW" 2 "CONNECTIONTYPE_UNKNOWN" ;
VAL_ 1066 VCSEC_TPMSConnectionTypeCurrent1 0 "CONNECTIONTYPE_FAST" 1 "CONNECTIONTYPE_SLOW" 2 "CONNECTIONTYPE_UNKNOWN" ;
VAL_ 1066 VCSEC_TPMSConnectionTypeCurrent2 0 "CONNECTIONTYPE_FAST" 1 "CONNECTIONTYPE_SLOW" 2 "CONNECTIONTYPE_UNKNOWN" ;
VAL_ 1066 VCSEC_TPMSConnectionTypeCurrent3 0 "CONNECTIONTYPE_FAST" 1 "CONNECTIONTYPE_SLOW" 2 "CONNECTIONTYPE_UNKNOWN" ;
VAL_ 1066 VCSEC_TPMSConnectionTypeDesired0 0 "CONNECTIONTYPE_FAST" 1 "CONNECTIONTYPE_SLOW" 2 "CONNECTIONTYPE_UNKNOWN" ;
VAL_ 1066 VCSEC_TPMSConnectionTypeDesired1 0 "CONNECTIONTYPE_FAST" 1 "CONNECTIONTYPE_SLOW" 2 "CONNECTIONTYPE_UNKNOWN" ;
VAL_ 1066 VCSEC_TPMSConnectionTypeDesired2 0 "CONNECTIONTYPE_FAST" 1 "CONNECTIONTYPE_SLOW" 2 "CONNECTIONTYPE_UNKNOWN" ;
VAL_ 1066 VCSEC_TPMSConnectionTypeDesired3 0 "CONNECTIONTYPE_FAST" 1 "CONNECTIONTYPE_SLOW" 2 "CONNECTIONTYPE_UNKNOWN" ;
VAL_ 1066 VCSEC_TPMSSensorState0 3 "SENSOR_CONNECTED" 4 "SENSOR_DISCONNECTING" 0 "SENSOR_NOT_PAIRED" 1 "SENSOR_WAIT_FOR_ADV" 2 "SENSOR_WAIT_FOR_CONN" ;
VAL_ 1066 VCSEC_TPMSSensorState1 3 "SENSOR_CONNECTED" 4 "SENSOR_DISCONNECTING" 0 "SENSOR_NOT_PAIRED" 1 "SENSOR_WAIT_FOR_ADV" 2 "SENSOR_WAIT_FOR_CONN" ;
VAL_ 1066 VCSEC_TPMSSensorState2 3 "SENSOR_CONNECTED" 4 "SENSOR_DISCONNECTING" 0 "SENSOR_NOT_PAIRED" 1 "SENSOR_WAIT_FOR_ADV" 2 "SENSOR_WAIT_FOR_CONN" ;
VAL_ 1066 VCSEC_TPMSSensorState3 3 "SENSOR_CONNECTED" 4 "SENSOR_DISCONNECTING" 0 "SENSOR_NOT_PAIRED" 1 "SENSOR_WAIT_FOR_ADV" 2 "SENSOR_WAIT_FOR_CONN" ;
VAL_ 558 PARK_sdiSensor10RawDistData 0 "BLOCKED" 1 "NEAR_DETECTION" 500 "NO_OBJECT_DETECTED" 511 "SNA" ;
VAL_ 558 PARK_sdiSensor11RawDistData 0 "BLOCKED" 1 "NEAR_DETECTION" 500 "NO_OBJECT_DETECTED" 511 "SNA" ;
VAL_ 558 PARK_sdiSensor12RawDistData 0 "BLOCKED" 1 "NEAR_DETECTION" 500 "NO_OBJECT_DETECTED" 511 "SNA" ;
VAL_ 558 PARK_sdiSensor7RawDistData 0 "BLOCKED" 1 "NEAR_DETECTION" 500 "NO_OBJECT_DETECTED" 511 "SNA" ;
VAL_ 558 PARK_sdiSensor8RawDistData 0 "BLOCKED" 1 "NEAR_DETECTION" 500 "NO_OBJECT_DETECTED" 511 "SNA" ;
VAL_ 558 PARK_sdiSensor9RawDistData 0 "BLOCKED" 1 "NEAR_DETECTION" 500 "NO_OBJECT_DETECTED" 511 "SNA" ;
VAL_ 605 CP_UHF_controlState 3 "CP_UHF_CALIBRATE" 6 "CP_UHF_CHECK_RX" 1 "CP_UHF_CONFIG" 10 "CP_UHF_FAULT" 8 "CP_UHF_HANDLE_FOUND" 2 "CP_UHF_IDLE" 0 "CP_UHF_INIT" 4 "CP_UHF_PREPARE_RX" 7 "CP_UHF_READ_RXFIFO" 5 "CP_UHF_RX" 9 "CP_UHF_SLEEP" ;
VAL_ 605 CP_chargeCablePresent 0 "CABLE_NOT_PRESENT" 1 "CABLE_PRESENT" ;
VAL_ 605 CP_chargeCableState 2 "CHARGE_CABLE_CONNECTED" 1 "CHARGE_CABLE_NOT_CONNECTED" 0 "CHARGE_CABLE_UNKNOWN_SNA" ;
VAL_ 605 CP_coldWeatherMode 1 "CP_COLD_WEATHER_LATCH_MITIGATION" 0 "CP_COLD_WEATHER_NONE" ;
VAL_ 605 CP_doorControlState 5 "CP_doorClosing" 1 "CP_doorIdle" 0 "CP_doorInit" 2 "CP_doorOpenRequested" 3 "CP_doorOpening" 6 "CP_doorSenseClosed" 4 "CP_doorSenseOpen" ;
VAL_ 605 CP_faultLineSensed 0 "FAULT_LINE_CLEARED" 1 "FAULT_LINE_SET" ;
VAL_ 605 CP_inductiveDoorState 7 "CP_INDUCTIVE_DOOR_FAULT" 0 "CP_INDUCTIVE_DOOR_INIT" 1 "CP_INDUCTIVE_DOOR_INIT_FROM_CHARGE" 2 "CP_INDUCTIVE_DOOR_INIT_FROM_DRIVE" 4 "CP_INDUCTIVE_DOOR_NOT_PRESENT" 6 "CP_INDUCTIVE_DOOR_OFF_CHARGE" 5 "CP_INDUCTIVE_DOOR_OFF_DRIVE" 3 "CP_INDUCTIVE_DOOR_PRESENT" ;
VAL_ 605 CP_inductiveSensorState 7 "CP_INDUCTIVE_SENSOR_CONFIG" 5 "CP_INDUCTIVE_SENSOR_FAULT" 0 "CP_INDUCTIVE_SENSOR_INIT" 3 "CP_INDUCTIVE_SENSOR_PAUSE" 1 "CP_INDUCTIVE_SENSOR_POLL" 6 "CP_INDUCTIVE_SENSOR_RESET" 2 "CP_INDUCTIVE_SENSOR_SHUTDOWN" 4 "CP_INDUCTIVE_SENSOR_WAIT_FOR_INIT" ;
VAL_ 605 CP_latch2ControlState 2 "CP_latchDisengageRequested" 4 "CP_latchDisengaged" 3 "CP_latchDisengaging" 5 "CP_latchEngaging" 1 "CP_latchIdle" 0 "CP_latchInit" ;
VAL_ 605 CP_latch2State 3 "CP_LATCH_BLOCKING" 1 "CP_LATCH_DISENGAGED" 2 "CP_LATCH_ENGAGED" 0 "CP_LATCH_SNA" ;
VAL_ 605 CP_latchControlState 2 "CP_latchDisengageRequested" 4 "CP_latchDisengaged" 3 "CP_latchDisengaging" 5 "CP_latchEngaging" 1 "CP_latchIdle" 0 "CP_latchInit" ;
VAL_ 605 CP_latchState 3 "CP_LATCH_BLOCKING" 1 "CP_LATCH_DISENGAGED" 2 "CP_LATCH_ENGAGED" 0 "CP_LATCH_SNA" ;
VAL_ 605 CP_ledColor 7 "CP_LEDS_AMBER" 3 "CP_LEDS_BLUE" 9 "CP_LEDS_DEBUG" 6 "CP_LEDS_FLASHING_AMBER" 10 "CP_LEDS_FLASHING_BLUE" 5 "CP_LEDS_FLASHING_GREEN" 2 "CP_LEDS_GREEN" 0 "CP_LEDS_OFF" 8 "CP_LEDS_RAVE" 1 "CP_LEDS_RED" 4 "CP_LEDS_WHITE" ;
VAL_ 605 CP_type 1 "CP_TYPE_EURO_IEC" 2 "CP_TYPE_GB" 3 "CP_TYPE_IEC_CCS" 0 "CP_TYPE_US_TESLA" ;
VAL_ 777 DAS_objectId 3 "CUTIN_VEHICLE" 0 "LEAD_VEHICLES" 1 "LEFT_VEHICLES" 2 "RIGHT_VEHICLES" 4 "ROAD_SIGN" 5 "VEHICLE_HEADINGS" ;
VAL_ 777 DAS_cutinVehDx 255 "SNA" ;
VAL_ 777 DAS_cutinVehHeading 255 "SNA" ;
VAL_ 777 DAS_cutinVehId 127 "SNA" ;
VAL_ 777 DAS_cutinVehType 4 "BICYCLE" 2 "CAR" 3 "MOTORCYCLE" 5 "PEDESTRIAN" 1 "TRUCK" 0 "UNKNOWN" ;
VAL_ 777 DAS_cutinVehVxRel 15 "SNA" ;
VAL_ 777 DAS_leadVeh2Dx 255 "SNA" ;
VAL_ 777 DAS_leadVeh2Heading 255 "SNA" ;
VAL_ 777 DAS_leadVeh2Id 0 "SNA" ;
VAL_ 777 DAS_leadVeh2Type 4 "BICYCLE" 2 "CAR" 3 "MOTORCYCLE" 5 "PEDESTRIAN" 1 "TRUCK" 0 "UNKNOWN" ;
VAL_ 777 DAS_leadVeh2VxRel 15 "SNA" ;
VAL_ 777 DAS_leadVehDx 255 "SNA" ;
VAL_ 777 DAS_leadVehHeading 255 "SNA" ;
VAL_ 777 DAS_leadVehId 127 "SNA" ;
VAL_ 777 DAS_leadVehType 4 "BICYCLE" 2 "CAR" 6 "IPSO" 3 "MOTORCYCLE" 5 "PEDESTRIAN" 1 "TRUCK" 0 "UNKNOWN" ;
VAL_ 777 DAS_leadVehVxRel 15 "SNA" ;
VAL_ 777 DAS_leftVeh2Dx 255 "SNA" ;
VAL_ 777 DAS_leftVeh2Heading 255 "SNA" ;
VAL_ 777 DAS_leftVeh2Id 0 "SNA" ;
VAL_ 777 DAS_leftVeh2Type 4 "BICYCLE" 2 "CAR" 3 "MOTORCYCLE" 5 "PEDESTRIAN" 1 "TRUCK" 0 "UNKNOWN" ;
VAL_ 777 DAS_leftVeh2VxRel 15 "SNA" ;
VAL_ 777 DAS_leftVehDx 255 "SNA" ;
VAL_ 777 DAS_leftVehHeading 255 "SNA" ;
VAL_ 777 DAS_leftVehId 127 "SNA" ;
VAL_ 777 DAS_leftVehType 4 "BICYCLE" 2 "CAR" 3 "MOTORCYCLE" 5 "PEDESTRIAN" 1 "TRUCK" 0 "UNKNOWN" ;
VAL_ 777 DAS_leftVehVxRel 15 "SNA" ;
VAL_ 777 DAS_rightVeh2Dx 255 "SNA" ;
VAL_ 777 DAS_rightVeh2Heading 255 "SNA" ;
VAL_ 777 DAS_rightVeh2Id 0 "SNA" ;
VAL_ 777 DAS_rightVeh2Type 4 "BICYCLE" 2 "CAR" 3 "MOTORCYCLE" 5 "PEDESTRIAN" 1 "TRUCK" 0 "UNKNOWN" ;
VAL_ 777 DAS_rightVeh2VxRel 15 "SNA" ;
VAL_ 777 DAS_rightVehDx 255 "SNA" ;
VAL_ 777 DAS_rightVehHeading 255 "SNA" ;
VAL_ 777 DAS_rightVehId 127 "SNA" ;
VAL_ 777 DAS_rightVehType 4 "BICYCLE" 2 "CAR" 3 "MOTORCYCLE" 5 "PEDESTRIAN" 1 "TRUCK" 0 "UNKNOWN" ;
VAL_ 777 DAS_rightVehVxRel 15 "SNA" ;
VAL_ 777 DAS_roadSignArrow 0 "CIRCLE" 1 "LEFT" 2 "RIGHT" 3 "STRAIGHT" 4 "UNKNOWN" ;
VAL_ 777 DAS_roadSignColor 3 "GREEN" 0 "NONE" 1 "RED" 4 "RED_YELLOW" 2 "YELLOW" ;
VAL_ 777 DAS_roadSignId 255 "SNA" 0 "STOP_SIGN" 1 "TRAFFIC_LIGHT" ;
VAL_ 777 DAS_roadSignOrientation 2 "HORIZONTAL_3_LIGHT" 0 "UNKNOWN" 1 "VERTICAL_3_LIGHT" ;
VAL_ 777 DAS_roadSignSource 1 "NAV" 0 "NONE" 2 "VISION" ;
VAL_ 777 DAS_roadSignStopLineDist 1023 "SNA" ;
VAL_ 929 VCFRONT_12vStatusForDrive 2 "EXIT_DRIVE_REQUESTED_12V" 0 "NOT_READY_FOR_DRIVE_12V" 1 "READY_FOR_DRIVE_12V" ;
VAL_ 929 VCFRONT_2RowCenterUnbuckled 0 "CHIME_NONE" 1 "CHIME_OCCUPIED_AND_UNBUCKLED" 2 "CHIME_SNA" ;
VAL_ 929 VCFRONT_2RowLeftUnbuckled 0 "CHIME_NONE" 1 "CHIME_OCCUPIED_AND_UNBUCKLED" 2 "CHIME_SNA" ;
VAL_ 929 VCFRONT_2RowRightUnbuckled 0 "CHIME_NONE" 1 "CHIME_OCCUPIED_AND_UNBUCKLED" 2 "CHIME_SNA" ;
VAL_ 929 VCFRONT_APGlassHeaterState 4 "HEATER_STATE_FAULT" 2 "HEATER_STATE_OFF" 3 "HEATER_STATE_OFF_UNAVAILABLE" 1 "HEATER_STATE_ON" 0 "HEATER_STATE_SNA" ;
VAL_ 929 VCFRONT_diPowerOnState 0 "DI_POWERED_OFF" 3 "DI_POWERED_ON_FOR_DRIVE" 2 "DI_POWERED_ON_FOR_STATIONARY_HEAT" 1 "DI_POWERED_ON_FOR_SUMMON" 4 "DI_POWER_GOING_DOWN" ;
VAL_ 929 VCFRONT_driverBuckleStatus 1 "BUCKLED" 0 "UNBUCKLED" ;
VAL_ 929 VCFRONT_driverDoorStatus 1 "DOOR_CLOSED" 0 "DOOR_OPEN" ;
VAL_ 929 VCFRONT_driverUnbuckled 0 "CHIME_NONE" 1 "CHIME_OCCUPIED_AND_UNBUCKLED" 2 "CHIME_SNA" ;
VAL_ 929 VCFRONT_passengerUnbuckled 0 "CHIME_NONE" 1 "CHIME_OCCUPIED_AND_UNBUCKLED" 2 "CHIME_SNA" ;
VAL_ 929 VCFRONT_pcsEFuseVoltage 1023 "SNA" ;
VAL_ 929 VCFRONT_thermalSystemType 1 "HEAT_PUMP_THERMAL_SYSTEM" 0 "LEGACY_THERMAL_SYSTEM" ;
VAL_ 994 VCLEFT_FLMapLightStatus 2 "LIGHT_FAULT" 0 "LIGHT_OFF" 1 "LIGHT_ON" 3 "LIGHT_SNA" ;
VAL_ 994 VCLEFT_FRMapLightStatus 2 "LIGHT_FAULT" 0 "LIGHT_OFF" 1 "LIGHT_ON" 3 "LIGHT_SNA" ;
VAL_ 994 VCLEFT_RLMapLightStatus 2 "LIGHT_FAULT" 0 "LIGHT_OFF" 1 "LIGHT_ON" 3 "LIGHT_SNA" ;
VAL_ 994 VCLEFT_RRMapLightStatus 2 "LIGHT_FAULT" 0 "LIGHT_OFF" 1 "LIGHT_ON" 3 "LIGHT_SNA" ;
VAL_ 994 VCLEFT_brakeLightStatus 2 "LIGHT_FAULT" 0 "LIGHT_OFF" 1 "LIGHT_ON" 3 "LIGHT_SNA" ;
VAL_ 994 VCLEFT_brakeTrailerLightStatus 2 "LIGHT_FAULT" 0 "LIGHT_OFF" 1 "LIGHT_ON" 3 "LIGHT_SNA" ;
VAL_ 994 VCLEFT_dynamicBrakeLightStatus 2 "DYNAMIC_BRAKE_LIGHT_ACTIVE_HIGH" 1 "DYNAMIC_BRAKE_LIGHT_ACTIVE_LOW" 0 "DYNAMIC_BRAKE_LIGHT_OFF" ;
VAL_ 994 VCLEFT_fogTrailerLightStatus 2 "LIGHT_FAULT" 0 "LIGHT_OFF" 1 "LIGHT_ON" 3 "LIGHT_SNA" ;
VAL_ 994 VCLEFT_frontRideHeight 128 "SNA" ;
VAL_ 994 VCLEFT_leftTurnTrailerLightStatu 2 "LIGHT_FAULT" 0 "LIGHT_OFF" 1 "LIGHT_ON" 3 "LIGHT_SNA" ;
VAL_ 994 VCLEFT_rearRideHeight 128 "SNA" ;
VAL_ 994 VCLEFT_reverseTrailerLightStatus 2 "LIGHT_FAULT" 0 "LIGHT_OFF" 1 "LIGHT_ON" 3 "LIGHT_SNA" ;
VAL_ 994 VCLEFT_rightTrnTrailerLightStatu 2 "LIGHT_FAULT" 0 "LIGHT_OFF" 1 "LIGHT_ON" 3 "LIGHT_SNA" ;
VAL_ 994 VCLEFT_tailLightStatus 2 "LIGHT_FAULT" 0 "LIGHT_OFF" 1 "LIGHT_ON" 3 "LIGHT_SNA" ;
VAL_ 994 VCLEFT_tailTrailerLightStatus 2 "LIGHT_FAULT" 0 "LIGHT_OFF" 1 "LIGHT_ON" 3 "LIGHT_SNA" ;
VAL_ 994 VCLEFT_trailerDetected 2 "TRAILER_LIGHT_DETECTION_DETECTED" 1 "TRAILER_LIGHT_DETECTION_FAULT" 3 "TRAILER_LIGHT_DETECTION_NOT_DETECTED" 0 "TRAILER_LIGHT_DETECTION_SNA" ;
VAL_ 994 VCLEFT_turnSignalStatus 2 "LIGHT_FAULT" 0 "LIGHT_OFF" 1 "LIGHT_ON" 3 "LIGHT_SNA" ;
VAL_ 1001 DAS_hazardLightRequest 0 "DAS_REQUEST_HAZARDS_OFF" 1 "DAS_REQUEST_HAZARDS_ON" 3 "DAS_REQUEST_HAZARDS_SNA" 2 "DAS_REQUEST_HAZARDS_UNUSED" ;
VAL_ 1001 DAS_headlightRequest 3 "DAS_HEADLIGHT_REQUEST_INVALID" 0 "DAS_HEADLIGHT_REQUEST_OFF" 1 "DAS_HEADLIGHT_REQUEST_ON" ;
VAL_ 1001 DAS_heaterRequest 1 "DAS_HEATER_OFF" 2 "DAS_HEATER_ON" 0 "DAS_HEATER_SNA" ;
VAL_ 1001 DAS_highLowBeamDecision 1 "DAS_HIGH_BEAM_OFF" 2 "DAS_HIGH_BEAM_ON" 3 "DAS_HIGH_BEAM_SNA" 0 "DAS_HIGH_BEAM_UNDECIDED" ;
VAL_ 1001 DAS_highLowBeamOffReason 3 "HIGH_BEAM_OFF_REASON_AMBIENT_LIGHT" 4 "HIGH_BEAM_OFF_REASON_HEAD_LIGHT" 2 "HIGH_BEAM_OFF_REASON_MOVING_RADAR_TARGET" 1 "HIGH_BEAM_OFF_REASON_MOVING_VISION_TARGET" 5 "HIGH_BEAM_OFF_REASON_SNA" 0 "HIGH_BEAM_ON" ;
VAL_ 1001 DAS_turnIndicatorRequest 3 "DAS_TURN_INDICATOR_CANCEL" 4 "DAS_TURN_INDICATOR_DEFER" 1 "DAS_TURN_INDICATOR_LEFT" 0 "DAS_TURN_INDICATOR_NONE" 2 "DAS_TURN_INDICATOR_RIGHT" ;
VAL_ 1001 DAS_turnIndicatorRequestReason 8 "DAS_ACTIVE_COMMANDED_LANE_CHANGE" 3 "DAS_ACTIVE_FORK" 9 "DAS_ACTIVE_INTERSECTION" 6 "DAS_ACTIVE_MERGE" 1 "DAS_ACTIVE_NAV_LANE_CHANGE" 2 "DAS_ACTIVE_SPEED_LANE_CHANGE" 11 "DAS_ACTIVE_SUMMMON" 5 "DAS_CANCEL_FORK" 10 "DAS_CANCEL_INTERSECTION" 4 "DAS_CANCEL_LANE_CHANGE" 7 "DAS_CANCEL_MERGE" 12 "DAS_CANCEL_SUMMMON" 0 "DAS_NONE" ;
VAL_ 1001 DAS_wiperSpeed 1 "DAS_WIPER_SPEED_1" 10 "DAS_WIPER_SPEED_10" 11 "DAS_WIPER_SPEED_11" 12 "DAS_WIPER_SPEED_12" 13 "DAS_WIPER_SPEED_13" 14 "DAS_WIPER_SPEED_14" 2 "DAS_WIPER_SPEED_2" 3 "DAS_WIPER_SPEED_3" 4 "DAS_WIPER_SPEED_4" 5 "DAS_WIPER_SPEED_5" 6 "DAS_WIPER_SPEED_6" 7 "DAS_WIPER_SPEED_7" 8 "DAS_WIPER_SPEED_8" 9 "DAS_WIPER_SPEED_9" 15 "DAS_WIPER_SPEED_INVALID" 0 "DAS_WIPER_SPEED_OFF" ;
VAL_ 1001 DAS_mirrorFoldRequest 0 "NONE" 1 "FOLD" 2 "UNFOLD" 3 "SNA" ;
VAL_ 1013 VCFRONT_DRLLeftStatus 2 "LIGHT_FAULT" 0 "LIGHT_OFF" 1 "LIGHT_ON" 3 "LIGHT_SNA" ;
VAL_ 1013 VCFRONT_DRLRightStatus 2 "LIGHT_FAULT" 0 "LIGHT_OFF" 1 "LIGHT_ON" 3 "LIGHT_SNA" ;
VAL_ 1013 VCFRONT_ambientLightingBrightnes 255 "SNA" ;
VAL_ 1013 VCFRONT_fogLeftStatus 2 "LIGHT_FAULT" 0 "LIGHT_OFF" 1 "LIGHT_ON" 3 "LIGHT_SNA" ;
VAL_ 1013 VCFRONT_fogRightStatus 2 "LIGHT_FAULT" 0 "LIGHT_OFF" 1 "LIGHT_ON" 3 "LIGHT_SNA" ;
VAL_ 1013 VCFRONT_hazardLightRequest 1 "HAZARD_REQUEST_BUTTON" 6 "HAZARD_REQUEST_CAR_ALARM" 5 "HAZARD_REQUEST_CRASH" 7 "HAZARD_REQUEST_DAS" 2 "HAZARD_REQUEST_LOCK" 4 "HAZARD_REQUEST_MISLOCK" 0 "HAZARD_REQUEST_NONE" 8 "HAZARD_REQUEST_UDS" 3 "HAZARD_REQUEST_UNLOCK" ;
VAL_ 1013 VCFRONT_highBeamLeftStatus 2 "LIGHT_FAULT" 0 "LIGHT_OFF" 1 "LIGHT_ON" 3 "LIGHT_SNA" ;
VAL_ 1013 VCFRONT_highBeamRightStatus 2 "LIGHT_FAULT" 0 "LIGHT_OFF" 1 "LIGHT_ON" 3 "LIGHT_SNA" ;
VAL_ 1013 VCFRONT_indicatorLeftRequest 2 "TURN_SIGNAL_ACTIVE_HIGH" 1 "TURN_SIGNAL_ACTIVE_LOW" 0 "TURN_SIGNAL_OFF" ;
VAL_ 1013 VCFRONT_indicatorRightRequest 2 "TURN_SIGNAL_ACTIVE_HIGH" 1 "TURN_SIGNAL_ACTIVE_LOW" 0 "TURN_SIGNAL_OFF" ;
VAL_ 1013 VCFRONT_lowBeamLeftStatus 2 "LIGHT_FAULT" 0 "LIGHT_OFF" 1 "LIGHT_ON" 3 "LIGHT_SNA" ;
VAL_ 1013 VCFRONT_lowBeamRightStatus 2 "LIGHT_FAULT" 0 "LIGHT_OFF" 1 "LIGHT_ON" 3 "LIGHT_SNA" ;
VAL_ 1013 VCFRONT_parkLeftStatus 2 "LIGHT_FAULT" 0 "LIGHT_OFF" 1 "LIGHT_ON" 3 "LIGHT_SNA" ;
VAL_ 1013 VCFRONT_parkRightStatus 2 "LIGHT_FAULT" 0 "LIGHT_OFF" 1 "LIGHT_ON" 3 "LIGHT_SNA" ;
VAL_ 1013 VCFRONT_sideMarkersStatus 2 "LIGHT_FAULT" 0 "LIGHT_OFF" 1 "LIGHT_ON" 3 "LIGHT_SNA" ;
VAL_ 1013 VCFRONT_sideRepeaterLeftStatus 2 "LIGHT_FAULT" 0 "LIGHT_OFF" 1 "LIGHT_ON" 3 "LIGHT_SNA" ;
VAL_ 1013 VCFRONT_sideRepeaterRightStatus 2 "LIGHT_FAULT" 0 "LIGHT_OFF" 1 "LIGHT_ON" 3 "LIGHT_SNA" ;
VAL_ 1013 VCFRONT_simLatchingStalk 0 "SIMULATED_LATCHING_STALK_IDLE" 1 "SIMULATED_LATCHING_STALK_LEFT" 2 "SIMULATED_LATCHING_STALK_RIGHT" 3 "SIMULATED_LATCHING_STALK_SNA" ;
VAL_ 1013 VCFRONT_switchLightingBrightness 255 "SNA" ;
VAL_ 1013 VCFRONT_turnSignalLeftStatus 2 "LIGHT_FAULT" 0 "LIGHT_OFF" 1 "LIGHT_ON" 3 "LIGHT_SNA" ;
VAL_ 1013 VCFRONT_turnSignalRightStatus 2 "LIGHT_FAULT" 0 "LIGHT_OFF" 1 "LIGHT_ON" 3 "LIGHT_SNA" ;
VAL_ 615 DI_massConfidence 1 "MASS_CONFIDED" 0 "MASS_NOT_CONFIDED" ;
VAL_ 615 DI_relativeTireTreadDepth 32 "SNA" ;
VAL_ 615 DI_tireFitment 3 "FITMENT_SNA" 0 "FITMENT_SQUARE" 1 "FITMENT_STAGGERED" ;
VAL_ 615 DI_trailerDetected 1 "TRAILER_DETECTED" 0 "TRAILER_NOT_DETECTED" ;
VAL_ 642 VCLEFT_blowerIndex 0 "HVAC_FEEDBACK_SIGNALS" 1 "HVAC_VARS" ;
VAL_ 642 VCLEFT_hvacBlowerCBCCtrlState 4 "COUNT" 0 "ERROR" 1 "IDLE" 2 "OFFLINE" 3 "ONLINE" ;
VAL_ 642 VCLEFT_hvacBlowerCBCEstState 14 "COUNT" 0 "ERROR" 1 "IDLE" 5 "IDRATED" 10 "INDUCTANCE_EST" 9 "LOCKROTOR" 12 "MOTOR_IDENTIFIED" 13 "ONLINE" 8 "RAMPDOWN" 4 "RAMPUP" 7 "RATEDFLUX" 6 "RATEDFLUX_OL" 11 "ROTOR_RESISTANCE" 2 "ROVERL" 3 "RS" ;
VAL_ 642 VCLEFT_hvacBlowerFETTemp 127 "SNA" ;
VAL_ 642 VCLEFT_hvacBlowerIPhase0 255 "SNA" ;
VAL_ 642 VCLEFT_hvacBlowerIPhase1 255 "SNA" ;
VAL_ 642 VCLEFT_hvacBlowerIPhase2 255 "SNA" ;
VAL_ 642 VCLEFT_hvacBlowerITerm 127 "SNA" ;
VAL_ 642 VCLEFT_hvacBlowerOutputDuty 127 "SNA" ;
VAL_ 642 VCLEFT_hvacBlowerRPMTarget 1023 "SNA" ;
VAL_ 642 VCLEFT_hvacBlowerRs 255 "SNA" ;
VAL_ 642 VCLEFT_hvacBlowerTorque 1023 "SNA" ;
VAL_ 642 VCLEFT_hvacBlower_IO_CBC_Status 0 "IDLE" 1 "RX" ;
VAL_ 755 UI_hvacReqACDisable 0 "AUTO" 1 "OFF" 2 "ON" ;
VAL_ 755 UI_hvacReqAirDistributionMode 0 "AUTO" 4 "MANUAL_DEFROST" 5 "MANUAL_DEFROST_FLOOR" 6 "MANUAL_DEFROST_PANEL" 7 "MANUAL_DEFROST_PANEL_FLOOR" 1 "MANUAL_FLOOR" 2 "MANUAL_PANEL" 3 "MANUAL_PANEL_FLOOR" ;
VAL_ 755 UI_hvacReqBlowerSegment 1 "1" 10 "10" 2 "2" 3 "3" 4 "4" 5 "5" 6 "6" 7 "7" 8 "8" 9 "9" 11 "AUTO" 0 "OFF" ;
VAL_ 755 UI_hvacReqKeepClimateOn 2 "KEEP_CLIMATE_ON_REQ_DOG" 0 "KEEP_CLIMATE_ON_REQ_OFF" 1 "KEEP_CLIMATE_ON_REQ_ON" 3 "KEEP_CLIMATE_ON_REQ_PARTY" ;
VAL_ 755 UI_hvacReqManualDefogState 1 "DEFOG" 2 "DEFROST" 0 "NONE" ;
VAL_ 755 UI_hvacReqRecirc 0 "AUTO" 2 "FRESH" 1 "RECIRC" ;
VAL_ 755 UI_hvacReqSecondRowState 0 "AUTO" 4 "HIGH" 2 "LOW" 3 "MED" 1 "OFF" ;
VAL_ 755 UI_hvacReqTempSetpointLeft 26 "HI" 0 "LO" ;
VAL_ 755 UI_hvacReqTempSetpointRight 26 "HI" 0 "LO" ;
VAL_ 755 UI_hvacReqUserPowerState 0 "OFF" 1 "ON" 4 "OVERHEAT_PROTECT" 3 "OVERHEAT_PROTECT_FANONLY" 2 "PRECONDITION" ;
VAL_ 787 UI_trackCmpOverclock 0 "TRACK_MODE_CMP_OVERCLOCK_OFF" 1 "TRACK_MODE_CMP_OVERCLOCK_ON" ;
VAL_ 787 UI_trackModeRequest 0 "TRACK_MODE_REQUEST_IDLE" 2 "TRACK_MODE_REQUEST_OFF" 1 "TRACK_MODE_REQUEST_ON" ;
VAL_ 787 UI_trackPostCooling 0 "TRACK_MODE_POST_COOLING_OFF" 1 "TRACK_MODE_POST_COOLING_ON" ;
VAL_ 821 DIR_infoIndex 13 "DI_INFO_APP_CRC" 17 "DI_INFO_APP_GITHASH" 15 "DI_INFO_BOOTLOADER_CRC" 18 "DI_INFO_BOOTLOADER_GITHASH" 14 "DI_INFO_BOOTLOADER_SVN" 10 "DI_INFO_BUILD_HWID_COMPONENTID" 0 "DI_INFO_DEPRECATED_0" 1 "DI_INFO_DEPRECATED_1" 2 "DI_INFO_DEPRECATED_2" 3 "DI_INFO_DEPRECATED_3" 4 "DI_INFO_DEPRECATED_4" 5 "DI_INFO_DEPRECATED_5" 6 "DI_INFO_DEPRECATED_6" 7 "DI_INFO_DEPRECATED_7" 8 "DI_INFO_DEPRECATED_8" 9 "DI_INFO_DEPRECATED_9" 255 "DI_INFO_END" 11 "DI_INFO_PCBAID_ASSYID_USAGEID" 16 "DI_INFO_SUBCOMPONENT" 23 "DI_INFO_SUBCOMPONENT2" 31 "DI_INFO_SUBCOMPONENT_GITHASH" 20 "DI_INFO_UDS_PROTOCOL_BOOTCRC" 19 "DI_INFO_VERSION_DEPRECATED" ;
VAL_ 821 DIR_FPGA_version 254 "FPGA_VERSION_LOCAL_BUILD" 255 "FPGA_VERSION_SNA" ;
VAL_ 821 DIR_buildType 2 "INFO_LOCAL_BUILD" 4 "INFO_MFG_BUILD" 1 "INFO_PLATFORM_BUILD" 3 "INFO_TRACEABLE_CI_BUILD" 0 "INFO_UNKNOWN_BUILD" ;
VAL_ 821 DIR_hardwareId 252 "CONFIGURABLE_HWID_PLACEHOLDER" ;
VAL_ 821 DIR_oilPumpBuildType 2 "INFO_LOCAL_BUILD" 4 "INFO_MFG_BUILD" 1 "INFO_PLATFORM_BUILD" 3 "INFO_TRACEABLE_CI_BUILD" 0 "INFO_UNKNOWN_BUILD" ;
VAL_ 899 VCRIGHT_estimatedThsSolarLoad 1023 "SNA" ;
VAL_ 899 VCRIGHT_estimatedVehicleSituatio 1 "VEHICLE_SITUATION_INDOOR" 2 "VEHICLE_SITUATION_OUTDOOR" 0 "VEHICLE_SITUATION_UNKNOWN" ;
VAL_ 899 VCRIGHT_thsHumidity 255 "SNA" ;
VAL_ 899 VCRIGHT_thsSolarLoadInfrared 1023 "SNA" ;
VAL_ 899 VCRIGHT_thsSolarLoadVisible 1023 "SNA" ;
VAL_ 899 VCRIGHT_thsTemperature 128 "SNA" ;
VAL_ 947 UI_autopilotPowerStateRequest 0 "AUTOPILOT_NOMINAL" 1 "AUTOPILOT_SENTRY" 2 "AUTOPILOT_SUSPEND" ;
VAL_ 947 UI_lightSwitch 0 "LIGHT_SWITCH_AUTO" 3 "LIGHT_SWITCH_OFF" 1 "LIGHT_SWITCH_ON" 2 "LIGHT_SWITCH_PARKING" 4 "LIGHT_SWITCH_SNA" ;
VAL_ 947 UI_shorted12VCellTestMode 2 "SHORTED_CELL_TEST_MODE_ACTIVE" 0 "SHORTED_CELL_TEST_MODE_DISABLED" 1 "SHORTED_CELL_TEST_MODE_SHADOW" ;
VAL_ 947 UI_summonState 3 "ACTIVE" 1 "IDLE" 2 "PRE_PRIMED" 0 "SNA" ;
VAL_ 947 UI_windowRequest 3 "WINDOW_REQUEST_GOTO_CLOSED" 4 "WINDOW_REQUEST_GOTO_OPEN" 1 "WINDOW_REQUEST_GOTO_PERCENT" 2 "WINDOW_REQUEST_GOTO_VENT" 0 "WINDOW_REQUEST_IDLE" ;
VAL_ 963 VCRIGHT_frontBuckleSwitch 3 "SWITCH_FAULT" 1 "SWITCH_OFF" 2 "SWITCH_ON" 0 "SWITCH_SNA" ;
VAL_ 963 VCRIGHT_frontOccupancySwitch 3 "SWITCH_FAULT" 1 "SWITCH_OFF" 2 "SWITCH_ON" 0 "SWITCH_SNA" ;
VAL_ 963 VCRIGHT_frontSeatBackrestBack 3 "SWITCH_FAULT" 1 "SWITCH_OFF" 2 "SWITCH_ON" 0 "SWITCH_SNA" ;
VAL_ 963 VCRIGHT_frontSeatBackrestForward 3 "SWITCH_FAULT" 1 "SWITCH_OFF" 2 "SWITCH_ON" 0 "SWITCH_SNA" ;
VAL_ 963 VCRIGHT_frontSeatLiftDown 3 "SWITCH_FAULT" 1 "SWITCH_OFF" 2 "SWITCH_ON" 0 "SWITCH_SNA" ;
VAL_ 963 VCRIGHT_frontSeatLiftUp 3 "SWITCH_FAULT" 1 "SWITCH_OFF" 2 "SWITCH_ON" 0 "SWITCH_SNA" ;
VAL_ 963 VCRIGHT_frontSeatLumbarDown 3 "SWITCH_FAULT" 1 "SWITCH_OFF" 2 "SWITCH_ON" 0 "SWITCH_SNA" ;
VAL_ 963 VCRIGHT_frontSeatLumbarIn 3 "SWITCH_FAULT" 1 "SWITCH_OFF" 2 "SWITCH_ON" 0 "SWITCH_SNA" ;
VAL_ 963 VCRIGHT_frontSeatLumbarOut 3 "SWITCH_FAULT" 1 "SWITCH_OFF" 2 "SWITCH_ON" 0 "SWITCH_SNA" ;
VAL_ 963 VCRIGHT_frontSeatLumbarUp 3 "SWITCH_FAULT" 1 "SWITCH_OFF" 2 "SWITCH_ON" 0 "SWITCH_SNA" ;
VAL_ 963 VCRIGHT_frontSeatTiltDown 3 "SWITCH_FAULT" 1 "SWITCH_OFF" 2 "SWITCH_ON" 0 "SWITCH_SNA" ;
VAL_ 963 VCRIGHT_frontSeatTiltUp 3 "SWITCH_FAULT" 1 "SWITCH_OFF" 2 "SWITCH_ON" 0 "SWITCH_SNA" ;
VAL_ 963 VCRIGHT_frontSeatTrackBack 3 "SWITCH_FAULT" 1 "SWITCH_OFF" 2 "SWITCH_ON" 0 "SWITCH_SNA" ;
VAL_ 963 VCRIGHT_frontSeatTrackForward 3 "SWITCH_FAULT" 1 "SWITCH_OFF" 2 "SWITCH_ON" 0 "SWITCH_SNA" ;
VAL_ 963 VCRIGHT_rearCenterBuckleSwitch 3 "SWITCH_FAULT" 1 "SWITCH_OFF" 2 "SWITCH_ON" 0 "SWITCH_SNA" ;
VAL_ 963 VCRIGHT_rearRightBuckleSwitch 3 "SWITCH_FAULT" 1 "SWITCH_OFF" 2 "SWITCH_ON" 0 "SWITCH_SNA" ;
VAL_ 995 VCRIGHT_brakeLightStatus 2 "LIGHT_FAULT" 0 "LIGHT_OFF" 1 "LIGHT_ON" 3 "LIGHT_SNA" ;
VAL_ 995 VCRIGHT_interiorTrunkLightStatus 2 "LIGHT_FAULT" 0 "LIGHT_OFF" 1 "LIGHT_ON" 3 "LIGHT_SNA" ;
VAL_ 995 VCRIGHT_rearFogLightStatus 2 "LIGHT_FAULT" 0 "LIGHT_OFF" 1 "LIGHT_ON" 3 "LIGHT_SNA" ;
VAL_ 995 VCRIGHT_reverseLightStatus 2 "LIGHT_FAULT" 0 "LIGHT_OFF" 1 "LIGHT_ON" 3 "LIGHT_SNA" ;
VAL_ 995 VCRIGHT_tailLightStatus 2 "LIGHT_FAULT" 0 "LIGHT_OFF" 1 "LIGHT_ON" 3 "LIGHT_SNA" ;
VAL_ 995 VCRIGHT_turnSignalStatus 2 "LIGHT_FAULT" 0 "LIGHT_OFF" 1 "LIGHT_ON" 3 "LIGHT_SNA" ;
VAL_ 1622 DIF_infoIndex 13 "DI_INFO_APP_CRC" 17 "DI_INFO_APP_GITHASH" 15 "DI_INFO_BOOTLOADER_CRC" 18 "DI_INFO_BOOTLOADER_GITHASH" 14 "DI_INFO_BOOTLOADER_SVN" 10 "DI_INFO_BUILD_HWID_COMPONENTID" 0 "DI_INFO_DEPRECATED_0" 1 "DI_INFO_DEPRECATED_1" 2 "DI_INFO_DEPRECATED_2" 3 "DI_INFO_DEPRECATED_3" 4 "DI_INFO_DEPRECATED_4" 5 "DI_INFO_DEPRECATED_5" 6 "DI_INFO_DEPRECATED_6" 7 "DI_INFO_DEPRECATED_7" 8 "DI_INFO_DEPRECATED_8" 9 "DI_INFO_DEPRECATED_9" 255 "DI_INFO_END" 11 "DI_INFO_PCBAID_ASSYID_USAGEID" 16 "DI_INFO_SUBCOMPONENT" 23 "DI_INFO_SUBCOMPONENT2" 31 "DI_INFO_SUBCOMPONENT_GITHASH" 20 "DI_INFO_UDS_PROTOCOL_BOOTCRC" 19 "DI_INFO_VERSION_DEPRECATED" ;
VAL_ 1622 DIF_FPGA_version 254 "FPGA_VERSION_LOCAL_BUILD" 255 "FPGA_VERSION_SNA" ;
VAL_ 1622 DIF_buildType 2 "INFO_LOCAL_BUILD" 4 "INFO_MFG_BUILD" 1 "INFO_PLATFORM_BUILD" 3 "INFO_TRACEABLE_CI_BUILD" 0 "INFO_UNKNOWN_BUILD" ;
VAL_ 1622 DIF_hardwareId 252 "CONFIGURABLE_HWID_PLACEHOLDER" ;
VAL_ 1622 DIF_oilPumpBuildType 2 "INFO_LOCAL_BUILD" 4 "INFO_MFG_BUILD" 1 "INFO_PLATFORM_BUILD" 3 "INFO_TRACEABLE_CI_BUILD" 0 "INFO_UNKNOWN_BUILD" ;
VAL_ 768 BMS_infoIndex 13 "INFO_APP_CRC" 17 "INFO_APP_GITHASH" 15 "INFO_BOOTLOADER_CRC" 18 "INFO_BOOTLOADER_GITHASH" 14 "INFO_BOOTLOADER_SVN" 10 "INFO_BUILD_HWID_COMPONENTID" 0 "INFO_DEPRECATED_0" 1 "INFO_DEPRECATED_1" 2 "INFO_DEPRECATED_2" 3 "INFO_DEPRECATED_3" 4 "INFO_DEPRECATED_4" 5 "INFO_DEPRECATED_5" 6 "INFO_DEPRECATED_6" 7 "INFO_DEPRECATED_7" 8 "INFO_DEPRECATED_8" 9 "INFO_DEPRECATED_9" 255 "INFO_END" 27 "INFO_PACKAGE_PN_15_20" 25 "INFO_PACKAGE_PN_1_7" 26 "INFO_PACKAGE_PN_8_14" 29 "INFO_PACKAGE_SN_1_7" 30 "INFO_PACKAGE_SN_8_14" 11 "INFO_PCBAID_ASSYID_USAGEID" 16 "INFO_SUBCOMPONENT" 31 "INFO_SUBCOMPONENT_GITHASH" 20 "INFO_UDS_PROTOCOL_BOOTCRC" 22 "INFO_VARIANTCRC" 19 "INFO_VERSION_DEPRECATED" ;
VAL_ 768 BMS_buildType 2 "INFO_LOCAL_BUILD" 4 "INFO_MFG_BUILD" 1 "INFO_PLATFORM_BUILD" 3 "INFO_TRACEABLE_CI_BUILD" 0 "INFO_UNKNOWN_BUILD" ;
VAL_ 530 BMS_chgPowerAvailable 2047 "SNA" ;
VAL_ 530 BMS_contactorState 6 "BMS_CTRSET_BLOCKED" 4 "BMS_CTRSET_CLOSED" 3 "BMS_CTRSET_CLOSING" 1 "BMS_CTRSET_OPEN" 2 "BMS_CTRSET_OPENING" 0 "BMS_CTRSET_SNA" 5 "BMS_CTRSET_WELDED" ;
VAL_ 530 BMS_diLimpRequest 0 "LIMP_REQUEST_NONE" 1 "LIMP_REQUEST_WELDED" ;
VAL_ 530 BMS_ecuLogUploadRequest 1 "REQUEST_PRIORITY_1" 2 "REQUEST_PRIORITY_2" 3 "REQUEST_PRIORITY_3" 0 "REQUEST_PRIORITY_NONE" ;
VAL_ 530 BMS_hvState 1 "HV_COMING_UP" 0 "HV_DOWN" 2 "HV_GOING_DOWN" 6 "HV_UP" 4 "HV_UP_FOR_CHARGE" 5 "HV_UP_FOR_DC_CHARGE" 3 "HV_UP_FOR_DRIVE" ;
VAL_ 530 BMS_isolationResistance 1023 "SNA" ;
VAL_ 530 BMS_smStateRequest 3 "BMS_CHARGE" 5 "BMS_CLEAR_FAULT" 10 "BMS_DIAG" 1 "BMS_DRIVE" 6 "BMS_FAULT" 4 "BMS_FEIM" 9 "BMS_SNA" 0 "BMS_STANDBY" 2 "BMS_SUPPORT" 8 "BMS_TEST" 7 "BMS_WELD" ;
VAL_ 530 BMS_state 3 "BMS_CHARGE" 5 "BMS_CLEAR_FAULT" 10 "BMS_DIAG" 1 "BMS_DRIVE" 6 "BMS_FAULT" 4 "BMS_FEIM" 9 "BMS_SNA" 0 "BMS_STANDBY" 2 "BMS_SUPPORT" 8 "BMS_TEST" 7 "BMS_WELD" ;
VAL_ 530 BMS_uiChargeStatus 2 "BMS_ABOUT_TO_CHARGE" 4 "BMS_CHARGE_COMPLETE" 5 "BMS_CHARGE_STOPPED" 3 "BMS_CHARGING" 0 "BMS_DISCONNECTED" 1 "BMS_NO_POWER" ;
VAL_ 796 CC_currentLimit 255 "SNA" ;
VAL_ 796 CC_gridGrounding 1 "CC_GRID_GROUNDING_IT_SplitPhase" 2 "CC_GRID_GROUNDING_SNA" 0 "CC_GRID_GROUNDING_TN_TT" ;
VAL_ 796 CC_line1Voltage 511 "SNA" ;
VAL_ 796 CC_line2Voltage 511 "SNA" ;
VAL_ 796 CC_line3Voltage 511 "SNA" ;
VAL_ 796 CC_numPhases 0 "SNA" ;
VAL_ 796 CC_pilotState 2 "CC_PILOT_STATE_FAULTED" 1 "CC_PILOT_STATE_IDLE" 0 "CC_PILOT_STATE_READY" 3 "CC_PILOT_STATE_SNA" ;
VAL_ 573 CP_chargeShutdownRequest 2 "EMERGENCY_SHUTDOWN_REQUESTED" 1 "GRACEFUL_SHUTDOWN_REQUESTED" 0 "NO_SHUTDOWN_REQUESTED" ;
VAL_ 573 CP_hvChargeStatus 1 "CP_CHARGE_CONNECTED" 5 "CP_CHARGE_ENABLED" 6 "CP_CHARGE_FAULTED" 0 "CP_CHARGE_INACTIVE" 2 "CP_CHARGE_STANDBY" 4 "CP_EVSE_TEST_PASSED" 3 "CP_EXT_EVSE_TEST_ACTIVE" ;
VAL_ 317 CP_chargeShutdownRequest 2 "EMERGENCY_SHUTDOWN_REQUESTED" 1 "GRACEFUL_SHUTDOWN_REQUESTED" 0 "NO_SHUTDOWN_REQUESTED" ;
VAL_ 317 CP_evseChargeType 2 "AC_CHARGER_PRESENT" 1 "DC_CHARGER_PRESENT" 0 "NO_CHARGER_PRESENT" ;
VAL_ 317 CP_hvChargeStatus 1 "CP_CHARGE_CONNECTED" 5 "CP_CHARGE_ENABLED" 6 "CP_CHARGE_FAULTED" 0 "CP_CHARGE_INACTIVE" 2 "CP_CHARGE_STANDBY" 4 "CP_EVSE_TEST_PASSED" 3 "CP_EXT_EVSE_TEST_ACTIVE" ;
VAL_ 1085 CP_chargeShutdownRequest_log 2 "EMERGENCY_SHUTDOWN_REQUESTED" 1 "GRACEFUL_SHUTDOWN_REQUESTED" 0 "NO_SHUTDOWN_REQUESTED" ;
VAL_ 1085 CP_evseChargeType_log 2 "AC_CHARGER_PRESENT" 1 "DC_CHARGER_PRESENT" 0 "NO_CHARGER_PRESENT" ;
VAL_ 1085 CP_hvChargeStatus_log 1 "CP_CHARGE_CONNECTED" 5 "CP_CHARGE_ENABLED" 6 "CP_CHARGE_FAULTED" 0 "CP_CHARGE_INACTIVE" 2 "CP_CHARGE_STANDBY" 4 "CP_EVSE_TEST_PASSED" 3 "CP_EXT_EVSE_TEST_ACTIVE" ;
VAL_ 541 CP_acChargeState 1 "AC_CHARGE_CONNECTED_CHARGE_BLOCKED" 3 "AC_CHARGE_ENABLED" 6 "AC_CHARGE_FAULT" 0 "AC_CHARGE_INACTIVE" 4 "AC_CHARGE_ONBOARD_CHARGER_SHUTDOWN" 2 "AC_CHARGE_STANDBY" 5 "AC_CHARGE_VEH_SHUTDOWN" ;
VAL_ 541 CP_cableType 2 "CHG_CABLE_TYPE_GB_AC" 3 "CHG_CABLE_TYPE_GB_DC" 0 "CHG_CABLE_TYPE_IEC" 1 "CHG_CABLE_TYPE_SAE" 4 "CHG_CABLE_TYPE_SNA" ;
VAL_ 541 CP_evseChargeType_UI 2 "AC_CHARGER_PRESENT" 1 "DC_CHARGER_PRESENT" 0 "NO_CHARGER_PRESENT" ;
VAL_ 541 CP_gbState 10 "GBDC_CHARGE_DISABLING" 5 "GBDC_CHARGE_PARAM_CONFIG" 8 "GBDC_CHARGING" 2 "GBDC_COMMS_RECEIVED" 11 "GBDC_END_OF_CHARGE" 12 "GBDC_ERROR_HANDLING" 14 "GBDC_FAULTED" 3 "GBDC_HANDSHAKING_EXT_ISO" 0 "GBDC_INACTIVE" 7 "GBDC_READY_TO_CHARGE" 4 "GBDC_RECOGNITION" 13 "GBDC_RETRY_CHARGE" 9 "GBDC_STOP_CHARGE_REQUESTED" 15 "GBDC_TESTER_PRESENT" 6 "GBDC_VEH_PACK_PRECHARGE" 1 "GBDC_WAIT_FOR_COMMS" ;
VAL_ 541 CP_gbdcFailureReason 1 "GBDC_ATTEMPTS_EXPIRED" 3 "GBDC_CRITICAL_FAILURE" 0 "GBDC_FAILURE_NONE" 2 "GBDC_SHUTDOWN_FAILURE" ;
VAL_ 541 CP_gbdcStopChargeReason 3 "GBDC_COMMS_TIMEOUT" 5 "GBDC_EVSE_CRITICAL_FAULT" 4 "GBDC_EVSE_FAULT" 2 "GBDC_EVSE_REQUESTED" 6 "GBDC_LIVE_DISCONNECT" 0 "GBDC_STOP_REASON_NONE" 7 "GBDC_SUPERCHARGER_COMMS_TIMEOUT" 1 "GBDC_VEH_REQUESTED" ;
VAL_ 541 CP_iecComboState 6 "IEC_COMBO_CABLE_CHECK" 5 "IEC_COMBO_CHARGE_PARAM_DISCOVERY" 1 "IEC_COMBO_CONNECTED" 8 "IEC_COMBO_ENABLED" 10 "IEC_COMBO_END_OF_CHARGE" 11 "IEC_COMBO_FAULT" 0 "IEC_COMBO_INACTIVE" 4 "IEC_COMBO_PAYMENT_SELECTION" 7 "IEC_COMBO_PRECHARGE" 3 "IEC_COMBO_SERVICE_DISCOVERY" 9 "IEC_COMBO_SHUTDOWN" 2 "IEC_COMBO_V2G_SESSION_SETUP" 12 "IEC_COMBO_WAIT_RESTART" ;
VAL_ 541 CP_pilot 3 "CHG_PILOT_FAST_CHARGE" 1 "CHG_PILOT_FAULTED" 4 "CHG_PILOT_IDLE" 5 "CHG_PILOT_INVALID" 2 "CHG_PILOT_LINE_CHARGE" 0 "CHG_PILOT_NONE" 7 "CHG_PILOT_SNA" 6 "CHG_PILOT_UNUSED_6" ;
VAL_ 541 CP_proximity 1 "CHG_PROXIMITY_DISCONNECTED" 3 "CHG_PROXIMITY_LATCHED" 0 "CHG_PROXIMITY_SNA" 2 "CHG_PROXIMITY_UNLATCHED" ;
VAL_ 541 CP_teslaDcState 1 "TESLA_DC_CONNECTED_CHARGE_BLOCKED" 9 "TESLA_DC_EMERGENCY_SHUTDOWN" 6 "TESLA_DC_ENABLED" 7 "TESLA_DC_EVSE_SHUTDOWN" 5 "TESLA_DC_EXT_PRECHARGE_ACTIVE" 3 "TESLA_DC_EXT_TESTS_ENABLED" 4 "TESLA_DC_EXT_TEST_ACTIVE" 10 "TESLA_DC_FAULT" 0 "TESLA_DC_INACTIVE" 2 "TESLA_DC_STANDBY" 8 "TESLA_DC_VEH_SHUTDOWN" ;
VAL_ 541 CP_teslaSwcanState 1 "TESLA_SWCAN_ACCEPT" 3 "TESLA_SWCAN_ESTABLISHED" 4 "TESLA_SWCAN_FAULT" 5 "TESLA_SWCAN_GO_TO_SLEEP" 0 "TESLA_SWCAN_INACTIVE" 6 "TESLA_SWCAN_OFFBOARD_UPDATE_IN_PROGRESS" 2 "TESLA_SWCAN_RECEIVE" ;
VAL_ 1859 VCRIGHT_mirrorRecallStatus 2 "RECALL_COMPLETE" 3 "RECALL_INTERRUPTED" 1 "RECALL_IN_PROGRESS" 0 "RECALL_SNA" ;
VAL_ 1859 VCRIGHT_seatRecallStatus 2 "RECALL_COMPLETE" 3 "RECALL_INTERRUPTED" 1 "RECALL_IN_PROGRESS" 0 "RECALL_SNA" ;
VAL_ 1859 VCRIGHT_systemRecallStatus 2 "RECALL_COMPLETE" 3 "RECALL_INTERRUPTED" 1 "RECALL_IN_PROGRESS" 0 "RECALL_SNA" ;
VAL_ 1885 CP_sensorDataSelect 2 "CP_SENSOR_DOOR" 0 "CP_SENSOR_DOOR_COUNTS" 4 "CP_SENSOR_INDUCTIVE_DOOR" 12 "CP_SENSOR_INLET_HARNESS_ID" 3 "CP_SENSOR_LATCH" 9 "CP_SENSOR_PILOT" 10 "CP_SENSOR_PILOT2" 1 "CP_SENSOR_PIN_TEMP" 8 "CP_SENSOR_PROX" 11 "CP_SENSOR_PROX_GB" 7 "CP_SENSOR_RAILS" 5 "CP_SENSOR_SAFETY" 6 "CP_SENSOR_UHF" ;
VAL_ 1885 CP_inlet1HarnessIdState 1 "HARNESS_PEDIGREE_INVALID" 0 "HARNESS_PEDIGREE_UNKNOWN_SNA" 2 "HARNESS_PEDIGREE_VALID" ;
VAL_ 1885 CP_inlet2HarnessIdState 1 "HARNESS_PEDIGREE_INVALID" 0 "HARNESS_PEDIGREE_UNKNOWN_SNA" 2 "HARNESS_PEDIGREE_VALID" ;
VAL_ 819 UI_acChargeCurrentLimit 127 "SNA" ;
VAL_ 819 UI_brickBalancingDisabled 0 "FALSE" 1 "TRUE" ;
VAL_ 819 UI_brickVLoggingRequest 0 "FALSE" 1 "TRUE" ;
VAL_ 820 UI_limitMode 2 "LIMIT_FACTORY" 0 "LIMIT_NORMAL" 3 "LIMIT_SERVICE" 1 "LIMIT_VALET" ;
VAL_ 820 UI_motorOnMode 1 "MOTORONMODE_FRONT_ONLY" 0 "MOTORONMODE_NORMAL" 2 "MOTORONMODE_REAR_ONLY" ;
VAL_ 820 UI_pedalMap 0 "CHILL" 2 "PERFORMANCE" 1 "SPORT" ;
VAL_ 820 UI_speedLimit 255 "SNA" ;
VAL_ 820 UI_stoppingMode 1 "CREEP" 2 "HOLD" 0 "STANDARD" ;
VAL_ 820 UI_systemPowerLimit 31 "SNA" ;
VAL_ 820 UI_systemTorqueLimit 63 "SNA" ;
VAL_ 820 UI_wasteMode 2 "WASTE_TYPE_FULL" 0 "WASTE_TYPE_NONE" 1 "WASTE_TYPE_PARTIAL" ;
VAL_ 820 UI_wasteModeRegenLimit 3 "MAX_REGEN_CURRENT_0A" 2 "MAX_REGEN_CURRENT_10A" 1 "MAX_REGEN_CURRENT_30A" 0 "MAX_REGEN_CURRENT_MAX" ;
VAL_ 820 UI_closureConfirmed 1 "CONFIRMED_FRUNK" 0 "CONFIRMED_NONE" 2 "CONFIRMED_PROX" ;
VAL_ 577 VCFRONT_coolantAirPurgeBatState 1 "AIR_PURGE_STATE_ACTIVE" 2 "AIR_PURGE_STATE_COMPLETE" 0 "AIR_PURGE_STATE_INACTIVE" 3 "AIR_PURGE_STATE_INTERRUPTED" 4 "AIR_PURGE_STATE_PENDING" ;
VAL_ 577 VCFRONT_coolantFlowBatReason 4 "ACTIVE_MANAGER_BATT" 9 "ACTIVE_MANAGER_PT" 6 "BMS_FLOW_REQ" 1 "COOLANT_AIR_PURGE" 7 "DAS_FLOW_REQ" 13 "DIS_FLOW_REQ" 12 "DI_FLOW_REQ" 14 "HP_FLOW_REQ" 0 "NONE" 2 "NO_FLOW_REQ" 3 "OVERRIDE_BATT" 8 "OVERRIDE_PT" 5 "PASSIVE_MANAGER_BATT" 10 "PASSIVE_MANAGER_PT" 11 "PCS_FLOW_REQ" ;
VAL_ 577 VCFRONT_coolantFlowPTReason 4 "ACTIVE_MANAGER_BATT" 9 "ACTIVE_MANAGER_PT" 6 "BMS_FLOW_REQ" 1 "COOLANT_AIR_PURGE" 7 "DAS_FLOW_REQ" 13 "DIS_FLOW_REQ" 12 "DI_FLOW_REQ" 14 "HP_FLOW_REQ" 0 "NONE" 2 "NO_FLOW_REQ" 3 "OVERRIDE_BATT" 8 "OVERRIDE_PT" 5 "PASSIVE_MANAGER_BATT" 10 "PASSIVE_MANAGER_PT" 11 "PCS_FLOW_REQ" ;
VAL_ 577 VCFRONT_wasteHeatRequestType 2 "WASTE_TYPE_FULL" 0 "WASTE_TYPE_NONE" 1 "WASTE_TYPE_PARTIAL" ;
VAL_ 1493 DI_IGBTJunctTemp 255 "SNA" ;
VAL_ 1366 DIF_IGBTJunctTemp 255 "SNA" ;
VAL_ 2005 DIR_fluxState 5 "DI_FLUXSTATE_ENABLED" 9 "DI_FLUXSTATE_FAULT" 4 "DI_FLUXSTATE_FLUX_DOWN" 3 "DI_FLUXSTATE_FLUX_UP" 6 "DI_FLUXSTATE_ICONTROL" 2 "DI_FLUXSTATE_STANDBY" 0 "DI_FLUXSTATE_START" 10 "DI_FLUXSTATE_STATIONARY_WASTE" 1 "DI_FLUXSTATE_TEST" 7 "DI_FLUXSTATE_VCONTROL" ;
VAL_ 2005 DIR_gateDriveState 3 "PSTG_GD_STATE_CONFIGURED" 2 "PSTG_GD_STATE_CONFIGURING" 0 "PSTG_GD_STATE_INIT" 4 "PSTG_GD_STATE_NOT_CONFIGURED" 1 "PSTG_GD_STATE_SELFTEST" ;
VAL_ 2005 DIR_gateDriveSupplyState 0 "PSTG_GD_SUPPLY_DOWN" 3 "PSTG_GD_SUPPLY_FALLING" 1 "PSTG_GD_SUPPLY_RISING" 2 "PSTG_GD_SUPPLY_UP" ;
VAL_ 2005 DIR_magnetTempEst 0 "SNA" ;
VAL_ 2005 DIR_motorType 8 "DI_MOTOR_F1A" 10 "DI_MOTOR_F1AC" 11 "DI_MOTOR_F2AB" 12 "DI_MOTOR_F2AC" 13 "DI_MOTOR_F2AD" 14 "DI_MOTOR_F2AE" 26 "DI_MOTOR_F2AE_AL" 15 "DI_MOTOR_F2APMSRM" 17 "DI_MOTOR_IM100A" 19 "DI_MOTOR_IM100B" 22 "DI_MOTOR_IM130C" 24 "DI_MOTOR_IM130D" 25 "DI_MOTOR_IM130D_AL" 27 "DI_MOTOR_IM130D_AL_POSCO" 20 "DI_MOTOR_IM216A" 3 "DI_MOTOR_M7M3" 4 "DI_MOTOR_M7M4" 5 "DI_MOTOR_M7M5" 7 "DI_MOTOR_M7M6" 6 "DI_MOTOR_M8A" 16 "DI_MOTOR_PM216A" 18 "DI_MOTOR_PM216B" 21 "DI_MOTOR_PM216C" 30 "DI_MOTOR_PM216CSR" 31 "DI_MOTOR_PM216CSR_N42" 23 "DI_MOTOR_PM216D" 32 "DI_MOTOR_PM228B" 28 "DI_MOTOR_PM275B" 29 "DI_MOTOR_PM350B" 1 "DI_MOTOR_ROADSTER_BASE" 2 "DI_MOTOR_ROADSTER_SPORT" 0 "DI_MOTOR_SNA" 9 "DI_MOTOR_SSR1A" ;
VAL_ 2005 DIR_oilPumpPhaseVoltage 255 "SNA" ;
VAL_ 2005 DIR_oilPumpPressureEstimateMax 255 "SNA" ;
VAL_ 2005 DIR_oilPumpPressureExpectedMin 255 "SNA" ;
VAL_ 2005 DIR_powerStageSafeState 2 "PSTG_SAFESTATE_3PS_HIGH" 3 "PSTG_SAFESTATE_3PS_LOW" 1 "PSTG_SAFESTATE_ALL_OFF" 0 "PSTG_SAFESTATE_NONE" ;
VAL_ 2005 DIR_pwmState 1 "PWMSTATE_DPWM2" 2 "PWMSTATE_OPWM1" 3 "PWMSTATE_OPWM2" 0 "PWMSTATE_SVPWM" ;
VAL_ 2005 DIR_rotorOffsetLearningState 9 "ROL_NUM_STATES" 2 "ROL_STATE_ACCELERATE" 5 "ROL_STATE_CORRECT" 8 "ROL_STATE_DONE" 0 "ROL_STATE_INIT" 4 "ROL_STATE_MEASURE" 3 "ROL_STATE_SHIFT" 6 "ROL_STATE_VERIFY" 1 "ROL_STATE_WAIT" 7 "ROL_STATE_WRITE" ;
VAL_ 2005 DIR_ssmState 5 "SSM_STATE_ABORT" 4 "SSM_STATE_ENABLE" 8 "SSM_STATE_FAULT" 2 "SSM_STATE_IDLE" 7 "SSM_STATE_RETRY" 3 "SSM_STATE_STANDBY" 0 "SSM_STATE_START" 1 "SSM_STATE_UNAVAILABLE" 6 "SSM_STATE_WAIT_FOR_RETRY" ;
VAL_ 2005 DIR_tcMaxRequest 255 "SNA" ;
VAL_ 2005 DIR_tcMinRequest 255 "SNA" ;
VAL_ 2005 DIR_usmState 3 "USM_STATE_ABORT" 4 "USM_STATE_ENABLE" 5 "USM_STATE_FAULT" 2 "USM_STATE_RETRY" 1 "USM_STATE_STANDBY" 0 "USM_STATE_START" 6 "USM_STATE_UNAVAILABLE" 7 "USM_STATE_WAIT_FOR_RETRY" ;
VAL_ 1879 DIF_fluxState 5 "DI_FLUXSTATE_ENABLED" 9 "DI_FLUXSTATE_FAULT" 4 "DI_FLUXSTATE_FLUX_DOWN" 3 "DI_FLUXSTATE_FLUX_UP" 6 "DI_FLUXSTATE_ICONTROL" 2 "DI_FLUXSTATE_STANDBY" 0 "DI_FLUXSTATE_START" 10 "DI_FLUXSTATE_STATIONARY_WASTE" 1 "DI_FLUXSTATE_TEST" 7 "DI_FLUXSTATE_VCONTROL" ;
VAL_ 1879 DIF_gateDriveState 3 "PSTG_GD_STATE_CONFIGURED" 2 "PSTG_GD_STATE_CONFIGURING" 0 "PSTG_GD_STATE_INIT" 4 "PSTG_GD_STATE_NOT_CONFIGURED" 1 "PSTG_GD_STATE_SELFTEST" ;
VAL_ 1879 DIF_gateDriveSupplyState 0 "PSTG_GD_SUPPLY_DOWN" 3 "PSTG_GD_SUPPLY_FALLING" 1 "PSTG_GD_SUPPLY_RISING" 2 "PSTG_GD_SUPPLY_UP" ;
VAL_ 1879 DIF_magnetTempEst 0 "SNA" ;
VAL_ 1879 DIF_motorType 8 "DI_MOTOR_F1A" 10 "DI_MOTOR_F1AC" 11 "DI_MOTOR_F2AB" 12 "DI_MOTOR_F2AC" 13 "DI_MOTOR_F2AD" 14 "DI_MOTOR_F2AE" 26 "DI_MOTOR_F2AE_AL" 15 "DI_MOTOR_F2APMSRM" 17 "DI_MOTOR_IM100A" 19 "DI_MOTOR_IM100B" 22 "DI_MOTOR_IM130C" 24 "DI_MOTOR_IM130D" 25 "DI_MOTOR_IM130D_AL" 27 "DI_MOTOR_IM130D_AL_POSCO" 20 "DI_MOTOR_IM216A" 3 "DI_MOTOR_M7M3" 4 "DI_MOTOR_M7M4" 5 "DI_MOTOR_M7M5" 7 "DI_MOTOR_M7M6" 6 "DI_MOTOR_M8A" 16 "DI_MOTOR_PM216A" 18 "DI_MOTOR_PM216B" 21 "DI_MOTOR_PM216C" 30 "DI_MOTOR_PM216CSR" 31 "DI_MOTOR_PM216CSR_N42" 23 "DI_MOTOR_PM216D" 32 "DI_MOTOR_PM228B" 28 "DI_MOTOR_PM275B" 29 "DI_MOTOR_PM350B" 1 "DI_MOTOR_ROADSTER_BASE" 2 "DI_MOTOR_ROADSTER_SPORT" 0 "DI_MOTOR_SNA" 9 "DI_MOTOR_SSR1A" ;
VAL_ 1879 DIF_oilPumpPhaseVoltage 255 "SNA" ;
VAL_ 1879 DIF_oilPumpPressureEstimateMax 255 "SNA" ;
VAL_ 1879 DIF_oilPumpPressureExpectedMin 255 "SNA" ;
VAL_ 1879 DIF_powerStageSafeState 2 "PSTG_SAFESTATE_3PS_HIGH" 3 "PSTG_SAFESTATE_3PS_LOW" 1 "PSTG_SAFESTATE_ALL_OFF" 0 "PSTG_SAFESTATE_NONE" ;
VAL_ 1879 DIF_pwmState 1 "PWMSTATE_DPWM2" 2 "PWMSTATE_OPWM1" 3 "PWMSTATE_OPWM2" 0 "PWMSTATE_SVPWM" ;
VAL_ 1879 DIF_rotorOffsetLearningState 9 "ROL_NUM_STATES" 2 "ROL_STATE_ACCELERATE" 5 "ROL_STATE_CORRECT" 8 "ROL_STATE_DONE" 0 "ROL_STATE_INIT" 4 "ROL_STATE_MEASURE" 3 "ROL_STATE_SHIFT" 6 "ROL_STATE_VERIFY" 1 "ROL_STATE_WAIT" 7 "ROL_STATE_WRITE" ;
VAL_ 1879 DIF_ssmState 5 "SSM_STATE_ABORT" 4 "SSM_STATE_ENABLE" 8 "SSM_STATE_FAULT" 2 "SSM_STATE_IDLE" 7 "SSM_STATE_RETRY" 3 "SSM_STATE_STANDBY" 0 "SSM_STATE_START" 1 "SSM_STATE_UNAVAILABLE" 6 "SSM_STATE_WAIT_FOR_RETRY" ;
VAL_ 1879 DIF_tcMaxRequest 255 "SNA" ;
VAL_ 1879 DIF_tcMinRequest 255 "SNA" ;
VAL_ 1879 DIF_usmState 3 "USM_STATE_ABORT" 4 "USM_STATE_ENABLE" 5 "USM_STATE_FAULT" 2 "USM_STATE_RETRY" 1 "USM_STATE_STANDBY" 0 "USM_STATE_START" 6 "USM_STATE_UNAVAILABLE" 7 "USM_STATE_WAIT_FOR_RETRY" ;
VAL_ 694 DI_ptcStateUI 0 "FAULTED" 1 "BACKUP" 2 "ON" 3 "SNA" ;
VAL_ 694 DI_tractionControlModeUI 0 "NORMAL" 1 "SLIP_START" 2 "DEV_MODE_1" 3 "DEV_MODE_2" 4 "ROLLS_MODE" 5 "DYNO_MODE" 6 "OFFROAD_ASSIST" ;
VAL_ 545 VCFRONT_LVPowerStateIndex 0 "Mux0" 1 "Mux1" ;
VAL_ 545 VCFRONT_CMPDLVState 3 "LV_FAULT" 2 "LV_GOING_DOWN" 0 "LV_OFF" 1 "LV_ON" ;
VAL_ 545 VCFRONT_amplifierLVRequest 3 "LV_FAULT" 2 "LV_GOING_DOWN" 0 "LV_OFF" 1 "LV_ON" ;
VAL_ 545 VCFRONT_cpLVRequest 3 "LV_FAULT" 2 "LV_GOING_DOWN" 0 "LV_OFF" 1 "LV_ON" ;
VAL_ 545 VCFRONT_das1HighCurrentLVState 3 "LV_FAULT" 2 "LV_GOING_DOWN" 0 "LV_OFF" 1 "LV_ON" ;
VAL_ 545 VCFRONT_das2HighCurrentLVState 3 "LV_FAULT" 2 "LV_GOING_DOWN" 0 "LV_OFF" 1 "LV_ON" ;
VAL_ 545 VCFRONT_difLVState 3 "LV_FAULT" 2 "LV_GOING_DOWN" 0 "LV_OFF" 1 "LV_ON" ;
VAL_ 545 VCFRONT_dirLVRequest 3 "LV_FAULT" 2 "LV_GOING_DOWN" 0 "LV_OFF" 1 "LV_ON" ;
VAL_ 545 VCFRONT_epasLVState 3 "LV_FAULT" 2 "LV_GOING_DOWN" 0 "LV_OFF" 1 "LV_ON" ;
VAL_ 545 VCFRONT_espLVState 3 "LV_FAULT" 2 "LV_GOING_DOWN" 0 "LV_OFF" 1 "LV_ON" ;
VAL_ 545 VCFRONT_hvacCompLVState 3 "LV_FAULT" 2 "LV_GOING_DOWN" 0 "LV_OFF" 1 "LV_ON" ;
VAL_ 545 VCFRONT_hvcLVRequest 3 "LV_FAULT" 2 "LV_GOING_DOWN" 0 "LV_OFF" 1 "LV_ON" ;
VAL_ 545 VCFRONT_iBoosterLVState 3 "LV_FAULT" 2 "LV_GOING_DOWN" 0 "LV_OFF" 1 "LV_ON" ;
VAL_ 545 VCFRONT_ocsLVRequest 3 "LV_FAULT" 2 "LV_GOING_DOWN" 0 "LV_OFF" 1 "LV_ON" ;
VAL_ 545 VCFRONT_oilPumpFrontLVState 3 "LV_FAULT" 2 "LV_GOING_DOWN" 0 "LV_OFF" 1 "LV_ON" ;
VAL_ 545 VCFRONT_oilPumpRearLVRequest 3 "LV_FAULT" 2 "LV_GOING_DOWN" 0 "LV_OFF" 1 "LV_ON" ;
VAL_ 545 VCFRONT_parkLVState 3 "LV_FAULT" 2 "LV_GOING_DOWN" 0 "LV_OFF" 1 "LV_ON" ;
VAL_ 545 VCFRONT_pcsLVState 3 "LV_FAULT" 2 "LV_GOING_DOWN" 0 "LV_OFF" 1 "LV_ON" ;
VAL_ 545 VCFRONT_ptcLVRequest 3 "LV_FAULT" 2 "LV_GOING_DOWN" 0 "LV_OFF" 1 "LV_ON" ;
VAL_ 545 VCFRONT_radcLVState 3 "LV_FAULT" 2 "LV_GOING_DOWN" 0 "LV_OFF" 1 "LV_ON" ;
VAL_ 545 VCFRONT_rcmLVRequest 3 "LV_FAULT" 2 "LV_GOING_DOWN" 0 "LV_OFF" 1 "LV_ON" ;
VAL_ 545 VCFRONT_sccmLVRequest 3 "LV_FAULT" 2 "LV_GOING_DOWN" 0 "LV_OFF" 1 "LV_ON" ;
VAL_ 545 VCFRONT_tasLVState 3 "LV_FAULT" 2 "LV_GOING_DOWN" 0 "LV_OFF" 1 "LV_ON" ;
VAL_ 545 VCFRONT_tpmsLVRequest 3 "LV_FAULT" 2 "LV_GOING_DOWN" 0 "LV_OFF" 1 "LV_ON" ;
VAL_ 545 VCFRONT_tunerLVRequest 3 "LV_FAULT" 2 "LV_GOING_DOWN" 0 "LV_OFF" 1 "LV_ON" ;
VAL_ 545 VCFRONT_uiHiCurrentLVState 3 "LV_FAULT" 2 "LV_GOING_DOWN" 0 "LV_OFF" 1 "LV_ON" ;
VAL_ 545 VCFRONT_vcleftHiCurrentLVState 3 "LV_FAULT" 2 "LV_GOING_DOWN" 0 "LV_OFF" 1 "LV_ON" ;
VAL_ 545 VCFRONT_vcrightHiCurrentLVState 3 "LV_FAULT" 2 "LV_GOING_DOWN" 0 "LV_OFF" 1 "LV_ON" ;
VAL_ 549 VCRIGHT_amplifierLVState 3 "LV_FAULT" 2 "LV_GOING_DOWN" 0 "LV_OFF" 1 "LV_ON" ;
VAL_ 549 VCRIGHT_eFuseLockoutStatus 2 "EFUSE_LOCKOUT_STATUS_ACTIVE" 0 "EFUSE_LOCKOUT_STATUS_IDLE" 1 "EFUSE_LOCKOUT_STATUS_PENDING" ;
VAL_ 549 VCRIGHT_hvcLVState 3 "LV_FAULT" 2 "LV_GOING_DOWN" 0 "LV_OFF" 1 "LV_ON" ;
VAL_ 549 VCRIGHT_lumbarLVState 3 "LV_FAULT" 2 "LV_GOING_DOWN" 0 "LV_OFF" 1 "LV_ON" ;
VAL_ 549 VCRIGHT_ocsLVState 3 "LV_FAULT" 2 "LV_GOING_DOWN" 0 "LV_OFF" 1 "LV_ON" ;
VAL_ 549 VCRIGHT_ptcLVState 3 "LV_FAULT" 2 "LV_GOING_DOWN" 0 "LV_OFF" 1 "LV_ON" ;
VAL_ 549 VCRIGHT_rcmLVState 3 "LV_FAULT" 2 "LV_GOING_DOWN" 0 "LV_OFF" 1 "LV_ON" ;
VAL_ 549 VCRIGHT_rearOilPumpLVState 3 "LV_FAULT" 2 "LV_GOING_DOWN" 0 "LV_OFF" 1 "LV_ON" ;
VAL_ 549 VCRIGHT_tunerLVState 3 "LV_FAULT" 2 "LV_GOING_DOWN" 0 "LV_OFF" 1 "LV_ON" ;
VAL_ 549 VCRIGHT_vehiclePowerStateDBG 2 "VEHICLE_POWER_STATE_ACCESSORY" 1 "VEHICLE_POWER_STATE_CONDITIONING" 3 "VEHICLE_POWER_STATE_DRIVE" 0 "VEHICLE_POWER_STATE_OFF" ;
VAL_ 753 VCFRONT_eFuseDebugStatusIndex 8 "VCF_DBG_STS_AUTOPILOT_1" 9 "VCF_DBG_STS_AUTOPILOT_2" 4 "VCF_DBG_STS_EPAS3P" 5 "VCF_DBG_STS_EPAS3S" 6 "VCF_DBG_STS_ESP_MOTOR" 7 "VCF_DBG_STS_ESP_VALVE" 12 "VCF_DBG_STS_HEADLAMPS" 3 "VCF_DBG_STS_IBOOSTER" 18 "VCF_DBG_STS_INVALID" 17 "VCF_DBG_STS_LV_BATTERY_DEBUG" 16 "VCF_DBG_STS_MISC_RAILS" 2 "VCF_DBG_STS_PCS" 14 "VCF_DBG_STS_PUMPS" 15 "VCF_DBG_STS_RAILS_A_B" 10 "VCF_DBG_STS_SLEEP_BYPASS" 11 "VCF_DBG_STS_UI" 13 "VCF_DBG_STS_VBAT_FUSED_HIGH_CURRENT" 1 "VCF_DBG_STS_VCLEFT" 0 "VCF_DBG_STS_VCRIGHT" ;
VAL_ 753 VCFRONT_EPAS3PSelfTestResult 4 "EFUSE_SELF_TEST_EFUSE_RESULT_FAILED_EFUSE_OUTPUT_SHORT" 8 "EFUSE_SELF_TEST_EFUSE_RESULT_FAILED_ENABLE_HIGH_MALFUNCTION" 6 "EFUSE_SELF_TEST_EFUSE_RESULT_FAILED_ENABLE_LOW_MALFUNCTION" 10 "EFUSE_SELF_TEST_EFUSE_RESULT_FAILED_NOT_LATCHED" 7 "EFUSE_SELF_TEST_EFUSE_RESULT_FAILED_POWER_FET_CHANNEL_OPEN" 5 "EFUSE_SELF_TEST_EFUSE_RESULT_FAILED_POWER_FET_STUCK_ON" 3 "EFUSE_SELF_TEST_EFUSE_RESULT_FAILED_RAILS_UNSTABLE" 9 "EFUSE_SELF_TEST_EFUSE_RESULT_FAILED_TURN_OFF_PATH_TOO_SLOW" 0 "EFUSE_SELF_TEST_EFUSE_RESULT_NOT_RUN" 2 "EFUSE_SELF_TEST_EFUSE_RESULT_PASSED" 1 "EFUSE_SELF_TEST_EFUSE_RESULT_RUNNING" 11 "EFUSE_SELF_TEST_EFUSE_RESULT_SKIPPED" ;
VAL_ 753 VCFRONT_EPAS3PState 2 "EFUSE_STATE_LOCKED_OUT" 0 "EFUSE_STATE_OFF" 1 "EFUSE_STATE_ON" ;
VAL_ 753 VCFRONT_EPAS3SSelfTestResult 4 "EFUSE_SELF_TEST_EFUSE_RESULT_FAILED_EFUSE_OUTPUT_SHORT" 8 "EFUSE_SELF_TEST_EFUSE_RESULT_FAILED_ENABLE_HIGH_MALFUNCTION" 6 "EFUSE_SELF_TEST_EFUSE_RESULT_FAILED_ENABLE_LOW_MALFUNCTION" 10 "EFUSE_SELF_TEST_EFUSE_RESULT_FAILED_NOT_LATCHED" 7 "EFUSE_SELF_TEST_EFUSE_RESULT_FAILED_POWER_FET_CHANNEL_OPEN" 5 "EFUSE_SELF_TEST_EFUSE_RESULT_FAILED_POWER_FET_STUCK_ON" 3 "EFUSE_SELF_TEST_EFUSE_RESULT_FAILED_RAILS_UNSTABLE" 9 "EFUSE_SELF_TEST_EFUSE_RESULT_FAILED_TURN_OFF_PATH_TOO_SLOW" 0 "EFUSE_SELF_TEST_EFUSE_RESULT_NOT_RUN" 2 "EFUSE_SELF_TEST_EFUSE_RESULT_PASSED" 1 "EFUSE_SELF_TEST_EFUSE_RESULT_RUNNING" 11 "EFUSE_SELF_TEST_EFUSE_RESULT_SKIPPED" ;
VAL_ 753 VCFRONT_EPAS3SState 2 "EFUSE_STATE_LOCKED_OUT" 0 "EFUSE_STATE_OFF" 1 "EFUSE_STATE_ON" ;
VAL_ 753 VCFRONT_ESPMotorSelfTestResult 4 "EFUSE_SELF_TEST_EFUSE_RESULT_FAILED_EFUSE_OUTPUT_SHORT" 8 "EFUSE_SELF_TEST_EFUSE_RESULT_FAILED_ENABLE_HIGH_MALFUNCTION" 6 "EFUSE_SELF_TEST_EFUSE_RESULT_FAILED_ENABLE_LOW_MALFUNCTION" 10 "EFUSE_SELF_TEST_EFUSE_RESULT_FAILED_NOT_LATCHED" 7 "EFUSE_SELF_TEST_EFUSE_RESULT_FAILED_POWER_FET_CHANNEL_OPEN" 5 "EFUSE_SELF_TEST_EFUSE_RESULT_FAILED_POWER_FET_STUCK_ON" 3 "EFUSE_SELF_TEST_EFUSE_RESULT_FAILED_RAILS_UNSTABLE" 9 "EFUSE_SELF_TEST_EFUSE_RESULT_FAILED_TURN_OFF_PATH_TOO_SLOW" 0 "EFUSE_SELF_TEST_EFUSE_RESULT_NOT_RUN" 2 "EFUSE_SELF_TEST_EFUSE_RESULT_PASSED" 1 "EFUSE_SELF_TEST_EFUSE_RESULT_RUNNING" 11 "EFUSE_SELF_TEST_EFUSE_RESULT_SKIPPED" ;
VAL_ 753 VCFRONT_ESPMotorState 2 "EFUSE_STATE_LOCKED_OUT" 0 "EFUSE_STATE_OFF" 1 "EFUSE_STATE_ON" ;
VAL_ 753 VCFRONT_ESPValveState 2 "EFUSE_STATE_LOCKED_OUT" 0 "EFUSE_STATE_OFF" 1 "EFUSE_STATE_ON" ;
VAL_ 753 VCFRONT_PCSState 2 "EFUSE_STATE_LOCKED_OUT" 0 "EFUSE_STATE_OFF" 1 "EFUSE_STATE_ON" ;
VAL_ 753 VCFRONT_autopilot1State 2 "EFUSE_STATE_LOCKED_OUT" 0 "EFUSE_STATE_OFF" 1 "EFUSE_STATE_ON" ;
VAL_ 753 VCFRONT_autopilot2State 2 "EFUSE_STATE_LOCKED_OUT" 0 "EFUSE_STATE_OFF" 1 "EFUSE_STATE_ON" ;
VAL_ 753 VCFRONT_headlampLeftTemperature 128 "SNA" ;
VAL_ 753 VCFRONT_headlampLeftVoltage 255 "SNA" ;
VAL_ 753 VCFRONT_headlampRightTemperature 128 "SNA" ;
VAL_ 753 VCFRONT_headlampRightVoltage 255 "SNA" ;
VAL_ 753 VCFRONT_iBoosterSelfTestResult 4 "EFUSE_SELF_TEST_EFUSE_RESULT_FAILED_EFUSE_OUTPUT_SHORT" 8 "EFUSE_SELF_TEST_EFUSE_RESULT_FAILED_ENABLE_HIGH_MALFUNCTION" 6 "EFUSE_SELF_TEST_EFUSE_RESULT_FAILED_ENABLE_LOW_MALFUNCTION" 10 "EFUSE_SELF_TEST_EFUSE_RESULT_FAILED_NOT_LATCHED" 7 "EFUSE_SELF_TEST_EFUSE_RESULT_FAILED_POWER_FET_CHANNEL_OPEN" 5 "EFUSE_SELF_TEST_EFUSE_RESULT_FAILED_POWER_FET_STUCK_ON" 3 "EFUSE_SELF_TEST_EFUSE_RESULT_FAILED_RAILS_UNSTABLE" 9 "EFUSE_SELF_TEST_EFUSE_RESULT_FAILED_TURN_OFF_PATH_TOO_SLOW" 0 "EFUSE_SELF_TEST_EFUSE_RESULT_NOT_RUN" 2 "EFUSE_SELF_TEST_EFUSE_RESULT_PASSED" 1 "EFUSE_SELF_TEST_EFUSE_RESULT_RUNNING" 11 "EFUSE_SELF_TEST_EFUSE_RESULT_SKIPPED" ;
VAL_ 753 VCFRONT_iBoosterState 2 "EFUSE_STATE_LOCKED_OUT" 0 "EFUSE_STATE_OFF" 1 "EFUSE_STATE_ON" ;
VAL_ 753 VCFRONT_leftControllerState 2 "EFUSE_STATE_LOCKED_OUT" 0 "EFUSE_STATE_OFF" 1 "EFUSE_STATE_ON" ;
VAL_ 753 VCFRONT_pcsSelfTestResult 4 "EFUSE_SELF_TEST_EFUSE_RESULT_FAILED_EFUSE_OUTPUT_SHORT" 8 "EFUSE_SELF_TEST_EFUSE_RESULT_FAILED_ENABLE_HIGH_MALFUNCTION" 6 "EFUSE_SELF_TEST_EFUSE_RESULT_FAILED_ENABLE_LOW_MALFUNCTION" 10 "EFUSE_SELF_TEST_EFUSE_RESULT_FAILED_NOT_LATCHED" 7 "EFUSE_SELF_TEST_EFUSE_RESULT_FAILED_POWER_FET_CHANNEL_OPEN" 5 "EFUSE_SELF_TEST_EFUSE_RESULT_FAILED_POWER_FET_STUCK_ON" 3 "EFUSE_SELF_TEST_EFUSE_RESULT_FAILED_RAILS_UNSTABLE" 9 "EFUSE_SELF_TEST_EFUSE_RESULT_FAILED_TURN_OFF_PATH_TOO_SLOW" 0 "EFUSE_SELF_TEST_EFUSE_RESULT_NOT_RUN" 2 "EFUSE_SELF_TEST_EFUSE_RESULT_PASSED" 1 "EFUSE_SELF_TEST_EFUSE_RESULT_RUNNING" 11 "EFUSE_SELF_TEST_EFUSE_RESULT_SKIPPED" ;
VAL_ 753 VCFRONT_rightControllerState 2 "EFUSE_STATE_LOCKED_OUT" 0 "EFUSE_STATE_OFF" 1 "EFUSE_STATE_ON" ;
VAL_ 753 VCFRONT_vbatFusedSelfTestResult 4 "EFUSE_SELF_TEST_EFUSE_RESULT_FAILED_EFUSE_OUTPUT_SHORT" 8 "EFUSE_SELF_TEST_EFUSE_RESULT_FAILED_ENABLE_HIGH_MALFUNCTION" 6 "EFUSE_SELF_TEST_EFUSE_RESULT_FAILED_ENABLE_LOW_MALFUNCTION" 10 "EFUSE_SELF_TEST_EFUSE_RESULT_FAILED_NOT_LATCHED" 7 "EFUSE_SELF_TEST_EFUSE_RESULT_FAILED_POWER_FET_CHANNEL_OPEN" 5 "EFUSE_SELF_TEST_EFUSE_RESULT_FAILED_POWER_FET_STUCK_ON" 3 "EFUSE_SELF_TEST_EFUSE_RESULT_FAILED_RAILS_UNSTABLE" 9 "EFUSE_SELF_TEST_EFUSE_RESULT_FAILED_TURN_OFF_PATH_TOO_SLOW" 0 "EFUSE_SELF_TEST_EFUSE_RESULT_NOT_RUN" 2 "EFUSE_SELF_TEST_EFUSE_RESULT_PASSED" 1 "EFUSE_SELF_TEST_EFUSE_RESULT_RUNNING" 11 "EFUSE_SELF_TEST_EFUSE_RESULT_SKIPPED" ;
VAL_ 753 VCFRONT_vcleftSelfTestResult 4 "EFUSE_SELF_TEST_EFUSE_RESULT_FAILED_EFUSE_OUTPUT_SHORT" 8 "EFUSE_SELF_TEST_EFUSE_RESULT_FAILED_ENABLE_HIGH_MALFUNCTION" 6 "EFUSE_SELF_TEST_EFUSE_RESULT_FAILED_ENABLE_LOW_MALFUNCTION" 10 "EFUSE_SELF_TEST_EFUSE_RESULT_FAILED_NOT_LATCHED" 7 "EFUSE_SELF_TEST_EFUSE_RESULT_FAILED_POWER_FET_CHANNEL_OPEN" 5 "EFUSE_SELF_TEST_EFUSE_RESULT_FAILED_POWER_FET_STUCK_ON" 3 "EFUSE_SELF_TEST_EFUSE_RESULT_FAILED_RAILS_UNSTABLE" 9 "EFUSE_SELF_TEST_EFUSE_RESULT_FAILED_TURN_OFF_PATH_TOO_SLOW" 0 "EFUSE_SELF_TEST_EFUSE_RESULT_NOT_RUN" 2 "EFUSE_SELF_TEST_EFUSE_RESULT_PASSED" 1 "EFUSE_SELF_TEST_EFUSE_RESULT_RUNNING" 11 "EFUSE_SELF_TEST_EFUSE_RESULT_SKIPPED" ;
VAL_ 753 VCFRONT_vcrightSelfTestResult 4 "EFUSE_SELF_TEST_EFUSE_RESULT_FAILED_EFUSE_OUTPUT_SHORT" 8 "EFUSE_SELF_TEST_EFUSE_RESULT_FAILED_ENABLE_HIGH_MALFUNCTION" 6 "EFUSE_SELF_TEST_EFUSE_RESULT_FAILED_ENABLE_LOW_MALFUNCTION" 10 "EFUSE_SELF_TEST_EFUSE_RESULT_FAILED_NOT_LATCHED" 7 "EFUSE_SELF_TEST_EFUSE_RESULT_FAILED_POWER_FET_CHANNEL_OPEN" 5 "EFUSE_SELF_TEST_EFUSE_RESULT_FAILED_POWER_FET_STUCK_ON" 3 "EFUSE_SELF_TEST_EFUSE_RESULT_FAILED_RAILS_UNSTABLE" 9 "EFUSE_SELF_TEST_EFUSE_RESULT_FAILED_TURN_OFF_PATH_TOO_SLOW" 0 "EFUSE_SELF_TEST_EFUSE_RESULT_NOT_RUN" 2 "EFUSE_SELF_TEST_EFUSE_RESULT_PASSED" 1 "EFUSE_SELF_TEST_EFUSE_RESULT_RUNNING" 11 "EFUSE_SELF_TEST_EFUSE_RESULT_SKIPPED" ;
